VERSION "created by canmatrix"

NS_ :

BS_:

BU_: XCP_Tester FRS MN_K77
VAL_TABLE_ FRS_Fail 1 "FRS_RADAR_IS_WORKING" 0 "FRS_RADAR_ISNOT_WORKING" ;
VAL_TABLE_ FRS_MeasEnabled 1 "MEASUREMENT_ENABLED" 0 "MEASUREMENT_DISABLED" ;
VAL_TABLE_ FRS_ObjMotionPattern 7 "RESERVED" 6 "RESERVED" 5 "RESERVED" 4 "CROSSING" 3 "MOVING" 2 "STOPPED" 1 "STATIONARY" 0 "UNKNOWN" ;
VAL_TABLE_ FRS_Obj_ID 255 "INVALID" ;
VAL_TABLE_ FRS_Obj_MeasFlag 1 "OBJECT_EXTRAPOLATED_THIS_CYCLE" 0 "OBJECT_MEASURED_INTHIS_CYCLE" ;
VAL_TABLE_ FRS_Obj_Type 3 "PEDESTRAIN" 2 "TWO_WHEELER" 1 "FOUR_WHEELER" 0 "UNKNOWN" ;
VAL_TABLE_ FRS_Obj_UpdateFlag 1 "OBJECT_EXISTED_IN_PREVIOUS_CYCLE" 0 "NEW_OBJECT_INTHE_CYCLE" ;
VAL_TABLE_ FRS_Obj_ValidFlag 1 "OBJECT_VALID" 0 "OBJECT_INVALID" ;
VAL_TABLE_ FRS_Status_BlkProg 1 "FRS_IS_BLOCKED" 0 "FRS_IS_NOT_BLOCKED" ;
VAL_TABLE_ FRS_Status_HWErr 1 "HE_IS_FAILED" 0 "HW_IS_NOT_FAILED" ;
VAL_TABLE_ FRS_Status_MisAlign 7 "RESERVED" 6 "RESERVED" 5 "RESERVED" 4 "UNCALIBRATABLE" 3 "CALIBRATION_IN_PROGRESS" 2 "SENSOR_MISALIGNMENT_DETECTED" 1 "CALIBRATED" 0 "UNKNOWN" ;

BO_ 3221225472 VECTOR__INDEPENDENT_SIG_MSG: 0 Vector__XXX
 SG_ bkFramID : 0|32@0+ (1,0) [0|4294967295] "" Vector__XXX
 SG_ akFramID : 0|32@0+ (1,0) [0|4294967295] "" Vector__XXX
 SG_ mntAzmInFlash : 0|12@0- (0.01,0) [-20.48|20.47] "" Vector__XXX
 SG_ mntAzmRealTime : 0|12@0- (0.01,0) [-20.48|20.47] "" Vector__XXX
 SG_ RadarSubVehicle_VehilceType : 0|8@0+ (1,0) [0|15] "" Vector__XXX
 SG_ RadarSubVehicle_Yawrate : 0|16@0- (0.1,0) [-3276.8|3276.7] "deg/sec" Vector__XXX
 SG_ RadarSubVehicle_TurnSwitch : 0|2@0+ (1,0) [0|15] "" Vector__XXX
 SG_ RadarSubVehicle_Gear : 0|4@0+ (1,0) [0|15] "" Vector__XXX
 SG_ RadarSubVehicle_StrWheelAngle : 0|16@0- (0.05,0) [-1638.4|1638.35] "deg" Vector__XXX
 SG_ RadarSubVehicle_Speed : 0|16@0+ (0.01,0) [0|655.35] "m/s" Vector__XXX

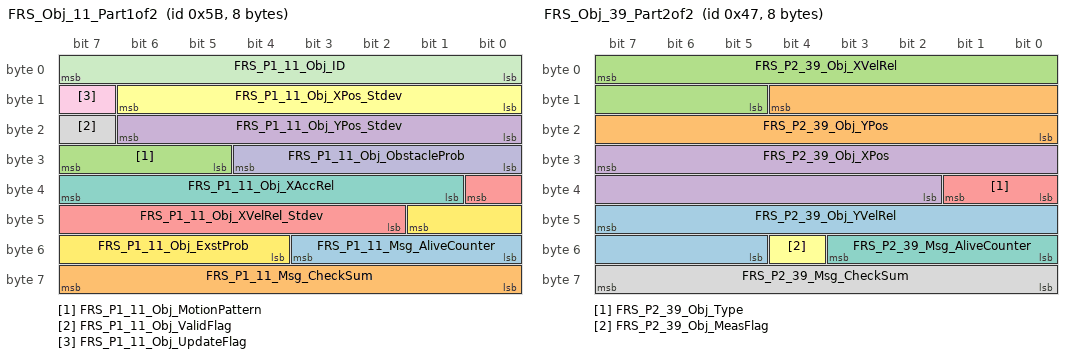
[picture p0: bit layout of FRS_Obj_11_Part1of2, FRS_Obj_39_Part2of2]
BO_ 91 FRS_Obj_11_Part1of2: 8 FRS
 SG_ FRS_P1_11_Msg_AliveCounter : 51|4@0+ (1,0) [0|15] "n/a" Vector__XXX
 SG_ FRS_P1_11_Msg_CheckSum : 63|8@0+ (1,0) [0|255] "n/a" Vector__XXX
 SG_ FRS_P1_11_Obj_MotionPattern : 31|3@0+ (1,0) [0|7] "n/a" Vector__XXX
 SG_ FRS_P1_11_Obj_YPos_Stdev : 22|7@0+ (0.1,0) [0|12.7] "m" Vector__XXX
 SG_ FRS_P1_11_Obj_XVelRel_Stdev : 32|7@0+ (0.05,0) [0|6.35] "m/s" Vector__XXX
 SG_ FRS_P1_11_Obj_XPos_Stdev : 14|7@0+ (0.1,0) [0|12.7] "m" Vector__XXX
 SG_ FRS_P1_11_Obj_XAccRel : 39|7@0+ (0.15,-9.6) [-9.6|9.45] "m/s2" Vector__XXX
 SG_ FRS_P1_11_Obj_ValidFlag : 23|1@0+ (1,0) [0|1] "n/a" Vector__XXX
 SG_ FRS_P1_11_Obj_UpdateFlag : 15|1@0+ (1,0) [0|1] "n/a" Vector__XXX
 SG_ FRS_P1_11_Obj_ObstacleProb : 28|5@0+ (3.2258,0) [0|99.9998] "%" Vector__XXX
 SG_ FRS_P1_11_Obj_ID : 7|8@0+ (1,0) [0|255] "n/a" Vector__XXX
 SG_ FRS_P1_11_Obj_ExstProb : 41|6@0+ (1.5873,0) [0|99.9999] "%" Vector__XXX

BO_ 71 FRS_Obj_39_Part2of2: 8 FRS
 SG_ FRS_P2_39_Obj_YVelRel : 47|11@0+ (0.1,-102.4) [-102.4|102.3] "m/s" Vector__XXX
 SG_ FRS_P2_39_Obj_YPos : 12|13@0+ (0.015625,-64) [-64|63.984375] "m" Vector__XXX
 SG_ FRS_P2_39_Obj_XVelRel : 7|11@0+ (0.1,-102.4) [-102.4|102.3] "m/s" Vector__XXX
 SG_ FRS_P2_39_Obj_XPos : 31|14@0+ (0.015625,0) [0|255.984375] "m" Vector__XXX
 SG_ FRS_P2_39_Obj_Type : 33|2@0+ (1,0) [0|3] "n/a" Vector__XXX
 SG_ FRS_P2_39_Obj_MeasFlag : 52|1@0+ (1,0) [0|1] "n/a" Vector__XXX
 SG_ FRS_P2_39_Msg_AliveCounter : 51|4@0+ (1,0) [0|15] "n/a" Vector__XXX
 SG_ FRS_P2_39_Msg_CheckSum : 63|8@0+ (1,0) [0|255] "n/a" Vector__XXX

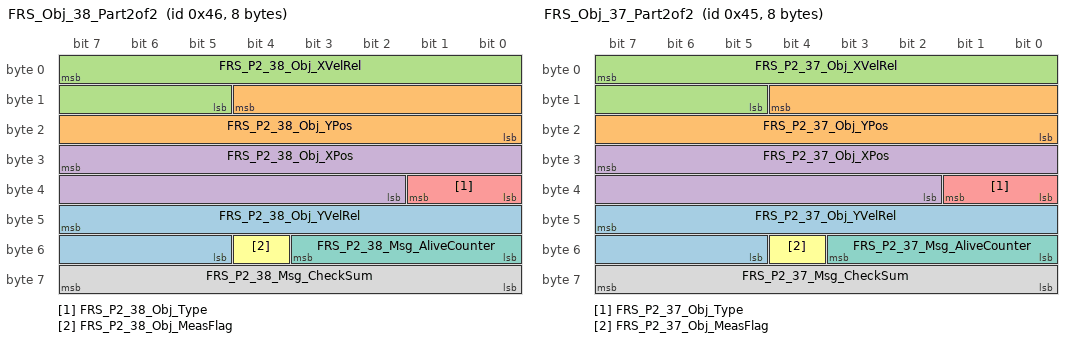
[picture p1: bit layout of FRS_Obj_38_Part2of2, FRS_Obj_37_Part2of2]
BO_ 70 FRS_Obj_38_Part2of2: 8 FRS
 SG_ FRS_P2_38_Obj_YVelRel : 47|11@0+ (0.1,-102.4) [-102.4|102.3] "m/s" Vector__XXX
 SG_ FRS_P2_38_Obj_YPos : 12|13@0+ (0.015625,-64) [-64|63.984375] "m" Vector__XXX
 SG_ FRS_P2_38_Obj_XVelRel : 7|11@0+ (0.1,-102.4) [-102.4|102.3] "m/s" Vector__XXX
 SG_ FRS_P2_38_Obj_XPos : 31|14@0+ (0.015625,0) [0|255.984375] "m" Vector__XXX
 SG_ FRS_P2_38_Obj_Type : 33|2@0+ (1,0) [0|3] "n/a" Vector__XXX
 SG_ FRS_P2_38_Obj_MeasFlag : 52|1@0+ (1,0) [0|1] "n/a" Vector__XXX
 SG_ FRS_P2_38_Msg_AliveCounter : 51|4@0+ (1,0) [0|15] "n/a" Vector__XXX
 SG_ FRS_P2_38_Msg_CheckSum : 63|8@0+ (1,0) [0|255] "n/a" Vector__XXX

BO_ 69 FRS_Obj_37_Part2of2: 8 FRS
 SG_ FRS_P2_37_Obj_YVelRel : 47|11@0+ (0.1,-102.4) [-102.4|102.3] "m/s" Vector__XXX
 SG_ FRS_P2_37_Obj_YPos : 12|13@0+ (0.015625,-64) [-64|63.984375] "m" Vector__XXX
 SG_ FRS_P2_37_Obj_XVelRel : 7|11@0+ (0.1,-102.4) [-102.4|102.3] "m/s" Vector__XXX
 SG_ FRS_P2_37_Obj_XPos : 31|14@0+ (0.015625,0) [0|255.984375] "m" Vector__XXX
 SG_ FRS_P2_37_Obj_Type : 33|2@0+ (1,0) [0|3] "n/a" Vector__XXX
 SG_ FRS_P2_37_Obj_MeasFlag : 52|1@0+ (1,0) [0|1] "n/a" Vector__XXX
 SG_ FRS_P2_37_Msg_AliveCounter : 51|4@0+ (1,0) [0|15] "n/a" Vector__XXX
 SG_ FRS_P2_37_Msg_CheckSum : 63|8@0+ (1,0) [0|255] "n/a" Vector__XXX

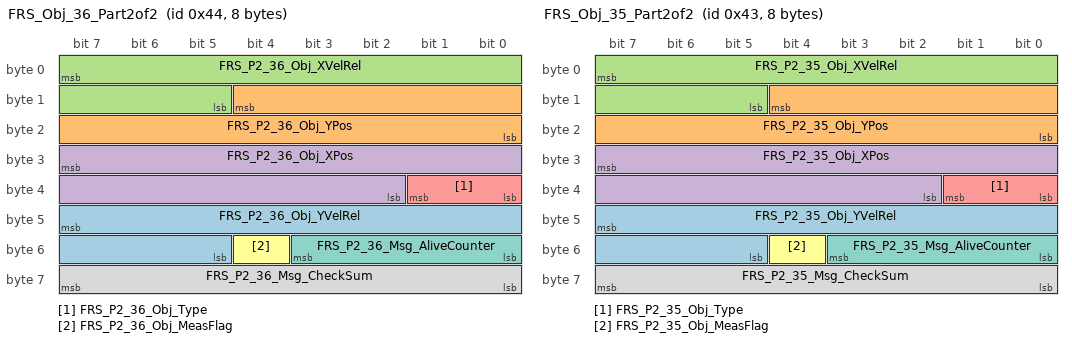
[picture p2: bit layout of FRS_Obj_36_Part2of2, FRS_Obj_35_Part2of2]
BO_ 68 FRS_Obj_36_Part2of2: 8 FRS
 SG_ FRS_P2_36_Obj_YVelRel : 47|11@0+ (0.1,-102.4) [-102.4|102.3] "m/s" Vector__XXX
 SG_ FRS_P2_36_Obj_YPos : 12|13@0+ (0.015625,-64) [-64|63.984375] "m" Vector__XXX
 SG_ FRS_P2_36_Obj_XVelRel : 7|11@0+ (0.1,-102.4) [-102.4|102.3] "m/s" Vector__XXX
 SG_ FRS_P2_36_Obj_XPos : 31|14@0+ (0.015625,0) [0|255.984375] "m" Vector__XXX
 SG_ FRS_P2_36_Obj_Type : 33|2@0+ (1,0) [0|3] "n/a" Vector__XXX
 SG_ FRS_P2_36_Obj_MeasFlag : 52|1@0+ (1,0) [0|1] "n/a" Vector__XXX
 SG_ FRS_P2_36_Msg_AliveCounter : 51|4@0+ (1,0) [0|15] "n/a" Vector__XXX
 SG_ FRS_P2_36_Msg_CheckSum : 63|8@0+ (1,0) [0|255] "n/a" Vector__XXX

BO_ 67 FRS_Obj_35_Part2of2: 8 FRS
 SG_ FRS_P2_35_Obj_YVelRel : 47|11@0+ (0.1,-102.4) [-102.4|102.3] "m/s" Vector__XXX
 SG_ FRS_P2_35_Obj_YPos : 12|13@0+ (0.015625,-64) [-64|63.984375] "m" Vector__XXX
 SG_ FRS_P2_35_Obj_XVelRel : 7|11@0+ (0.1,-102.4) [-102.4|102.3] "m/s" Vector__XXX
 SG_ FRS_P2_35_Obj_XPos : 31|14@0+ (0.015625,0) [0|255.984375] "m" Vector__XXX
 SG_ FRS_P2_35_Obj_Type : 33|2@0+ (1,0) [0|3] "n/a" Vector__XXX
 SG_ FRS_P2_35_Obj_MeasFlag : 52|1@0+ (1,0) [0|1] "n/a" Vector__XXX
 SG_ FRS_P2_35_Msg_AliveCounter : 51|4@0+ (1,0) [0|15] "n/a" Vector__XXX
 SG_ FRS_P2_35_Msg_CheckSum : 63|8@0+ (1,0) [0|255] "n/a" Vector__XXX

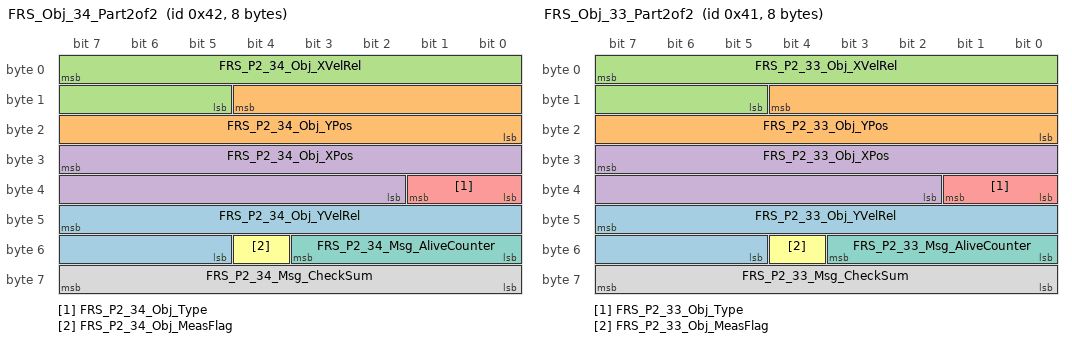
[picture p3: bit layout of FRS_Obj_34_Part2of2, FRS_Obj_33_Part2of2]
BO_ 66 FRS_Obj_34_Part2of2: 8 FRS
 SG_ FRS_P2_34_Obj_YVelRel : 47|11@0+ (0.1,-102.4) [-102.4|102.3] "m/s" Vector__XXX
 SG_ FRS_P2_34_Obj_YPos : 12|13@0+ (0.015625,-64) [-64|63.984375] "m" Vector__XXX
 SG_ FRS_P2_34_Obj_XVelRel : 7|11@0+ (0.1,-102.4) [-102.4|102.3] "m/s" Vector__XXX
 SG_ FRS_P2_34_Obj_XPos : 31|14@0+ (0.015625,0) [0|255.984375] "m" Vector__XXX
 SG_ FRS_P2_34_Obj_Type : 33|2@0+ (1,0) [0|3] "n/a" Vector__XXX
 SG_ FRS_P2_34_Obj_MeasFlag : 52|1@0+ (1,0) [0|1] "n/a" Vector__XXX
 SG_ FRS_P2_34_Msg_AliveCounter : 51|4@0+ (1,0) [0|15] "n/a" Vector__XXX
 SG_ FRS_P2_34_Msg_CheckSum : 63|8@0+ (1,0) [0|255] "n/a" Vector__XXX

BO_ 65 FRS_Obj_33_Part2of2: 8 FRS
 SG_ FRS_P2_33_Obj_YVelRel : 47|11@0+ (0.1,-102.4) [-102.4|102.3] "m/s" Vector__XXX
 SG_ FRS_P2_33_Obj_YPos : 12|13@0+ (0.015625,-64) [-64|63.984375] "m" Vector__XXX
 SG_ FRS_P2_33_Obj_XVelRel : 7|11@0+ (0.1,-102.4) [-102.4|102.3] "m/s" Vector__XXX
 SG_ FRS_P2_33_Obj_XPos : 31|14@0+ (0.015625,0) [0|255.984375] "m" Vector__XXX
 SG_ FRS_P2_33_Obj_Type : 33|2@0+ (1,0) [0|3] "n/a" Vector__XXX
 SG_ FRS_P2_33_Obj_MeasFlag : 52|1@0+ (1,0) [0|1] "n/a" Vector__XXX
 SG_ FRS_P2_33_Msg_AliveCounter : 51|4@0+ (1,0) [0|15] "n/a" Vector__XXX
 SG_ FRS_P2_33_Msg_CheckSum : 63|8@0+ (1,0) [0|255] "n/a" Vector__XXX

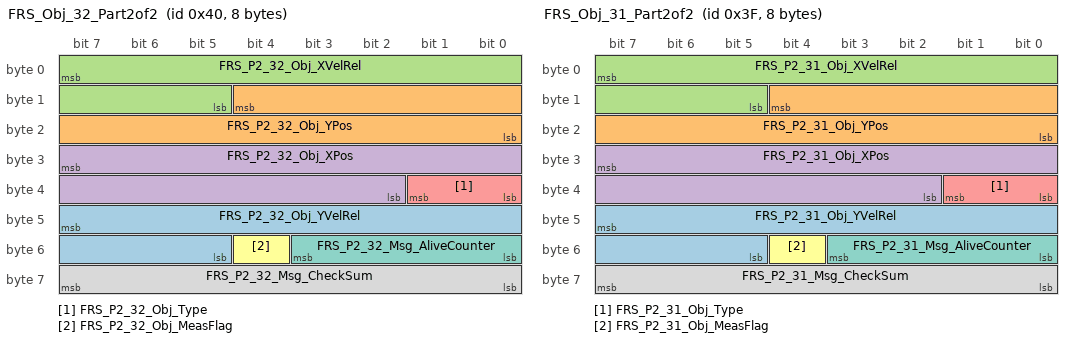
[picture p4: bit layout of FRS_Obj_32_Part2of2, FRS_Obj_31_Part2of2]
BO_ 64 FRS_Obj_32_Part2of2: 8 FRS
 SG_ FRS_P2_32_Obj_YVelRel : 47|11@0+ (0.1,-102.4) [-102.4|102.3] "m/s" Vector__XXX
 SG_ FRS_P2_32_Obj_YPos : 12|13@0+ (0.015625,-64) [-64|63.984375] "m" Vector__XXX
 SG_ FRS_P2_32_Obj_XVelRel : 7|11@0+ (0.1,-102.4) [-102.4|102.3] "m/s" Vector__XXX
 SG_ FRS_P2_32_Obj_XPos : 31|14@0+ (0.015625,0) [0|255.984375] "m" Vector__XXX
 SG_ FRS_P2_32_Obj_Type : 33|2@0+ (1,0) [0|3] "n/a" Vector__XXX
 SG_ FRS_P2_32_Obj_MeasFlag : 52|1@0+ (1,0) [0|1] "n/a" Vector__XXX
 SG_ FRS_P2_32_Msg_AliveCounter : 51|4@0+ (1,0) [0|15] "n/a" Vector__XXX
 SG_ FRS_P2_32_Msg_CheckSum : 63|8@0+ (1,0) [0|255] "n/a" Vector__XXX

BO_ 63 FRS_Obj_31_Part2of2: 8 FRS
 SG_ FRS_P2_31_Obj_YVelRel : 47|11@0+ (0.1,-102.4) [-102.4|102.3] "m/s" Vector__XXX
 SG_ FRS_P2_31_Obj_YPos : 12|13@0+ (0.015625,-64) [-64|63.984375] "m" Vector__XXX
 SG_ FRS_P2_31_Obj_XVelRel : 7|11@0+ (0.1,-102.4) [-102.4|102.3] "m/s" Vector__XXX
 SG_ FRS_P2_31_Obj_XPos : 31|14@0+ (0.015625,0) [0|255.984375] "m" Vector__XXX
 SG_ FRS_P2_31_Obj_Type : 33|2@0+ (1,0) [0|3] "n/a" Vector__XXX
 SG_ FRS_P2_31_Obj_MeasFlag : 52|1@0+ (1,0) [0|1] "n/a" Vector__XXX
 SG_ FRS_P2_31_Msg_AliveCounter : 51|4@0+ (1,0) [0|15] "n/a" Vector__XXX
 SG_ FRS_P2_31_Msg_CheckSum : 63|8@0+ (1,0) [0|255] "n/a" Vector__XXX

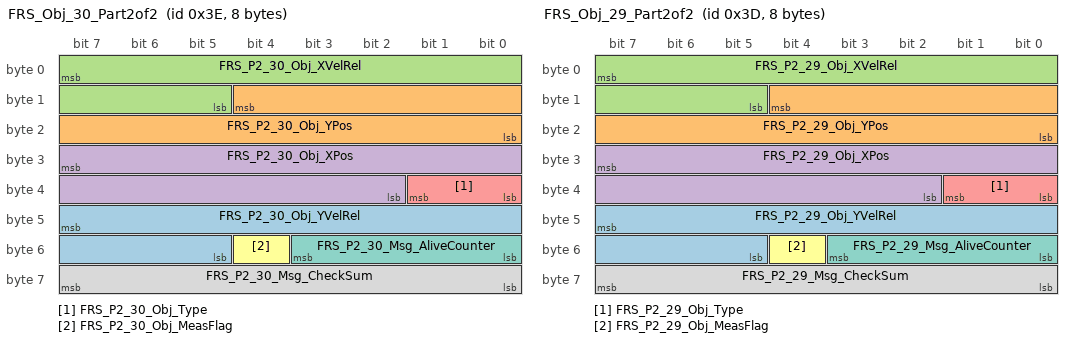
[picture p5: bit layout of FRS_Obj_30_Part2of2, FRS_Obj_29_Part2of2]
BO_ 62 FRS_Obj_30_Part2of2: 8 FRS
 SG_ FRS_P2_30_Obj_YVelRel : 47|11@0+ (0.1,-102.4) [-102.4|102.3] "m/s" Vector__XXX
 SG_ FRS_P2_30_Obj_YPos : 12|13@0+ (0.015625,-64) [-64|63.984375] "m" Vector__XXX
 SG_ FRS_P2_30_Obj_XVelRel : 7|11@0+ (0.1,-102.4) [-102.4|102.3] "m/s" Vector__XXX
 SG_ FRS_P2_30_Obj_XPos : 31|14@0+ (0.015625,0) [0|255.984375] "m" Vector__XXX
 SG_ FRS_P2_30_Obj_Type : 33|2@0+ (1,0) [0|3] "n/a" Vector__XXX
 SG_ FRS_P2_30_Obj_MeasFlag : 52|1@0+ (1,0) [0|1] "n/a" Vector__XXX
 SG_ FRS_P2_30_Msg_AliveCounter : 51|4@0+ (1,0) [0|15] "n/a" Vector__XXX
 SG_ FRS_P2_30_Msg_CheckSum : 63|8@0+ (1,0) [0|255] "n/a" Vector__XXX

BO_ 61 FRS_Obj_29_Part2of2: 8 FRS
 SG_ FRS_P2_29_Obj_YVelRel : 47|11@0+ (0.1,-102.4) [-102.4|102.3] "m/s" Vector__XXX
 SG_ FRS_P2_29_Obj_YPos : 12|13@0+ (0.015625,-64) [-64|63.984375] "m" Vector__XXX
 SG_ FRS_P2_29_Obj_XVelRel : 7|11@0+ (0.1,-102.4) [-102.4|102.3] "m/s" Vector__XXX
 SG_ FRS_P2_29_Obj_XPos : 31|14@0+ (0.015625,0) [0|255.984375] "m" Vector__XXX
 SG_ FRS_P2_29_Obj_Type : 33|2@0+ (1,0) [0|3] "n/a" Vector__XXX
 SG_ FRS_P2_29_Obj_MeasFlag : 52|1@0+ (1,0) [0|1] "n/a" Vector__XXX
 SG_ FRS_P2_29_Msg_AliveCounter : 51|4@0+ (1,0) [0|15] "n/a" Vector__XXX
 SG_ FRS_P2_29_Msg_CheckSum : 63|8@0+ (1,0) [0|255] "n/a" Vector__XXX

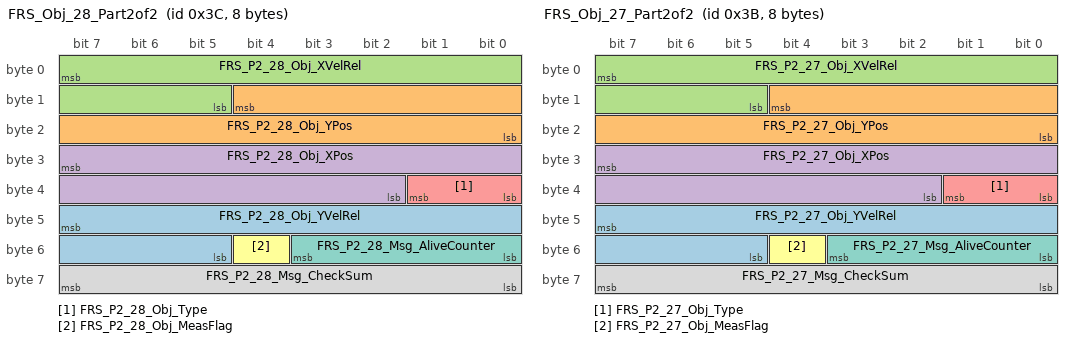
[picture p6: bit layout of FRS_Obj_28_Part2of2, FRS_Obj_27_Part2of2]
BO_ 60 FRS_Obj_28_Part2of2: 8 FRS
 SG_ FRS_P2_28_Obj_YVelRel : 47|11@0+ (0.1,-102.4) [-102.4|102.3] "m/s" Vector__XXX
 SG_ FRS_P2_28_Obj_YPos : 12|13@0+ (0.015625,-64) [-64|63.984375] "m" Vector__XXX
 SG_ FRS_P2_28_Obj_XVelRel : 7|11@0+ (0.1,-102.4) [-102.4|102.3] "m/s" Vector__XXX
 SG_ FRS_P2_28_Obj_XPos : 31|14@0+ (0.015625,0) [0|255.984375] "m" Vector__XXX
 SG_ FRS_P2_28_Obj_Type : 33|2@0+ (1,0) [0|3] "n/a" Vector__XXX
 SG_ FRS_P2_28_Obj_MeasFlag : 52|1@0+ (1,0) [0|1] "n/a" Vector__XXX
 SG_ FRS_P2_28_Msg_AliveCounter : 51|4@0+ (1,0) [0|15] "n/a" Vector__XXX
 SG_ FRS_P2_28_Msg_CheckSum : 63|8@0+ (1,0) [0|255] "n/a" Vector__XXX

BO_ 59 FRS_Obj_27_Part2of2: 8 FRS
 SG_ FRS_P2_27_Obj_YVelRel : 47|11@0+ (0.1,-102.4) [-102.4|102.3] "m/s" Vector__XXX
 SG_ FRS_P2_27_Obj_YPos : 12|13@0+ (0.015625,-64) [-64|63.984375] "m" Vector__XXX
 SG_ FRS_P2_27_Obj_XVelRel : 7|11@0+ (0.1,-102.4) [-102.4|102.3] "m/s" Vector__XXX
 SG_ FRS_P2_27_Obj_XPos : 31|14@0+ (0.015625,0) [0|255.984375] "m" Vector__XXX
 SG_ FRS_P2_27_Obj_Type : 33|2@0+ (1,0) [0|3] "n/a" Vector__XXX
 SG_ FRS_P2_27_Obj_MeasFlag : 52|1@0+ (1,0) [0|1] "n/a" Vector__XXX
 SG_ FRS_P2_27_Msg_AliveCounter : 51|4@0+ (1,0) [0|15] "n/a" Vector__XXX
 SG_ FRS_P2_27_Msg_CheckSum : 63|8@0+ (1,0) [0|255] "n/a" Vector__XXX

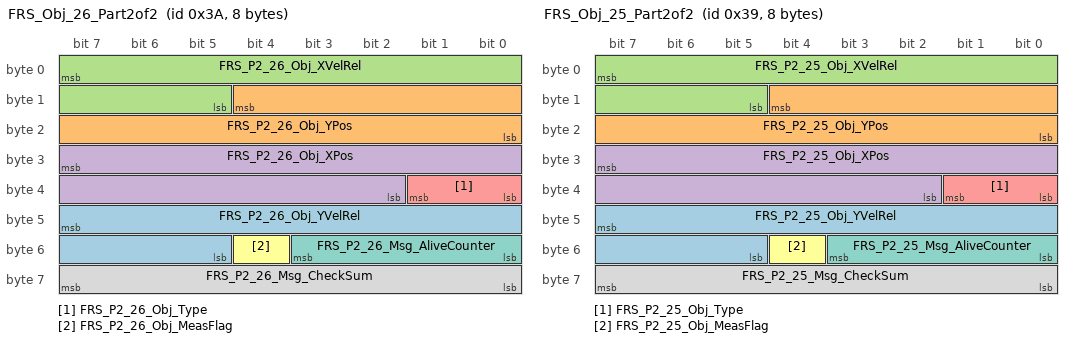
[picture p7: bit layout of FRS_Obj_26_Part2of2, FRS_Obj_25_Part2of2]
BO_ 58 FRS_Obj_26_Part2of2: 8 FRS
 SG_ FRS_P2_26_Obj_YVelRel : 47|11@0+ (0.1,-102.4) [-102.4|102.3] "m/s" Vector__XXX
 SG_ FRS_P2_26_Obj_YPos : 12|13@0+ (0.015625,-64) [-64|63.984375] "m" Vector__XXX
 SG_ FRS_P2_26_Obj_XVelRel : 7|11@0+ (0.1,-102.4) [-102.4|102.3] "m/s" Vector__XXX
 SG_ FRS_P2_26_Obj_XPos : 31|14@0+ (0.015625,0) [0|255.984375] "m" Vector__XXX
 SG_ FRS_P2_26_Obj_Type : 33|2@0+ (1,0) [0|3] "n/a" Vector__XXX
 SG_ FRS_P2_26_Obj_MeasFlag : 52|1@0+ (1,0) [0|1] "n/a" Vector__XXX
 SG_ FRS_P2_26_Msg_AliveCounter : 51|4@0+ (1,0) [0|15] "n/a" Vector__XXX
 SG_ FRS_P2_26_Msg_CheckSum : 63|8@0+ (1,0) [0|255] "n/a" Vector__XXX

BO_ 57 FRS_Obj_25_Part2of2: 8 FRS
 SG_ FRS_P2_25_Obj_YVelRel : 47|11@0+ (0.1,-102.4) [-102.4|102.3] "m/s" Vector__XXX
 SG_ FRS_P2_25_Obj_YPos : 12|13@0+ (0.015625,-64) [-64|63.984375] "m" Vector__XXX
 SG_ FRS_P2_25_Obj_XVelRel : 7|11@0+ (0.1,-102.4) [-102.4|102.3] "m/s" Vector__XXX
 SG_ FRS_P2_25_Obj_XPos : 31|14@0+ (0.015625,0) [0|255.984375] "m" Vector__XXX
 SG_ FRS_P2_25_Obj_Type : 33|2@0+ (1,0) [0|3] "n/a" Vector__XXX
 SG_ FRS_P2_25_Obj_MeasFlag : 52|1@0+ (1,0) [0|1] "n/a" Vector__XXX
 SG_ FRS_P2_25_Msg_AliveCounter : 51|4@0+ (1,0) [0|15] "n/a" Vector__XXX
 SG_ FRS_P2_25_Msg_CheckSum : 63|8@0+ (1,0) [0|255] "n/a" Vector__XXX

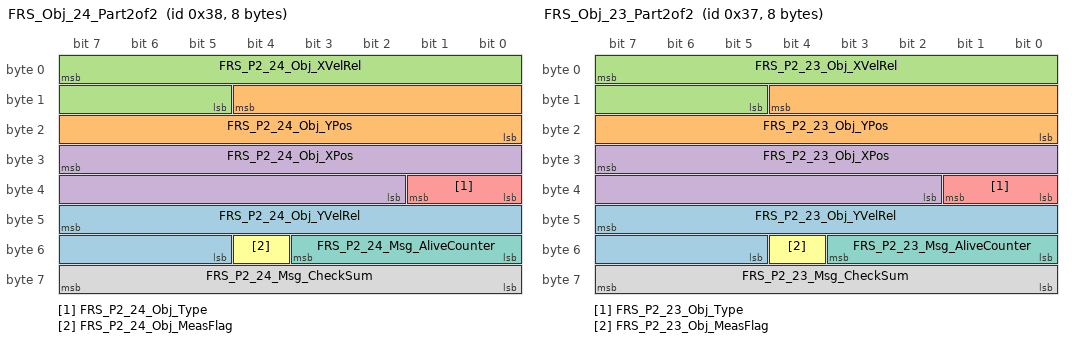
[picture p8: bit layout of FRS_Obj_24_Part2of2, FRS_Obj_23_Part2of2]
BO_ 56 FRS_Obj_24_Part2of2: 8 FRS
 SG_ FRS_P2_24_Obj_YVelRel : 47|11@0+ (0.1,-102.4) [-102.4|102.3] "m/s" Vector__XXX
 SG_ FRS_P2_24_Obj_YPos : 12|13@0+ (0.015625,-64) [-64|63.984375] "m" Vector__XXX
 SG_ FRS_P2_24_Obj_XVelRel : 7|11@0+ (0.1,-102.4) [-102.4|102.3] "m/s" Vector__XXX
 SG_ FRS_P2_24_Obj_XPos : 31|14@0+ (0.015625,0) [0|255.984375] "m" Vector__XXX
 SG_ FRS_P2_24_Obj_Type : 33|2@0+ (1,0) [0|3] "n/a" Vector__XXX
 SG_ FRS_P2_24_Obj_MeasFlag : 52|1@0+ (1,0) [0|1] "n/a" Vector__XXX
 SG_ FRS_P2_24_Msg_AliveCounter : 51|4@0+ (1,0) [0|15] "n/a" Vector__XXX
 SG_ FRS_P2_24_Msg_CheckSum : 63|8@0+ (1,0) [0|255] "n/a" Vector__XXX

BO_ 55 FRS_Obj_23_Part2of2: 8 FRS
 SG_ FRS_P2_23_Obj_YVelRel : 47|11@0+ (0.1,-102.4) [-102.4|102.3] "m/s" Vector__XXX
 SG_ FRS_P2_23_Obj_YPos : 12|13@0+ (0.015625,-64) [-64|63.984375] "m" Vector__XXX
 SG_ FRS_P2_23_Obj_XVelRel : 7|11@0+ (0.1,-102.4) [-102.4|102.3] "m/s" Vector__XXX
 SG_ FRS_P2_23_Obj_XPos : 31|14@0+ (0.015625,0) [0|255.984375] "m" Vector__XXX
 SG_ FRS_P2_23_Obj_Type : 33|2@0+ (1,0) [0|3] "n/a" Vector__XXX
 SG_ FRS_P2_23_Obj_MeasFlag : 52|1@0+ (1,0) [0|1] "n/a" Vector__XXX
 SG_ FRS_P2_23_Msg_AliveCounter : 51|4@0+ (1,0) [0|15] "n/a" Vector__XXX
 SG_ FRS_P2_23_Msg_CheckSum : 63|8@0+ (1,0) [0|255] "n/a" Vector__XXX

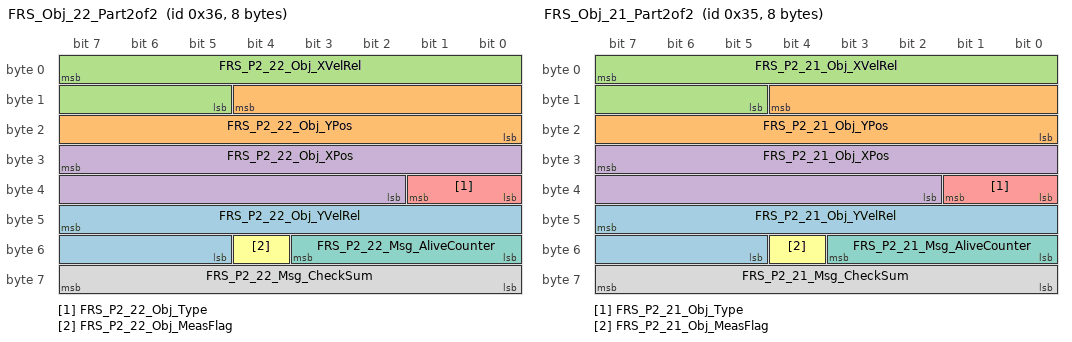
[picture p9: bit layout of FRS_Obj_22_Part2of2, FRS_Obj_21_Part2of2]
BO_ 54 FRS_Obj_22_Part2of2: 8 FRS
 SG_ FRS_P2_22_Obj_YVelRel : 47|11@0+ (0.1,-102.4) [-102.4|102.3] "m/s" Vector__XXX
 SG_ FRS_P2_22_Obj_YPos : 12|13@0+ (0.015625,-64) [-64|63.984375] "m" Vector__XXX
 SG_ FRS_P2_22_Obj_XVelRel : 7|11@0+ (0.1,-102.4) [-102.4|102.3] "m/s" Vector__XXX
 SG_ FRS_P2_22_Obj_XPos : 31|14@0+ (0.015625,0) [0|255.984375] "m" Vector__XXX
 SG_ FRS_P2_22_Obj_Type : 33|2@0+ (1,0) [0|3] "n/a" Vector__XXX
 SG_ FRS_P2_22_Obj_MeasFlag : 52|1@0+ (1,0) [0|1] "n/a" Vector__XXX
 SG_ FRS_P2_22_Msg_AliveCounter : 51|4@0+ (1,0) [0|15] "n/a" Vector__XXX
 SG_ FRS_P2_22_Msg_CheckSum : 63|8@0+ (1,0) [0|255] "n/a" Vector__XXX

BO_ 53 FRS_Obj_21_Part2of2: 8 FRS
 SG_ FRS_P2_21_Obj_YVelRel : 47|11@0+ (0.1,-102.4) [-102.4|102.3] "m/s" Vector__XXX
 SG_ FRS_P2_21_Obj_YPos : 12|13@0+ (0.015625,-64) [-64|63.984375] "m" Vector__XXX
 SG_ FRS_P2_21_Obj_XVelRel : 7|11@0+ (0.1,-102.4) [-102.4|102.3] "m/s" Vector__XXX
 SG_ FRS_P2_21_Obj_XPos : 31|14@0+ (0.015625,0) [0|255.984375] "m" Vector__XXX
 SG_ FRS_P2_21_Obj_Type : 33|2@0+ (1,0) [0|3] "n/a" Vector__XXX
 SG_ FRS_P2_21_Obj_MeasFlag : 52|1@0+ (1,0) [0|1] "n/a" Vector__XXX
 SG_ FRS_P2_21_Msg_AliveCounter : 51|4@0+ (1,0) [0|15] "n/a" Vector__XXX
 SG_ FRS_P2_21_Msg_CheckSum : 63|8@0+ (1,0) [0|255] "n/a" Vector__XXX

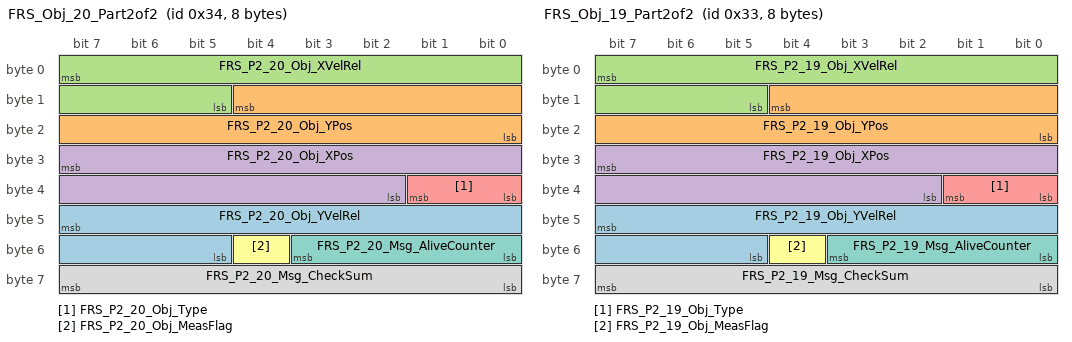
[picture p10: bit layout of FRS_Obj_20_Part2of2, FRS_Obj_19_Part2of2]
BO_ 52 FRS_Obj_20_Part2of2: 8 FRS
 SG_ FRS_P2_20_Obj_YVelRel : 47|11@0+ (0.1,-102.4) [-102.4|102.3] "m/s" Vector__XXX
 SG_ FRS_P2_20_Obj_YPos : 12|13@0+ (0.015625,-64) [-64|63.984375] "m" Vector__XXX
 SG_ FRS_P2_20_Obj_XVelRel : 7|11@0+ (0.1,-102.4) [-102.4|102.3] "m/s" Vector__XXX
 SG_ FRS_P2_20_Obj_XPos : 31|14@0+ (0.015625,0) [0|255.984375] "m" Vector__XXX
 SG_ FRS_P2_20_Obj_Type : 33|2@0+ (1,0) [0|3] "n/a" Vector__XXX
 SG_ FRS_P2_20_Obj_MeasFlag : 52|1@0+ (1,0) [0|1] "n/a" Vector__XXX
 SG_ FRS_P2_20_Msg_AliveCounter : 51|4@0+ (1,0) [0|15] "n/a" Vector__XXX
 SG_ FRS_P2_20_Msg_CheckSum : 63|8@0+ (1,0) [0|255] "n/a" Vector__XXX

BO_ 51 FRS_Obj_19_Part2of2: 8 FRS
 SG_ FRS_P2_19_Obj_YVelRel : 47|11@0+ (0.1,-102.4) [-102.4|102.3] "m/s" Vector__XXX
 SG_ FRS_P2_19_Obj_YPos : 12|13@0+ (0.015625,-64) [-64|63.984375] "m" Vector__XXX
 SG_ FRS_P2_19_Obj_XVelRel : 7|11@0+ (0.1,-102.4) [-102.4|102.3] "m/s" Vector__XXX
 SG_ FRS_P2_19_Obj_XPos : 31|14@0+ (0.015625,0) [0|255.984375] "m" Vector__XXX
 SG_ FRS_P2_19_Obj_Type : 33|2@0+ (1,0) [0|3] "n/a" Vector__XXX
 SG_ FRS_P2_19_Obj_MeasFlag : 52|1@0+ (1,0) [0|1] "n/a" Vector__XXX
 SG_ FRS_P2_19_Msg_AliveCounter : 51|4@0+ (1,0) [0|15] "n/a" Vector__XXX
 SG_ FRS_P2_19_Msg_CheckSum : 63|8@0+ (1,0) [0|255] "n/a" Vector__XXX

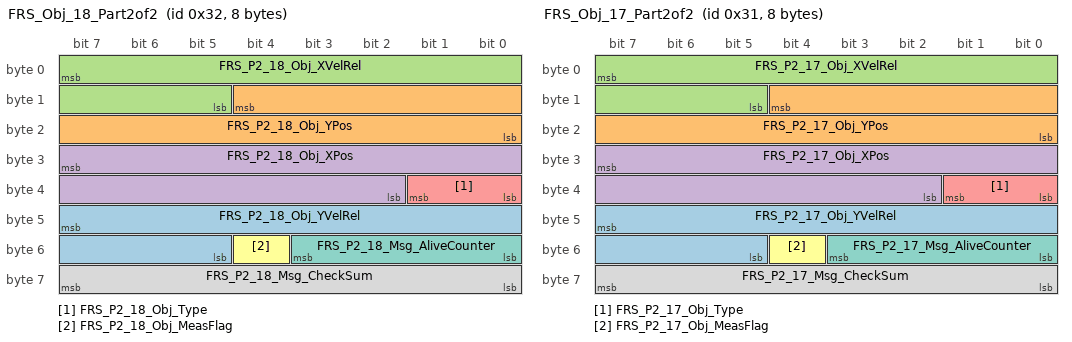
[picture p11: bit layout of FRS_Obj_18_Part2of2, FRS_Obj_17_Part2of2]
BO_ 50 FRS_Obj_18_Part2of2: 8 FRS
 SG_ FRS_P2_18_Obj_YVelRel : 47|11@0+ (0.1,-102.4) [-102.4|102.3] "m/s" Vector__XXX
 SG_ FRS_P2_18_Obj_YPos : 12|13@0+ (0.015625,-64) [-64|63.984375] "m" Vector__XXX
 SG_ FRS_P2_18_Obj_XVelRel : 7|11@0+ (0.1,-102.4) [-102.4|102.3] "m/s" Vector__XXX
 SG_ FRS_P2_18_Obj_XPos : 31|14@0+ (0.015625,0) [0|255.984375] "m" Vector__XXX
 SG_ FRS_P2_18_Obj_Type : 33|2@0+ (1,0) [0|3] "n/a" Vector__XXX
 SG_ FRS_P2_18_Obj_MeasFlag : 52|1@0+ (1,0) [0|1] "n/a" Vector__XXX
 SG_ FRS_P2_18_Msg_AliveCounter : 51|4@0+ (1,0) [0|15] "n/a" Vector__XXX
 SG_ FRS_P2_18_Msg_CheckSum : 63|8@0+ (1,0) [0|255] "n/a" Vector__XXX

BO_ 49 FRS_Obj_17_Part2of2: 8 FRS
 SG_ FRS_P2_17_Obj_YVelRel : 47|11@0+ (0.1,-102.4) [-102.4|102.3] "m/s" Vector__XXX
 SG_ FRS_P2_17_Obj_YPos : 12|13@0+ (0.015625,-64) [-64|63.984375] "m" Vector__XXX
 SG_ FRS_P2_17_Obj_XVelRel : 7|11@0+ (0.1,-102.4) [-102.4|102.3] "m/s" Vector__XXX
 SG_ FRS_P2_17_Obj_XPos : 31|14@0+ (0.015625,0) [0|255.984375] "m" Vector__XXX
 SG_ FRS_P2_17_Obj_Type : 33|2@0+ (1,0) [0|3] "n/a" Vector__XXX
 SG_ FRS_P2_17_Obj_MeasFlag : 52|1@0+ (1,0) [0|1] "n/a" Vector__XXX
 SG_ FRS_P2_17_Msg_AliveCounter : 51|4@0+ (1,0) [0|15] "n/a" Vector__XXX
 SG_ FRS_P2_17_Msg_CheckSum : 63|8@0+ (1,0) [0|255] "n/a" Vector__XXX

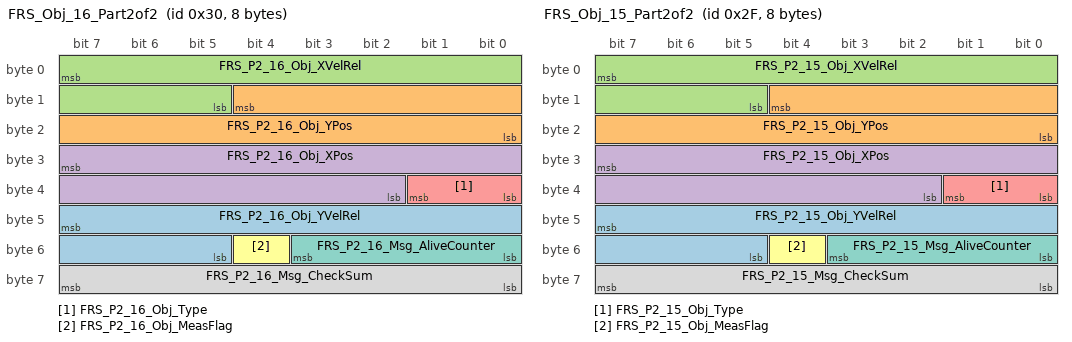
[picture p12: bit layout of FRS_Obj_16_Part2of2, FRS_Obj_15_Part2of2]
BO_ 48 FRS_Obj_16_Part2of2: 8 FRS
 SG_ FRS_P2_16_Obj_YVelRel : 47|11@0+ (0.1,-102.4) [-102.4|102.3] "m/s" Vector__XXX
 SG_ FRS_P2_16_Obj_YPos : 12|13@0+ (0.015625,-64) [-64|63.984375] "m" Vector__XXX
 SG_ FRS_P2_16_Obj_XVelRel : 7|11@0+ (0.1,-102.4) [-102.4|102.3] "m/s" Vector__XXX
 SG_ FRS_P2_16_Obj_XPos : 31|14@0+ (0.015625,0) [0|255.984375] "m" Vector__XXX
 SG_ FRS_P2_16_Obj_Type : 33|2@0+ (1,0) [0|3] "n/a" Vector__XXX
 SG_ FRS_P2_16_Obj_MeasFlag : 52|1@0+ (1,0) [0|1] "n/a" Vector__XXX
 SG_ FRS_P2_16_Msg_AliveCounter : 51|4@0+ (1,0) [0|15] "n/a" Vector__XXX
 SG_ FRS_P2_16_Msg_CheckSum : 63|8@0+ (1,0) [0|255] "n/a" Vector__XXX

BO_ 47 FRS_Obj_15_Part2of2: 8 FRS
 SG_ FRS_P2_15_Obj_YVelRel : 47|11@0+ (0.1,-102.4) [-102.4|102.3] "m/s" Vector__XXX
 SG_ FRS_P2_15_Obj_YPos : 12|13@0+ (0.015625,-64) [-64|63.984375] "m" Vector__XXX
 SG_ FRS_P2_15_Obj_XVelRel : 7|11@0+ (0.1,-102.4) [-102.4|102.3] "m/s" Vector__XXX
 SG_ FRS_P2_15_Obj_XPos : 31|14@0+ (0.015625,0) [0|255.984375] "m" Vector__XXX
 SG_ FRS_P2_15_Obj_Type : 33|2@0+ (1,0) [0|3] "n/a" Vector__XXX
 SG_ FRS_P2_15_Obj_MeasFlag : 52|1@0+ (1,0) [0|1] "n/a" Vector__XXX
 SG_ FRS_P2_15_Msg_AliveCounter : 51|4@0+ (1,0) [0|15] "n/a" Vector__XXX
 SG_ FRS_P2_15_Msg_CheckSum : 63|8@0+ (1,0) [0|255] "n/a" Vector__XXX

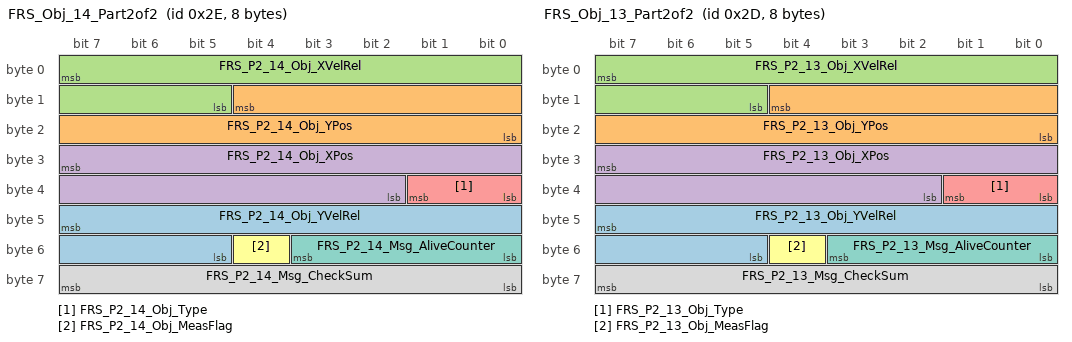
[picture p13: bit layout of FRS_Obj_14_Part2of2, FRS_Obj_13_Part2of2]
BO_ 46 FRS_Obj_14_Part2of2: 8 FRS
 SG_ FRS_P2_14_Obj_YVelRel : 47|11@0+ (0.1,-102.4) [-102.4|102.3] "m/s" Vector__XXX
 SG_ FRS_P2_14_Obj_YPos : 12|13@0+ (0.015625,-64) [-64|63.984375] "m" Vector__XXX
 SG_ FRS_P2_14_Obj_XVelRel : 7|11@0+ (0.1,-102.4) [-102.4|102.3] "m/s" Vector__XXX
 SG_ FRS_P2_14_Obj_XPos : 31|14@0+ (0.015625,0) [0|255.984375] "m" Vector__XXX
 SG_ FRS_P2_14_Obj_Type : 33|2@0+ (1,0) [0|3] "n/a" Vector__XXX
 SG_ FRS_P2_14_Obj_MeasFlag : 52|1@0+ (1,0) [0|1] "n/a" Vector__XXX
 SG_ FRS_P2_14_Msg_AliveCounter : 51|4@0+ (1,0) [0|15] "n/a" Vector__XXX
 SG_ FRS_P2_14_Msg_CheckSum : 63|8@0+ (1,0) [0|255] "n/a" Vector__XXX

BO_ 45 FRS_Obj_13_Part2of2: 8 FRS
 SG_ FRS_P2_13_Obj_YVelRel : 47|11@0+ (0.1,-102.4) [-102.4|102.3] "m/s" Vector__XXX
 SG_ FRS_P2_13_Obj_YPos : 12|13@0+ (0.015625,-64) [-64|63.984375] "m" Vector__XXX
 SG_ FRS_P2_13_Obj_XVelRel : 7|11@0+ (0.1,-102.4) [-102.4|102.3] "m/s" Vector__XXX
 SG_ FRS_P2_13_Obj_XPos : 31|14@0+ (0.015625,0) [0|255.984375] "m" Vector__XXX
 SG_ FRS_P2_13_Obj_Type : 33|2@0+ (1,0) [0|3] "n/a" Vector__XXX
 SG_ FRS_P2_13_Obj_MeasFlag : 52|1@0+ (1,0) [0|1] "n/a" Vector__XXX
 SG_ FRS_P2_13_Msg_AliveCounter : 51|4@0+ (1,0) [0|15] "n/a" Vector__XXX
 SG_ FRS_P2_13_Msg_CheckSum : 63|8@0+ (1,0) [0|255] "n/a" Vector__XXX

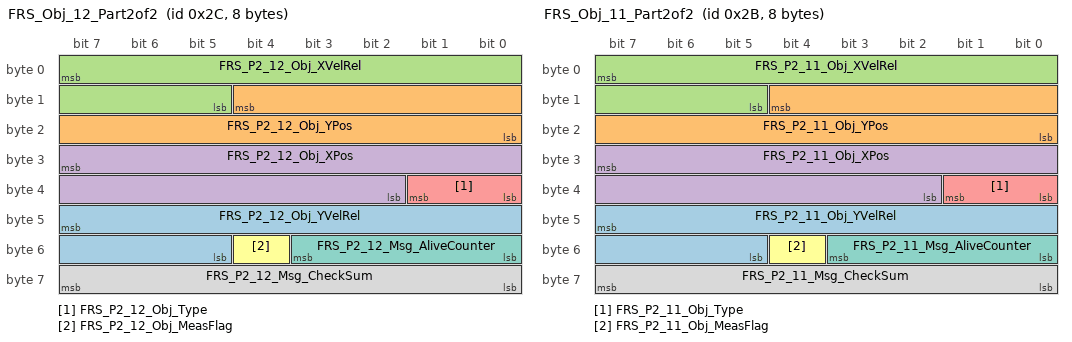
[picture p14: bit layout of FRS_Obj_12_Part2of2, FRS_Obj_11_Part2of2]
BO_ 44 FRS_Obj_12_Part2of2: 8 FRS
 SG_ FRS_P2_12_Obj_YVelRel : 47|11@0+ (0.1,-102.4) [-102.4|102.3] "m/s" Vector__XXX
 SG_ FRS_P2_12_Obj_YPos : 12|13@0+ (0.015625,-64) [-64|63.984375] "m" Vector__XXX
 SG_ FRS_P2_12_Obj_XVelRel : 7|11@0+ (0.1,-102.4) [-102.4|102.3] "m/s" Vector__XXX
 SG_ FRS_P2_12_Obj_XPos : 31|14@0+ (0.015625,0) [0|255.984375] "m" Vector__XXX
 SG_ FRS_P2_12_Obj_Type : 33|2@0+ (1,0) [0|3] "n/a" Vector__XXX
 SG_ FRS_P2_12_Obj_MeasFlag : 52|1@0+ (1,0) [0|1] "n/a" Vector__XXX
 SG_ FRS_P2_12_Msg_AliveCounter : 51|4@0+ (1,0) [0|15] "n/a" Vector__XXX
 SG_ FRS_P2_12_Msg_CheckSum : 63|8@0+ (1,0) [0|255] "n/a" Vector__XXX

BO_ 43 FRS_Obj_11_Part2of2: 8 FRS
 SG_ FRS_P2_11_Obj_YVelRel : 47|11@0+ (0.1,-102.4) [-102.4|102.3] "m/s" Vector__XXX
 SG_ FRS_P2_11_Obj_YPos : 12|13@0+ (0.015625,-64) [-64|63.984375] "m" Vector__XXX
 SG_ FRS_P2_11_Obj_XVelRel : 7|11@0+ (0.1,-102.4) [-102.4|102.3] "m/s" Vector__XXX
 SG_ FRS_P2_11_Obj_XPos : 31|14@0+ (0.015625,0) [0|255.984375] "m" Vector__XXX
 SG_ FRS_P2_11_Obj_Type : 33|2@0+ (1,0) [0|3] "n/a" Vector__XXX
 SG_ FRS_P2_11_Obj_MeasFlag : 52|1@0+ (1,0) [0|1] "n/a" Vector__XXX
 SG_ FRS_P2_11_Msg_AliveCounter : 51|4@0+ (1,0) [0|15] "n/a" Vector__XXX
 SG_ FRS_P2_11_Msg_CheckSum : 63|8@0+ (1,0) [0|255] "n/a" Vector__XXX

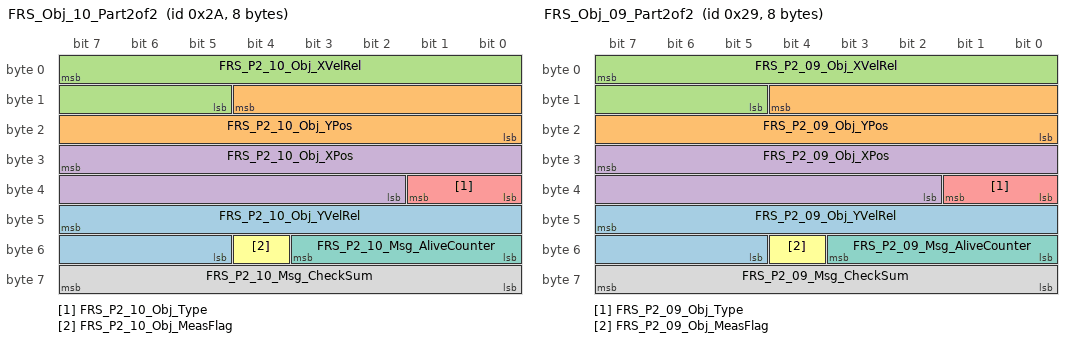
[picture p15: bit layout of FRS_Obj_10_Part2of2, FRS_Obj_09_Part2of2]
BO_ 42 FRS_Obj_10_Part2of2: 8 FRS
 SG_ FRS_P2_10_Obj_YVelRel : 47|11@0+ (0.1,-102.4) [-102.4|102.3] "m/s" Vector__XXX
 SG_ FRS_P2_10_Obj_YPos : 12|13@0+ (0.015625,-64) [-64|63.984375] "m" Vector__XXX
 SG_ FRS_P2_10_Obj_XVelRel : 7|11@0+ (0.1,-102.4) [-102.4|102.3] "m/s" Vector__XXX
 SG_ FRS_P2_10_Obj_XPos : 31|14@0+ (0.015625,0) [0|255.984375] "m" Vector__XXX
 SG_ FRS_P2_10_Obj_Type : 33|2@0+ (1,0) [0|3] "n/a" Vector__XXX
 SG_ FRS_P2_10_Obj_MeasFlag : 52|1@0+ (1,0) [0|1] "n/a" Vector__XXX
 SG_ FRS_P2_10_Msg_AliveCounter : 51|4@0+ (1,0) [0|15] "n/a" Vector__XXX
 SG_ FRS_P2_10_Msg_CheckSum : 63|8@0+ (1,0) [0|255] "n/a" Vector__XXX

BO_ 41 FRS_Obj_09_Part2of2: 8 FRS
 SG_ FRS_P2_09_Obj_YVelRel : 47|11@0+ (0.1,-102.4) [-102.4|102.3] "m/s" Vector__XXX
 SG_ FRS_P2_09_Obj_YPos : 12|13@0+ (0.015625,-64) [-64|63.984375] "m" Vector__XXX
 SG_ FRS_P2_09_Obj_XVelRel : 7|11@0+ (0.1,-102.4) [-102.4|102.3] "m/s" Vector__XXX
 SG_ FRS_P2_09_Obj_XPos : 31|14@0+ (0.015625,0) [0|255.984375] "m" Vector__XXX
 SG_ FRS_P2_09_Obj_Type : 33|2@0+ (1,0) [0|3] "n/a" Vector__XXX
 SG_ FRS_P2_09_Obj_MeasFlag : 52|1@0+ (1,0) [0|1] "n/a" Vector__XXX
 SG_ FRS_P2_09_Msg_AliveCounter : 51|4@0+ (1,0) [0|15] "n/a" Vector__XXX
 SG_ FRS_P2_09_Msg_CheckSum : 63|8@0+ (1,0) [0|255] "n/a" Vector__XXX

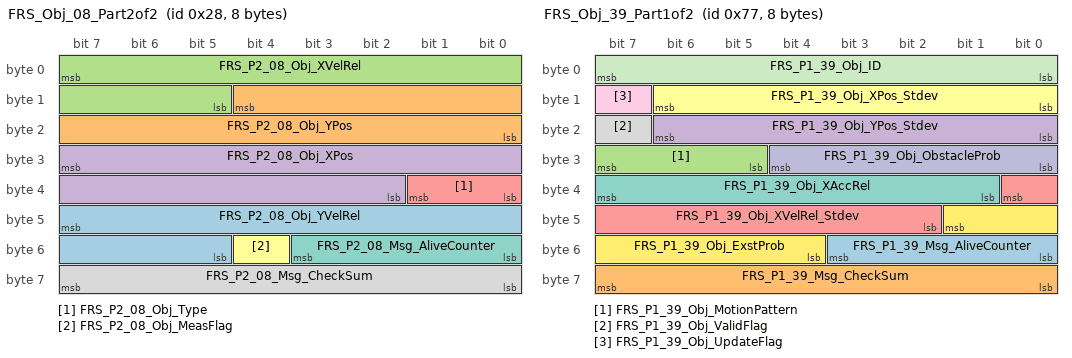
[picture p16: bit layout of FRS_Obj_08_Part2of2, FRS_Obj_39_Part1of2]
BO_ 40 FRS_Obj_08_Part2of2: 8 FRS
 SG_ FRS_P2_08_Obj_YVelRel : 47|11@0+ (0.1,-102.4) [-102.4|102.3] "m/s" Vector__XXX
 SG_ FRS_P2_08_Obj_YPos : 12|13@0+ (0.015625,-64) [-64|63.984375] "m" Vector__XXX
 SG_ FRS_P2_08_Obj_XVelRel : 7|11@0+ (0.1,-102.4) [-102.4|102.3] "m/s" Vector__XXX
 SG_ FRS_P2_08_Obj_XPos : 31|14@0+ (0.015625,0) [0|255.984375] "m" Vector__XXX
 SG_ FRS_P2_08_Obj_Type : 33|2@0+ (1,0) [0|3] "n/a" Vector__XXX
 SG_ FRS_P2_08_Obj_MeasFlag : 52|1@0+ (1,0) [0|1] "n/a" Vector__XXX
 SG_ FRS_P2_08_Msg_AliveCounter : 51|4@0+ (1,0) [0|15] "n/a" Vector__XXX
 SG_ FRS_P2_08_Msg_CheckSum : 63|8@0+ (1,0) [0|255] "n/a" Vector__XXX

BO_ 39 FRS_Obj_07_Part2of2: 8 FRS
 SG_ FRS_P2_07_Obj_YVelRel : 47|11@0+ (0.1,-102.4) [-102.4|102.3] "m/s" Vector__XXX
 SG_ FRS_P2_07_Obj_YPos : 12|13@0+ (0.015625,-64) [-64|63.984375] "m" Vector__XXX
 SG_ FRS_P2_07_Obj_XVelRel : 7|11@0+ (0.1,-102.4) [-102.4|102.3] "m/s" Vector__XXX
 SG_ FRS_P2_07_Obj_XPos : 31|14@0+ (0.015625,0) [0|255.984375] "m" Vector__XXX
 SG_ FRS_P2_07_Obj_Type : 33|2@0+ (1,0) [0|3] "n/a" Vector__XXX
 SG_ FRS_P2_07_Obj_MeasFlag : 52|1@0+ (1,0) [0|1] "n/a" Vector__XXX
 SG_ FRS_P2_07_Msg_AliveCounter : 51|4@0+ (1,0) [0|15] "n/a" Vector__XXX
 SG_ FRS_P2_07_Msg_CheckSum : 63|8@0+ (1,0) [0|255] "n/a" Vector__XXX

BO_ 38 FRS_Obj_06_Part2of2: 8 FRS
 SG_ FRS_P2_06_Obj_YVelRel : 47|11@0+ (0.1,-102.4) [-102.4|102.3] "m/s" Vector__XXX
 SG_ FRS_P2_06_Obj_YPos : 12|13@0+ (0.015625,-64) [-64|63.984375] "m" Vector__XXX
 SG_ FRS_P2_06_Obj_XVelRel : 7|11@0+ (0.1,-102.4) [-102.4|102.3] "m/s" Vector__XXX
 SG_ FRS_P2_06_Obj_XPos : 31|14@0+ (0.015625,0) [0|255.984375] "m" Vector__XXX
 SG_ FRS_P2_06_Obj_Type : 33|2@0+ (1,0) [0|3] "n/a" Vector__XXX
 SG_ FRS_P2_06_Obj_MeasFlag : 52|1@0+ (1,0) [0|1] "n/a" Vector__XXX
 SG_ FRS_P2_06_Msg_AliveCounter : 51|4@0+ (1,0) [0|15] "n/a" Vector__XXX
 SG_ FRS_P2_06_Msg_CheckSum : 63|8@0+ (1,0) [0|255] "n/a" Vector__XXX

BO_ 37 FRS_Obj_05_Part2of2: 8 FRS
 SG_ FRS_P2_05_Obj_YVelRel : 47|11@0+ (0.1,-102.4) [-102.4|102.3] "m/s" Vector__XXX
 SG_ FRS_P2_05_Obj_YPos : 12|13@0+ (0.015625,-64) [-64|63.984375] "m" Vector__XXX
 SG_ FRS_P2_05_Obj_XVelRel : 7|11@0+ (0.1,-102.4) [-102.4|102.3] "m/s" Vector__XXX
 SG_ FRS_P2_05_Obj_XPos : 31|14@0+ (0.015625,0) [0|255.984375] "m" Vector__XXX
 SG_ FRS_P2_05_Obj_Type : 33|2@0+ (1,0) [0|3] "n/a" Vector__XXX
 SG_ FRS_P2_05_Obj_MeasFlag : 52|1@0+ (1,0) [0|1] "n/a" Vector__XXX
 SG_ FRS_P2_05_Msg_AliveCounter : 51|4@0+ (1,0) [0|15] "n/a" Vector__XXX
 SG_ FRS_P2_05_Msg_CheckSum : 63|8@0+ (1,0) [0|255] "n/a" Vector__XXX

BO_ 36 FRS_Obj_04_Part2of2: 8 FRS
 SG_ FRS_P2_04_Obj_YVelRel : 47|11@0+ (0.1,-102.4) [-102.4|102.3] "m/s" Vector__XXX
 SG_ FRS_P2_04_Obj_YPos : 12|13@0+ (0.015625,-64) [-64|63.984375] "m" Vector__XXX
 SG_ FRS_P2_04_Obj_XVelRel : 7|11@0+ (0.1,-102.4) [-102.4|102.3] "m/s" Vector__XXX
 SG_ FRS_P2_04_Obj_XPos : 31|14@0+ (0.015625,0) [0|255.984375] "m" Vector__XXX
 SG_ FRS_P2_04_Obj_Type : 33|2@0+ (1,0) [0|3] "n/a" Vector__XXX
 SG_ FRS_P2_04_Obj_MeasFlag : 52|1@0+ (1,0) [0|1] "n/a" Vector__XXX
 SG_ FRS_P2_04_Msg_AliveCounter : 51|4@0+ (1,0) [0|15] "n/a" Vector__XXX
 SG_ FRS_P2_04_Msg_CheckSum : 63|8@0+ (1,0) [0|255] "n/a" Vector__XXX

BO_ 35 FRS_Obj_03_Part2of2: 8 FRS
 SG_ FRS_P2_03_Obj_YVelRel : 47|11@0+ (0.1,-102.4) [-102.4|102.3] "m/s" Vector__XXX
 SG_ FRS_P2_03_Obj_YPos : 12|13@0+ (0.015625,-64) [-64|63.984375] "m" Vector__XXX
 SG_ FRS_P2_03_Obj_XVelRel : 7|11@0+ (0.1,-102.4) [-102.4|102.3] "m/s" Vector__XXX
 SG_ FRS_P2_03_Obj_XPos : 31|14@0+ (0.015625,0) [0|255.984375] "m" Vector__XXX
 SG_ FRS_P2_03_Obj_Type : 33|2@0+ (1,0) [0|3] "n/a" Vector__XXX
 SG_ FRS_P2_03_Obj_MeasFlag : 52|1@0+ (1,0) [0|1] "n/a" Vector__XXX
 SG_ FRS_P2_03_Msg_AliveCounter : 51|4@0+ (1,0) [0|15] "n/a" Vector__XXX
 SG_ FRS_P2_03_Msg_CheckSum : 63|8@0+ (1,0) [0|255] "n/a" Vector__XXX

BO_ 34 FRS_Obj_02_Part2of2: 8 FRS
 SG_ FRS_P2_02_Obj_YVelRel : 47|11@0+ (0.1,-102.4) [-102.4|102.3] "m/s" Vector__XXX
 SG_ FRS_P2_02_Obj_YPos : 12|13@0+ (0.015625,-64) [-64|63.984375] "m" Vector__XXX
 SG_ FRS_P2_02_Obj_XVelRel : 7|11@0+ (0.1,-102.4) [-102.4|102.3] "m/s" Vector__XXX
 SG_ FRS_P2_02_Obj_XPos : 31|14@0+ (0.015625,0) [0|255.984375] "m" Vector__XXX
 SG_ FRS_P2_02_Obj_Type : 33|2@0+ (1,0) [0|3] "n/a" Vector__XXX
 SG_ FRS_P2_02_Obj_MeasFlag : 52|1@0+ (1,0) [0|1] "n/a" Vector__XXX
 SG_ FRS_P2_02_Msg_AliveCounter : 51|4@0+ (1,0) [0|15] "n/a" Vector__XXX
 SG_ FRS_P2_02_Msg_CheckSum : 63|8@0+ (1,0) [0|255] "n/a" Vector__XXX

BO_ 33 FRS_Obj_01_Part2of2: 8 FRS
 SG_ FRS_P2_01_Obj_YVelRel : 47|11@0+ (0.1,-102.4) [-102.4|102.3] "m/s" Vector__XXX
 SG_ FRS_P2_01_Obj_YPos : 12|13@0+ (0.015625,-64) [-64|63.984375] "m" Vector__XXX
 SG_ FRS_P2_01_Obj_XVelRel : 7|11@0+ (0.1,-102.4) [-102.4|102.3] "m/s" Vector__XXX
 SG_ FRS_P2_01_Obj_XPos : 31|14@0+ (0.015625,0) [0|255.984375] "m" Vector__XXX
 SG_ FRS_P2_01_Obj_Type : 33|2@0+ (1,0) [0|3] "n/a" Vector__XXX
 SG_ FRS_P2_01_Obj_MeasFlag : 52|1@0+ (1,0) [0|1] "n/a" Vector__XXX
 SG_ FRS_P2_01_Msg_AliveCounter : 51|4@0+ (1,0) [0|15] "n/a" Vector__XXX
 SG_ FRS_P2_01_Msg_CheckSum : 63|8@0+ (1,0) [0|255] "n/a" Vector__XXX

BO_ 119 FRS_Obj_39_Part1of2: 8 FRS
 SG_ FRS_P1_39_Msg_AliveCounter : 51|4@0+ (1,0) [0|15] "n/a" Vector__XXX
 SG_ FRS_P1_39_Msg_CheckSum : 63|8@0+ (1,0) [0|255] "n/a" Vector__XXX
 SG_ FRS_P1_39_Obj_MotionPattern : 31|3@0+ (1,0) [0|7] "n/a" Vector__XXX
 SG_ FRS_P1_39_Obj_YPos_Stdev : 22|7@0+ (0.1,0) [0|12.7] "m" Vector__XXX
 SG_ FRS_P1_39_Obj_XVelRel_Stdev : 32|7@0+ (0.05,0) [0|6.35] "m/s" Vector__XXX
 SG_ FRS_P1_39_Obj_XPos_Stdev : 14|7@0+ (0.1,0) [0|12.7] "m" Vector__XXX
 SG_ FRS_P1_39_Obj_XAccRel : 39|7@0+ (0.15,-9.6) [-9.6|9.45] "m/s2" Vector__XXX
 SG_ FRS_P1_39_Obj_ValidFlag : 23|1@0+ (1,0) [0|1] "n/a" Vector__XXX
 SG_ FRS_P1_39_Obj_UpdateFlag : 15|1@0+ (1,0) [0|1] "n/a" Vector__XXX
 SG_ FRS_P1_39_Obj_ObstacleProb : 28|5@0+ (3.2258,0) [0|99.9998] "%" Vector__XXX
 SG_ FRS_P1_39_Obj_ID : 7|8@0+ (1,0) [0|255] "n/a" Vector__XXX
 SG_ FRS_P1_39_Obj_ExstProb : 41|6@0+ (1.5873,0) [0|99.9999] "%" Vector__XXX

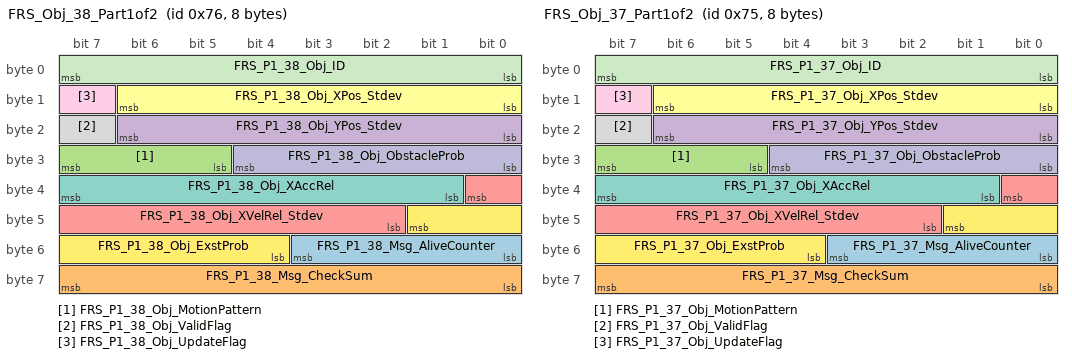
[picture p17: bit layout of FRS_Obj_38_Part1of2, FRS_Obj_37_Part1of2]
BO_ 118 FRS_Obj_38_Part1of2: 8 FRS
 SG_ FRS_P1_38_Msg_AliveCounter : 51|4@0+ (1,0) [0|15] "n/a" Vector__XXX
 SG_ FRS_P1_38_Msg_CheckSum : 63|8@0+ (1,0) [0|255] "n/a" Vector__XXX
 SG_ FRS_P1_38_Obj_MotionPattern : 31|3@0+ (1,0) [0|7] "n/a" Vector__XXX
 SG_ FRS_P1_38_Obj_YPos_Stdev : 22|7@0+ (0.1,0) [0|12.7] "m" Vector__XXX
 SG_ FRS_P1_38_Obj_XVelRel_Stdev : 32|7@0+ (0.05,0) [0|6.35] "m/s" Vector__XXX
 SG_ FRS_P1_38_Obj_XPos_Stdev : 14|7@0+ (0.1,0) [0|12.7] "m" Vector__XXX
 SG_ FRS_P1_38_Obj_XAccRel : 39|7@0+ (0.15,-9.6) [-9.6|9.45] "m/s2" Vector__XXX
 SG_ FRS_P1_38_Obj_ValidFlag : 23|1@0+ (1,0) [0|1] "n/a" Vector__XXX
 SG_ FRS_P1_38_Obj_UpdateFlag : 15|1@0+ (1,0) [0|1] "n/a" Vector__XXX
 SG_ FRS_P1_38_Obj_ObstacleProb : 28|5@0+ (3.2258,0) [0|99.9998] "%" Vector__XXX
 SG_ FRS_P1_38_Obj_ID : 7|8@0+ (1,0) [0|255] "n/a" Vector__XXX
 SG_ FRS_P1_38_Obj_ExstProb : 41|6@0+ (1.5873,0) [0|99.9999] "%" Vector__XXX

BO_ 117 FRS_Obj_37_Part1of2: 8 FRS
 SG_ FRS_P1_37_Msg_AliveCounter : 51|4@0+ (1,0) [0|15] "n/a" Vector__XXX
 SG_ FRS_P1_37_Msg_CheckSum : 63|8@0+ (1,0) [0|255] "n/a" Vector__XXX
 SG_ FRS_P1_37_Obj_MotionPattern : 31|3@0+ (1,0) [0|7] "n/a" Vector__XXX
 SG_ FRS_P1_37_Obj_YPos_Stdev : 22|7@0+ (0.1,0) [0|12.7] "m" Vector__XXX
 SG_ FRS_P1_37_Obj_XVelRel_Stdev : 32|7@0+ (0.05,0) [0|6.35] "m/s" Vector__XXX
 SG_ FRS_P1_37_Obj_XPos_Stdev : 14|7@0+ (0.1,0) [0|12.7] "m" Vector__XXX
 SG_ FRS_P1_37_Obj_XAccRel : 39|7@0+ (0.15,-9.6) [-9.6|9.45] "m/s2" Vector__XXX
 SG_ FRS_P1_37_Obj_ValidFlag : 23|1@0+ (1,0) [0|1] "n/a" Vector__XXX
 SG_ FRS_P1_37_Obj_UpdateFlag : 15|1@0+ (1,0) [0|1] "n/a" Vector__XXX
 SG_ FRS_P1_37_Obj_ObstacleProb : 28|5@0+ (3.2258,0) [0|99.9998] "%" Vector__XXX
 SG_ FRS_P1_37_Obj_ID : 7|8@0+ (1,0) [0|255] "n/a" Vector__XXX
 SG_ FRS_P1_37_Obj_ExstProb : 41|6@0+ (1.5873,0) [0|99.9999] "%" Vector__XXX

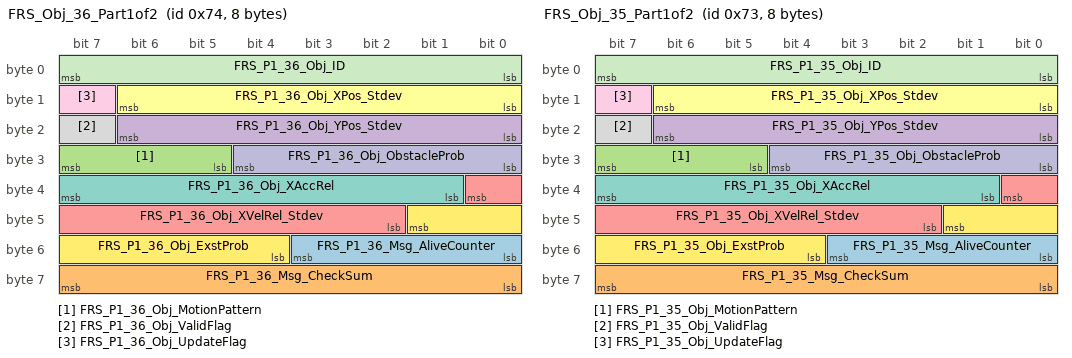
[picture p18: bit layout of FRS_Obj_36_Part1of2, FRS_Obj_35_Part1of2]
BO_ 116 FRS_Obj_36_Part1of2: 8 FRS
 SG_ FRS_P1_36_Msg_AliveCounter : 51|4@0+ (1,0) [0|15] "n/a" Vector__XXX
 SG_ FRS_P1_36_Msg_CheckSum : 63|8@0+ (1,0) [0|255] "n/a" Vector__XXX
 SG_ FRS_P1_36_Obj_MotionPattern : 31|3@0+ (1,0) [0|7] "n/a" Vector__XXX
 SG_ FRS_P1_36_Obj_YPos_Stdev : 22|7@0+ (0.1,0) [0|12.7] "m" Vector__XXX
 SG_ FRS_P1_36_Obj_XVelRel_Stdev : 32|7@0+ (0.05,0) [0|6.35] "m/s" Vector__XXX
 SG_ FRS_P1_36_Obj_XPos_Stdev : 14|7@0+ (0.1,0) [0|12.7] "m" Vector__XXX
 SG_ FRS_P1_36_Obj_XAccRel : 39|7@0+ (0.15,-9.6) [-9.6|9.45] "m/s2" Vector__XXX
 SG_ FRS_P1_36_Obj_ValidFlag : 23|1@0+ (1,0) [0|1] "n/a" Vector__XXX
 SG_ FRS_P1_36_Obj_UpdateFlag : 15|1@0+ (1,0) [0|1] "n/a" Vector__XXX
 SG_ FRS_P1_36_Obj_ObstacleProb : 28|5@0+ (3.2258,0) [0|99.9998] "%" Vector__XXX
 SG_ FRS_P1_36_Obj_ID : 7|8@0+ (1,0) [0|255] "n/a" Vector__XXX
 SG_ FRS_P1_36_Obj_ExstProb : 41|6@0+ (1.5873,0) [0|99.9999] "%" Vector__XXX

BO_ 115 FRS_Obj_35_Part1of2: 8 FRS
 SG_ FRS_P1_35_Msg_AliveCounter : 51|4@0+ (1,0) [0|15] "n/a" Vector__XXX
 SG_ FRS_P1_35_Msg_CheckSum : 63|8@0+ (1,0) [0|255] "n/a" Vector__XXX
 SG_ FRS_P1_35_Obj_MotionPattern : 31|3@0+ (1,0) [0|7] "n/a" Vector__XXX
 SG_ FRS_P1_35_Obj_YPos_Stdev : 22|7@0+ (0.1,0) [0|12.7] "m" Vector__XXX
 SG_ FRS_P1_35_Obj_XVelRel_Stdev : 32|7@0+ (0.05,0) [0|6.35] "m/s" Vector__XXX
 SG_ FRS_P1_35_Obj_XPos_Stdev : 14|7@0+ (0.1,0) [0|12.7] "m" Vector__XXX
 SG_ FRS_P1_35_Obj_XAccRel : 39|7@0+ (0.15,-9.6) [-9.6|9.45] "m/s2" Vector__XXX
 SG_ FRS_P1_35_Obj_ValidFlag : 23|1@0+ (1,0) [0|1] "n/a" Vector__XXX
 SG_ FRS_P1_35_Obj_UpdateFlag : 15|1@0+ (1,0) [0|1] "n/a" Vector__XXX
 SG_ FRS_P1_35_Obj_ObstacleProb : 28|5@0+ (3.2258,0) [0|99.9998] "%" Vector__XXX
 SG_ FRS_P1_35_Obj_ID : 7|8@0+ (1,0) [0|255] "n/a" Vector__XXX
 SG_ FRS_P1_35_Obj_ExstProb : 41|6@0+ (1.5873,0) [0|99.9999] "%" Vector__XXX

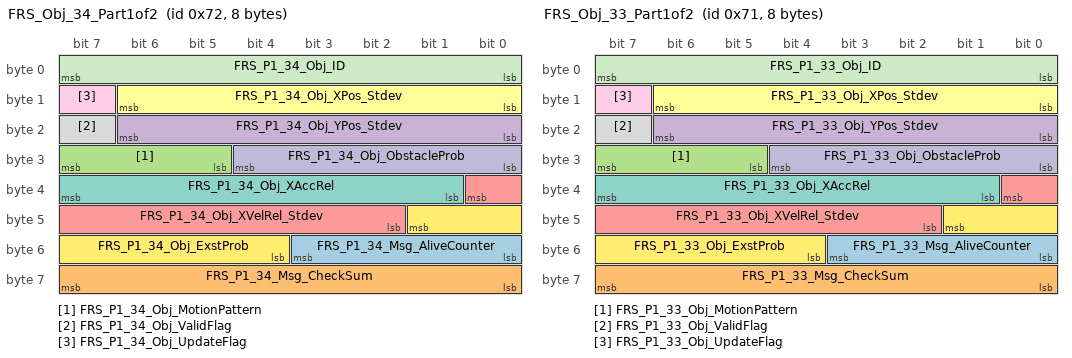
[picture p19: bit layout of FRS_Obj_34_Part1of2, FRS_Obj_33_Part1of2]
BO_ 114 FRS_Obj_34_Part1of2: 8 FRS
 SG_ FRS_P1_34_Msg_AliveCounter : 51|4@0+ (1,0) [0|15] "n/a" Vector__XXX
 SG_ FRS_P1_34_Msg_CheckSum : 63|8@0+ (1,0) [0|255] "n/a" Vector__XXX
 SG_ FRS_P1_34_Obj_MotionPattern : 31|3@0+ (1,0) [0|7] "n/a" Vector__XXX
 SG_ FRS_P1_34_Obj_YPos_Stdev : 22|7@0+ (0.1,0) [0|12.7] "m" Vector__XXX
 SG_ FRS_P1_34_Obj_XVelRel_Stdev : 32|7@0+ (0.05,0) [0|6.35] "m/s" Vector__XXX
 SG_ FRS_P1_34_Obj_XPos_Stdev : 14|7@0+ (0.1,0) [0|12.7] "m" Vector__XXX
 SG_ FRS_P1_34_Obj_XAccRel : 39|7@0+ (0.15,-9.6) [-9.6|9.45] "m/s2" Vector__XXX
 SG_ FRS_P1_34_Obj_ValidFlag : 23|1@0+ (1,0) [0|1] "n/a" Vector__XXX
 SG_ FRS_P1_34_Obj_UpdateFlag : 15|1@0+ (1,0) [0|1] "n/a" Vector__XXX
 SG_ FRS_P1_34_Obj_ObstacleProb : 28|5@0+ (3.2258,0) [0|99.9998] "%" Vector__XXX
 SG_ FRS_P1_34_Obj_ID : 7|8@0+ (1,0) [0|255] "n/a" Vector__XXX
 SG_ FRS_P1_34_Obj_ExstProb : 41|6@0+ (1.5873,0) [0|99.9999] "%" Vector__XXX

BO_ 113 FRS_Obj_33_Part1of2: 8 FRS
 SG_ FRS_P1_33_Msg_AliveCounter : 51|4@0+ (1,0) [0|15] "n/a" Vector__XXX
 SG_ FRS_P1_33_Msg_CheckSum : 63|8@0+ (1,0) [0|255] "n/a" Vector__XXX
 SG_ FRS_P1_33_Obj_MotionPattern : 31|3@0+ (1,0) [0|7] "n/a" Vector__XXX
 SG_ FRS_P1_33_Obj_YPos_Stdev : 22|7@0+ (0.1,0) [0|12.7] "m" Vector__XXX
 SG_ FRS_P1_33_Obj_XVelRel_Stdev : 32|7@0+ (0.05,0) [0|6.35] "m/s" Vector__XXX
 SG_ FRS_P1_33_Obj_XPos_Stdev : 14|7@0+ (0.1,0) [0|12.7] "m" Vector__XXX
 SG_ FRS_P1_33_Obj_XAccRel : 39|7@0+ (0.15,-9.6) [-9.6|9.45] "m/s2" Vector__XXX
 SG_ FRS_P1_33_Obj_ValidFlag : 23|1@0+ (1,0) [0|1] "n/a" Vector__XXX
 SG_ FRS_P1_33_Obj_UpdateFlag : 15|1@0+ (1,0) [0|1] "n/a" Vector__XXX
 SG_ FRS_P1_33_Obj_ObstacleProb : 28|5@0+ (3.2258,0) [0|99.9998] "%" Vector__XXX
 SG_ FRS_P1_33_Obj_ID : 7|8@0+ (1,0) [0|255] "n/a" Vector__XXX
 SG_ FRS_P1_33_Obj_ExstProb : 41|6@0+ (1.5873,0) [0|99.9999] "%" Vector__XXX

CM_ BO_ 3221225472 "This is a message for not used signals, created by Vector CANdb++ DBC OLE DB Provider.";
CM_ SG_ 3221225472 mntAzmInFlash "The Horizontal Installation Angle in Flash";
CM_ SG_ 3221225472 mntAzmRealTime "The Horizontal Installation Angle for Real-time Compensation";
CM_ SG_ 3221225472 RadarSubVehicle_Yawrate "Yawrate";
CM_ SG_ 3221225472 RadarSubVehicle_TurnSwitch "Turn signal status";
CM_ SG_ 3221225472 RadarSubVehicle_Gear "Gear
0:N
1:D
2:R
3:P";
CM_ SG_ 3221225472 RadarSubVehicle_StrWheelAngle "Steering wheel angle
";
CM_ SG_ 3221225472 RadarSubVehicle_Speed "Speed";
CM_ SG_ 91 FRS_P1_11_Msg_AliveCounter "Alive counter shall be incremented every radar sensor measurement cycle.";
CM_ SG_ 91 FRS_P1_11_Msg_CheckSum "Check sum shall be generated out of each message content. check sum generation logic is TBC.";
CM_ SG_ 91 FRS_P1_11_Obj_MotionPattern "Motion type of object.
0x00: Unknown
0x01: Stationary
0x02: Stopped
0x03: Moving
0x04: Crossing
0x05-07: reserved";
CM_ SG_ 91 FRS_P1_11_Obj_YPos_Stdev "Estimated 3-sigma standard deviation value of lateral position of the object.";
CM_ SG_ 91 FRS_P1_11_Obj_XVelRel_Stdev "Estimated 3-sigma standard deviation value of the relative longitudinal velocity of the object.";
CM_ SG_ 91 FRS_P1_11_Obj_XPos_Stdev "Estimated 3-sigma standard deviation value of longitudinal position of the object.";
CM_ SG_ 91 FRS_P1_11_Obj_XAccRel "Relative longitudinal acceleration of the object";
CM_ SG_ 91 FRS_P1_11_Obj_ValidFlag "Validity indication flag. when this value shows invalid, all the signals in the corresponding CAN messages except FRS_Msg_AliveCounter and FRS_Msg_CheckSum shall take default values.
0x0: Object invalid
0x1: Object valid";
CM_ SG_ 91 FRS_P1_11_Obj_UpdateFlag "Flag to indicate newly created object in CAN bus.
Object history flag
0x0: new object in the cycle;
0x1: object existed in previous cycle";
CM_ SG_ 91 FRS_P1_11_Obj_ObstacleProb "Estimated probability of the object being an obstacle.";
CM_ SG_ 91 FRS_P1_11_Obj_ID "ID is defined as a unique identification number over the lifetime of the object.
0xFF: Invalid
0x00 - 0xFE: Valid";
CM_ SG_ 91 FRS_P1_11_Obj_ExstProb "Estimated existence probability of the object.";
CM_ SG_ 71 FRS_P2_39_Obj_YVelRel "Relative lateral velocity of the object";
CM_ SG_ 71 FRS_P2_39_Obj_YPos "Position of target object in lateral direction
center of vehicle rear axle shaft is reference point.";
CM_ SG_ 71 FRS_P2_39_Obj_XVelRel "Relative longitudinal velocity of the object.";
CM_ SG_ 71 FRS_P2_39_Obj_XPos "Position of target object in longitudinal direction
center of vehicle rear axle shaft is reference point.";
CM_ SG_ 71 FRS_P2_39_Obj_Type "To indicate the estimated type of Object
0x00: Unknown
0x01: 4 wheeler
0x02: 2 wheeler
0x03: Pedestrian";
CM_ SG_ 71 FRS_P2_39_Obj_MeasFlag "This signal indicates whether the latest sensor measurement observed the object or extrapolated.
0x0: object measured in this cycle
0x1: object extrapolated in this cycle";
CM_ SG_ 71 FRS_P2_39_Msg_AliveCounter "Alive counter shall be incremented every radar sensor measurement cycle.";
CM_ SG_ 71 FRS_P2_39_Msg_CheckSum "Check sum shall be generated out of each message content. check sum generation logic is TBC.";
CM_ SG_ 70 FRS_P2_38_Obj_YVelRel "Relative lateral velocity of the object";
CM_ SG_ 70 FRS_P2_38_Obj_YPos "Position of target object in lateral direction
center of vehicle rear axle shaft is reference point.";
CM_ SG_ 70 FRS_P2_38_Obj_XVelRel "Relative longitudinal velocity of the object.";
CM_ SG_ 70 FRS_P2_38_Obj_XPos "Position of target object in longitudinal direction
center of vehicle rear axle shaft is reference point.";
CM_ SG_ 70 FRS_P2_38_Obj_Type "To indicate the estimated type of Object
0x00: Unknown
0x01: 4 wheeler
0x02: 2 wheeler
0x03: Pedestrian";
CM_ SG_ 70 FRS_P2_38_Obj_MeasFlag "This signal indicates whether the latest sensor measurement observed the object or extrapolated.
0x0: object measured in this cycle
0x1: object extrapolated in this cycle";
CM_ SG_ 70 FRS_P2_38_Msg_AliveCounter "Alive counter shall be incremented every radar sensor measurement cycle.";
CM_ SG_ 70 FRS_P2_38_Msg_CheckSum "Check sum shall be generated out of each message content. check sum generation logic is TBC.";
CM_ SG_ 69 FRS_P2_37_Obj_YVelRel "Relative lateral velocity of the object";
CM_ SG_ 69 FRS_P2_37_Obj_YPos "Position of target object in lateral direction
center of vehicle rear axle shaft is reference point.";
CM_ SG_ 69 FRS_P2_37_Obj_XVelRel "Relative longitudinal velocity of the object.";
CM_ SG_ 69 FRS_P2_37_Obj_XPos "Position of target object in longitudinal direction
center of vehicle rear axle shaft is reference point.";
CM_ SG_ 69 FRS_P2_37_Obj_Type "To indicate the estimated type of Object
0x00: Unknown
0x01: 4 wheeler
0x02: 2 wheeler
0x03: Pedestrian";
CM_ SG_ 69 FRS_P2_37_Obj_MeasFlag "This signal indicates whether the latest sensor measurement observed the object or extrapolated.
0x0: object measured in this cycle
0x1: object extrapolated in this cycle";
CM_ SG_ 69 FRS_P2_37_Msg_AliveCounter "Alive counter shall be incremented every radar sensor measurement cycle.";
CM_ SG_ 69 FRS_P2_37_Msg_CheckSum "Check sum shall be generated out of each message content. check sum generation logic is TBC.";
CM_ SG_ 68 FRS_P2_36_Obj_YVelRel "Relative lateral velocity of the object";
CM_ SG_ 68 FRS_P2_36_Obj_YPos "Position of target object in lateral direction
center of vehicle rear axle shaft is reference point.";
CM_ SG_ 68 FRS_P2_36_Obj_XVelRel "Relative longitudinal velocity of the object.";
CM_ SG_ 68 FRS_P2_36_Obj_XPos "Position of target object in longitudinal direction
center of vehicle rear axle shaft is reference point.";
CM_ SG_ 68 FRS_P2_36_Obj_Type "To indicate the estimated type of Object
0x00: Unknown
0x01: 4 wheeler
0x02: 2 wheeler
0x03: Pedestrian";
CM_ SG_ 68 FRS_P2_36_Obj_MeasFlag "This signal indicates whether the latest sensor measurement observed the object or extrapolated.
0x0: object measured in this cycle
0x1: object extrapolated in this cycle";
CM_ SG_ 68 FRS_P2_36_Msg_AliveCounter "Alive counter shall be incremented every radar sensor measurement cycle.";
CM_ SG_ 68 FRS_P2_36_Msg_CheckSum "Check sum shall be generated out of each message content. check sum generation logic is TBC.";
CM_ SG_ 67 FRS_P2_35_Obj_YVelRel "Relative lateral velocity of the object";
CM_ SG_ 67 FRS_P2_35_Obj_YPos "Position of target object in lateral direction
center of vehicle rear axle shaft is reference point.";
CM_ SG_ 67 FRS_P2_35_Obj_XVelRel "Relative longitudinal velocity of the object.";
CM_ SG_ 67 FRS_P2_35_Obj_XPos "Position of target object in longitudinal direction
center of vehicle rear axle shaft is reference point.";
CM_ SG_ 67 FRS_P2_35_Obj_Type "To indicate the estimated type of Object
0x00: Unknown
0x01: 4 wheeler
0x02: 2 wheeler
0x03: Pedestrian";
CM_ SG_ 67 FRS_P2_35_Obj_MeasFlag "This signal indicates whether the latest sensor measurement observed the object or extrapolated.
0x0: object measured in this cycle
0x1: object extrapolated in this cycle";
CM_ SG_ 67 FRS_P2_35_Msg_AliveCounter "Alive counter shall be incremented every radar sensor measurement cycle.";
CM_ SG_ 67 FRS_P2_35_Msg_CheckSum "Check sum shall be generated out of each message content. check sum generation logic is TBC.";
CM_ SG_ 66 FRS_P2_34_Obj_YVelRel "Relative lateral velocity of the object";
CM_ SG_ 66 FRS_P2_34_Obj_YPos "Position of target object in lateral direction
center of vehicle rear axle shaft is reference point.";
CM_ SG_ 66 FRS_P2_34_Obj_XVelRel "Relative longitudinal velocity of the object.";
CM_ SG_ 66 FRS_P2_34_Obj_XPos "Position of target object in longitudinal direction
center of vehicle rear axle shaft is reference point.";
CM_ SG_ 66 FRS_P2_34_Obj_Type "To indicate the estimated type of Object
0x00: Unknown
0x01: 4 wheeler
0x02: 2 wheeler
0x03: Pedestrian";
CM_ SG_ 66 FRS_P2_34_Obj_MeasFlag "This signal indicates whether the latest sensor measurement observed the object or extrapolated.
0x0: object measured in this cycle
0x1: object extrapolated in this cycle";
CM_ SG_ 66 FRS_P2_34_Msg_AliveCounter "Alive counter shall be incremented every radar sensor measurement cycle.";
CM_ SG_ 66 FRS_P2_34_Msg_CheckSum "Check sum shall be generated out of each message content. check sum generation logic is TBC.";
CM_ SG_ 65 FRS_P2_33_Obj_YVelRel "Relative lateral velocity of the object";
CM_ SG_ 65 FRS_P2_33_Obj_YPos "Position of target object in lateral direction
center of vehicle rear axle shaft is reference point.";
CM_ SG_ 65 FRS_P2_33_Obj_XVelRel "Relative longitudinal velocity of the object.";
CM_ SG_ 65 FRS_P2_33_Obj_XPos "Position of target object in longitudinal direction
center of vehicle rear axle shaft is reference point.";
CM_ SG_ 65 FRS_P2_33_Obj_Type "To indicate the estimated type of Object
0x00: Unknown
0x01: 4 wheeler
0x02: 2 wheeler
0x03: Pedestrian";
CM_ SG_ 65 FRS_P2_33_Obj_MeasFlag "This signal indicates whether the latest sensor measurement observed the object or extrapolated.
0x0: object measured in this cycle
0x1: object extrapolated in this cycle";
CM_ SG_ 65 FRS_P2_33_Msg_AliveCounter "Alive counter shall be incremented every radar sensor measurement cycle.";
CM_ SG_ 65 FRS_P2_33_Msg_CheckSum "Check sum shall be generated out of each message content. check sum generation logic is TBC.";
CM_ SG_ 64 FRS_P2_32_Obj_YVelRel "Relative lateral velocity of the object";
CM_ SG_ 64 FRS_P2_32_Obj_YPos "Position of target object in lateral direction
center of vehicle rear axle shaft is reference point.";
CM_ SG_ 64 FRS_P2_32_Obj_XVelRel "Relative longitudinal velocity of the object.";
CM_ SG_ 64 FRS_P2_32_Obj_XPos "Position of target object in longitudinal direction
center of vehicle rear axle shaft is reference point.";
CM_ SG_ 64 FRS_P2_32_Obj_Type "To indicate the estimated type of Object
0x00: Unknown
0x01: 4 wheeler
0x02: 2 wheeler
0x03: Pedestrian";
CM_ SG_ 64 FRS_P2_32_Obj_MeasFlag "This signal indicates whether the latest sensor measurement observed the object or extrapolated.
0x0: object measured in this cycle
0x1: object extrapolated in this cycle";
CM_ SG_ 64 FRS_P2_32_Msg_AliveCounter "Alive counter shall be incremented every radar sensor measurement cycle.";
CM_ SG_ 64 FRS_P2_32_Msg_CheckSum "Check sum shall be generated out of each message content. check sum generation logic is TBC.";
CM_ SG_ 63 FRS_P2_31_Obj_YVelRel "Relative lateral velocity of the object";
CM_ SG_ 63 FRS_P2_31_Obj_YPos "Position of target object in lateral direction
center of vehicle rear axle shaft is reference point.";
CM_ SG_ 63 FRS_P2_31_Obj_XVelRel "Relative longitudinal velocity of the object.";
CM_ SG_ 63 FRS_P2_31_Obj_XPos "Position of target object in longitudinal direction
center of vehicle rear axle shaft is reference point.";
CM_ SG_ 63 FRS_P2_31_Obj_Type "To indicate the estimated type of Object
0x00: Unknown
0x01: 4 wheeler
0x02: 2 wheeler
0x03: Pedestrian";
CM_ SG_ 63 FRS_P2_31_Obj_MeasFlag "This signal indicates whether the latest sensor measurement observed the object or extrapolated.
0x0: object measured in this cycle
0x1: object extrapolated in this cycle";
CM_ SG_ 63 FRS_P2_31_Msg_AliveCounter "Alive counter shall be incremented every radar sensor measurement cycle.";
CM_ SG_ 63 FRS_P2_31_Msg_CheckSum "Check sum shall be generated out of each message content. check sum generation logic is TBC.";
CM_ SG_ 62 FRS_P2_30_Obj_YVelRel "Relative lateral velocity of the object";
CM_ SG_ 62 FRS_P2_30_Obj_YPos "Position of target object in lateral direction
center of vehicle rear axle shaft is reference point.";
CM_ SG_ 62 FRS_P2_30_Obj_XVelRel "Relative longitudinal velocity of the object.";
CM_ SG_ 62 FRS_P2_30_Obj_XPos "Position of target object in longitudinal direction
center of vehicle rear axle shaft is reference point.";
CM_ SG_ 62 FRS_P2_30_Obj_Type "To indicate the estimated type of Object
0x00: Unknown
0x01: 4 wheeler
0x02: 2 wheeler
0x03: Pedestrian";
CM_ SG_ 62 FRS_P2_30_Obj_MeasFlag "This signal indicates whether the latest sensor measurement observed the object or extrapolated.
0x0: object measured in this cycle
0x1: object extrapolated in this cycle";
CM_ SG_ 62 FRS_P2_30_Msg_AliveCounter "Alive counter shall be incremented every radar sensor measurement cycle.";
CM_ SG_ 62 FRS_P2_30_Msg_CheckSum "Check sum shall be generated out of each message content. check sum generation logic is TBC.";
CM_ SG_ 61 FRS_P2_29_Obj_YVelRel "Relative lateral velocity of the object";
CM_ SG_ 61 FRS_P2_29_Obj_YPos "Position of target object in lateral direction
center of vehicle rear axle shaft is reference point.";
CM_ SG_ 61 FRS_P2_29_Obj_XVelRel "Relative longitudinal velocity of the object.";
CM_ SG_ 61 FRS_P2_29_Obj_XPos "Position of target object in longitudinal direction
center of vehicle rear axle shaft is reference point.";
CM_ SG_ 61 FRS_P2_29_Obj_Type "To indicate the estimated type of Object
0x00: Unknown
0x01: 4 wheeler
0x02: 2 wheeler
0x03: Pedestrian";
CM_ SG_ 61 FRS_P2_29_Obj_MeasFlag "This signal indicates whether the latest sensor measurement observed the object or extrapolated.
0x0: object measured in this cycle
0x1: object extrapolated in this cycle";
CM_ SG_ 61 FRS_P2_29_Msg_AliveCounter "Alive counter shall be incremented every radar sensor measurement cycle.";
CM_ SG_ 61 FRS_P2_29_Msg_CheckSum "Check sum shall be generated out of each message content. check sum generation logic is TBC.";
CM_ SG_ 60 FRS_P2_28_Obj_YVelRel "Relative lateral velocity of the object";
CM_ SG_ 60 FRS_P2_28_Obj_YPos "Position of target object in lateral direction
center of vehicle rear axle shaft is reference point.";
CM_ SG_ 60 FRS_P2_28_Obj_XVelRel "Relative longitudinal velocity of the object.";
CM_ SG_ 60 FRS_P2_28_Obj_XPos "Position of target object in longitudinal direction
center of vehicle rear axle shaft is reference point.";
CM_ SG_ 60 FRS_P2_28_Obj_Type "To indicate the estimated type of Object
0x00: Unknown
0x01: 4 wheeler
0x02: 2 wheeler
0x03: Pedestrian";
CM_ SG_ 60 FRS_P2_28_Obj_MeasFlag "This signal indicates whether the latest sensor measurement observed the object or extrapolated.
0x0: object measured in this cycle
0x1: object extrapolated in this cycle";
CM_ SG_ 60 FRS_P2_28_Msg_AliveCounter "Alive counter shall be incremented every radar sensor measurement cycle.";
CM_ SG_ 60 FRS_P2_28_Msg_CheckSum "Check sum shall be generated out of each message content. check sum generation logic is TBC.";
CM_ SG_ 59 FRS_P2_27_Obj_YVelRel "Relative lateral velocity of the object";
CM_ SG_ 59 FRS_P2_27_Obj_YPos "Position of target object in lateral direction
center of vehicle rear axle shaft is reference point.";
CM_ SG_ 59 FRS_P2_27_Obj_XVelRel "Relative longitudinal velocity of the object.";
CM_ SG_ 59 FRS_P2_27_Obj_XPos "Position of target object in longitudinal direction
center of vehicle rear axle shaft is reference point.";
CM_ SG_ 59 FRS_P2_27_Obj_Type "To indicate the estimated type of Object
0x00: Unknown
0x01: 4 wheeler
0x02: 2 wheeler
0x03: Pedestrian";
CM_ SG_ 59 FRS_P2_27_Obj_MeasFlag "This signal indicates whether the latest sensor measurement observed the object or extrapolated.
0x0: object measured in this cycle
0x1: object extrapolated in this cycle";
CM_ SG_ 59 FRS_P2_27_Msg_AliveCounter "Alive counter shall be incremented every radar sensor measurement cycle.";
CM_ SG_ 59 FRS_P2_27_Msg_CheckSum "Check sum shall be generated out of each message content. check sum generation logic is TBC.";
CM_ SG_ 58 FRS_P2_26_Obj_YVelRel "Relative lateral velocity of the object";
CM_ SG_ 58 FRS_P2_26_Obj_YPos "Position of target object in lateral direction
center of vehicle rear axle shaft is reference point.";
CM_ SG_ 58 FRS_P2_26_Obj_XVelRel "Relative longitudinal velocity of the object.";
CM_ SG_ 58 FRS_P2_26_Obj_XPos "Position of target object in longitudinal direction
center of vehicle rear axle shaft is reference point.";
CM_ SG_ 58 FRS_P2_26_Obj_Type "To indicate the estimated type of Object
0x00: Unknown
0x01: 4 wheeler
0x02: 2 wheeler
0x03: Pedestrian";
CM_ SG_ 58 FRS_P2_26_Obj_MeasFlag "This signal indicates whether the latest sensor measurement observed the object or extrapolated.
0x0: object measured in this cycle
0x1: object extrapolated in this cycle";
CM_ SG_ 58 FRS_P2_26_Msg_AliveCounter "Alive counter shall be incremented every radar sensor measurement cycle.";
CM_ SG_ 58 FRS_P2_26_Msg_CheckSum "Check sum shall be generated out of each message content. check sum generation logic is TBC.";
CM_ SG_ 57 FRS_P2_25_Obj_YVelRel "Relative lateral velocity of the object";
CM_ SG_ 57 FRS_P2_25_Obj_YPos "Position of target object in lateral direction
center of vehicle rear axle shaft is reference point.";
CM_ SG_ 57 FRS_P2_25_Obj_XVelRel "Relative longitudinal velocity of the object.";
CM_ SG_ 57 FRS_P2_25_Obj_XPos "Position of target object in longitudinal direction
center of vehicle rear axle shaft is reference point.";
CM_ SG_ 57 FRS_P2_25_Obj_Type "To indicate the estimated type of Object
0x00: Unknown
0x01: 4 wheeler
0x02: 2 wheeler
0x03: Pedestrian";
CM_ SG_ 57 FRS_P2_25_Obj_MeasFlag "This signal indicates whether the latest sensor measurement observed the object or extrapolated.
0x0: object measured in this cycle
0x1: object extrapolated in this cycle";
CM_ SG_ 57 FRS_P2_25_Msg_AliveCounter "Alive counter shall be incremented every radar sensor measurement cycle.";
CM_ SG_ 57 FRS_P2_25_Msg_CheckSum "Check sum shall be generated out of each message content. check sum generation logic is TBC.";
CM_ SG_ 56 FRS_P2_24_Obj_YVelRel "Relative lateral velocity of the object";
CM_ SG_ 56 FRS_P2_24_Obj_YPos "Position of target object in lateral direction
center of vehicle rear axle shaft is reference point.";
CM_ SG_ 56 FRS_P2_24_Obj_XVelRel "Relative longitudinal velocity of the object.";
CM_ SG_ 56 FRS_P2_24_Obj_XPos "Position of target object in longitudinal direction
center of vehicle rear axle shaft is reference point.";
CM_ SG_ 56 FRS_P2_24_Obj_Type "To indicate the estimated type of Object
0x00: Unknown
0x01: 4 wheeler
0x02: 2 wheeler
0x03: Pedestrian";
CM_ SG_ 56 FRS_P2_24_Obj_MeasFlag "This signal indicates whether the latest sensor measurement observed the object or extrapolated.
0x0: object measured in this cycle
0x1: object extrapolated in this cycle";
CM_ SG_ 56 FRS_P2_24_Msg_AliveCounter "Alive counter shall be incremented every radar sensor measurement cycle.";
CM_ SG_ 56 FRS_P2_24_Msg_CheckSum "Check sum shall be generated out of each message content. check sum generation logic is TBC.";
CM_ SG_ 55 FRS_P2_23_Obj_YVelRel "Relative lateral velocity of the object";
CM_ SG_ 55 FRS_P2_23_Obj_YPos "Position of target object in lateral direction
center of vehicle rear axle shaft is reference point.";
CM_ SG_ 55 FRS_P2_23_Obj_XVelRel "Relative longitudinal velocity of the object.";
CM_ SG_ 55 FRS_P2_23_Obj_XPos "Position of target object in longitudinal direction
center of vehicle rear axle shaft is reference point.";
CM_ SG_ 55 FRS_P2_23_Obj_Type "To indicate the estimated type of Object
0x00: Unknown
0x01: 4 wheeler
0x02: 2 wheeler
0x03: Pedestrian";
CM_ SG_ 55 FRS_P2_23_Obj_MeasFlag "This signal indicates whether the latest sensor measurement observed the object or extrapolated.
0x0: object measured in this cycle
0x1: object extrapolated in this cycle";
CM_ SG_ 55 FRS_P2_23_Msg_AliveCounter "Alive counter shall be incremented every radar sensor measurement cycle.";
CM_ SG_ 55 FRS_P2_23_Msg_CheckSum "Check sum shall be generated out of each message content. check sum generation logic is TBC.";
CM_ SG_ 54 FRS_P2_22_Obj_YVelRel "Relative lateral velocity of the object";
CM_ SG_ 54 FRS_P2_22_Obj_YPos "Position of target object in lateral direction
center of vehicle rear axle shaft is reference point.";
CM_ SG_ 54 FRS_P2_22_Obj_XVelRel "Relative longitudinal velocity of the object.";
CM_ SG_ 54 FRS_P2_22_Obj_XPos "Position of target object in longitudinal direction
center of vehicle rear axle shaft is reference point.";
CM_ SG_ 54 FRS_P2_22_Obj_Type "To indicate the estimated type of Object
0x00: Unknown
0x01: 4 wheeler
0x02: 2 wheeler
0x03: Pedestrian";
CM_ SG_ 54 FRS_P2_22_Obj_MeasFlag "This signal indicates whether the latest sensor measurement observed the object or extrapolated.
0x0: object measured in this cycle
0x1: object extrapolated in this cycle";
CM_ SG_ 54 FRS_P2_22_Msg_AliveCounter "Alive counter shall be incremented every radar sensor measurement cycle.";
CM_ SG_ 54 FRS_P2_22_Msg_CheckSum "Check sum shall be generated out of each message content. check sum generation logic is TBC.";
CM_ SG_ 53 FRS_P2_21_Obj_YVelRel "Relative lateral velocity of the object";
CM_ SG_ 53 FRS_P2_21_Obj_YPos "Position of target object in lateral direction
center of vehicle rear axle shaft is reference point.";
CM_ SG_ 53 FRS_P2_21_Obj_XVelRel "Relative longitudinal velocity of the object.";
CM_ SG_ 53 FRS_P2_21_Obj_XPos "Position of target object in longitudinal direction
center of vehicle rear axle shaft is reference point.";
CM_ SG_ 53 FRS_P2_21_Obj_Type "To indicate the estimated type of Object
0x00: Unknown
0x01: 4 wheeler
0x02: 2 wheeler
0x03: Pedestrian";
CM_ SG_ 53 FRS_P2_21_Obj_MeasFlag "This signal indicates whether the latest sensor measurement observed the object or extrapolated.
0x0: object measured in this cycle
0x1: object extrapolated in this cycle";
CM_ SG_ 53 FRS_P2_21_Msg_AliveCounter "Alive counter shall be incremented every radar sensor measurement cycle.";
CM_ SG_ 53 FRS_P2_21_Msg_CheckSum "Check sum shall be generated out of each message content. check sum generation logic is TBC.";
CM_ SG_ 52 FRS_P2_20_Obj_YVelRel "Relative lateral velocity of the object";
CM_ SG_ 52 FRS_P2_20_Obj_YPos "Position of target object in lateral direction
center of vehicle rear axle shaft is reference point.";
CM_ SG_ 52 FRS_P2_20_Obj_XVelRel "Relative longitudinal velocity of the object.";
CM_ SG_ 52 FRS_P2_20_Obj_XPos "Position of target object in longitudinal direction
center of vehicle rear axle shaft is reference point.";
CM_ SG_ 52 FRS_P2_20_Obj_Type "To indicate the estimated type of Object
0x00: Unknown
0x01: 4 wheeler
0x02: 2 wheeler
0x03: Pedestrian";
CM_ SG_ 52 FRS_P2_20_Obj_MeasFlag "This signal indicates whether the latest sensor measurement observed the object or extrapolated.
0x0: object measured in this cycle
0x1: object extrapolated in this cycle";
CM_ SG_ 52 FRS_P2_20_Msg_AliveCounter "Alive counter shall be incremented every radar sensor measurement cycle.";
CM_ SG_ 52 FRS_P2_20_Msg_CheckSum "Check sum shall be generated out of each message content. check sum generation logic is TBC.";
CM_ SG_ 51 FRS_P2_19_Obj_YVelRel "Relative lateral velocity of the object";
CM_ SG_ 51 FRS_P2_19_Obj_YPos "Position of target object in lateral direction
center of vehicle rear axle shaft is reference point.";
CM_ SG_ 51 FRS_P2_19_Obj_XVelRel "Relative longitudinal velocity of the object.";
CM_ SG_ 51 FRS_P2_19_Obj_XPos "Position of target object in longitudinal direction
center of vehicle rear axle shaft is reference point.";
CM_ SG_ 51 FRS_P2_19_Obj_Type "To indicate the estimated type of Object
0x00: Unknown
0x01: 4 wheeler
0x02: 2 wheeler
0x03: Pedestrian";
CM_ SG_ 51 FRS_P2_19_Obj_MeasFlag "This signal indicates whether the latest sensor measurement observed the object or extrapolated.
0x0: object measured in this cycle
0x1: object extrapolated in this cycle";
CM_ SG_ 51 FRS_P2_19_Msg_AliveCounter "Alive counter shall be incremented every radar sensor measurement cycle.";
CM_ SG_ 51 FRS_P2_19_Msg_CheckSum "Check sum shall be generated out of each message content. check sum generation logic is TBC.";
CM_ SG_ 50 FRS_P2_18_Obj_YVelRel "Relative lateral velocity of the object";
CM_ SG_ 50 FRS_P2_18_Obj_YPos "Position of target object in lateral direction
center of vehicle rear axle shaft is reference point.";
CM_ SG_ 50 FRS_P2_18_Obj_XVelRel "Relative longitudinal velocity of the object.";
CM_ SG_ 50 FRS_P2_18_Obj_XPos "Position of target object in longitudinal direction
center of vehicle rear axle shaft is reference point.";
CM_ SG_ 50 FRS_P2_18_Obj_Type "To indicate the estimated type of Object
0x00: Unknown
0x01: 4 wheeler
0x02: 2 wheeler
0x03: Pedestrian";
CM_ SG_ 50 FRS_P2_18_Obj_MeasFlag "This signal indicates whether the latest sensor measurement observed the object or extrapolated.
0x0: object measured in this cycle
0x1: object extrapolated in this cycle";
CM_ SG_ 50 FRS_P2_18_Msg_AliveCounter "Alive counter shall be incremented every radar sensor measurement cycle.";
CM_ SG_ 50 FRS_P2_18_Msg_CheckSum "Check sum shall be generated out of each message content. check sum generation logic is TBC.";
CM_ SG_ 49 FRS_P2_17_Obj_YVelRel "Relative lateral velocity of the object";
CM_ SG_ 49 FRS_P2_17_Obj_YPos "Position of target object in lateral direction
center of vehicle rear axle shaft is reference point.";
CM_ SG_ 49 FRS_P2_17_Obj_XVelRel "Relative longitudinal velocity of the object.";
CM_ SG_ 49 FRS_P2_17_Obj_XPos "Position of target object in longitudinal direction
center of vehicle rear axle shaft is reference point.";
CM_ SG_ 49 FRS_P2_17_Obj_Type "To indicate the estimated type of Object
0x00: Unknown
0x01: 4 wheeler
0x02: 2 wheeler
0x03: Pedestrian";
CM_ SG_ 49 FRS_P2_17_Obj_MeasFlag "This signal indicates whether the latest sensor measurement observed the object or extrapolated.
0x0: object measured in this cycle
0x1: object extrapolated in this cycle";
CM_ SG_ 49 FRS_P2_17_Msg_AliveCounter "Alive counter shall be incremented every radar sensor measurement cycle.";
CM_ SG_ 49 FRS_P2_17_Msg_CheckSum "Check sum shall be generated out of each message content. check sum generation logic is TBC.";
CM_ SG_ 48 FRS_P2_16_Obj_YVelRel "Relative lateral velocity of the object";
CM_ SG_ 48 FRS_P2_16_Obj_YPos "Position of target object in lateral direction
center of vehicle rear axle shaft is reference point.";
CM_ SG_ 48 FRS_P2_16_Obj_XVelRel "Relative longitudinal velocity of the object.";
CM_ SG_ 48 FRS_P2_16_Obj_XPos "Position of target object in longitudinal direction
center of vehicle rear axle shaft is reference point.";
CM_ SG_ 48 FRS_P2_16_Obj_Type "To indicate the estimated type of Object
0x00: Unknown
0x01: 4 wheeler
0x02: 2 wheeler
0x03: Pedestrian";
CM_ SG_ 48 FRS_P2_16_Obj_MeasFlag "This signal indicates whether the latest sensor measurement observed the object or extrapolated.
0x0: object measured in this cycle
0x1: object extrapolated in this cycle";
CM_ SG_ 48 FRS_P2_16_Msg_AliveCounter "Alive counter shall be incremented every radar sensor measurement cycle.";
CM_ SG_ 48 FRS_P2_16_Msg_CheckSum "Check sum shall be generated out of each message content. check sum generation logic is TBC.";
CM_ SG_ 47 FRS_P2_15_Obj_YVelRel "Relative lateral velocity of the object";
CM_ SG_ 47 FRS_P2_15_Obj_YPos "Position of target object in lateral direction
center of vehicle rear axle shaft is reference point.";
CM_ SG_ 47 FRS_P2_15_Obj_XVelRel "Relative longitudinal velocity of the object.";
CM_ SG_ 47 FRS_P2_15_Obj_XPos "Position of target object in longitudinal direction
center of vehicle rear axle shaft is reference point.";
CM_ SG_ 47 FRS_P2_15_Obj_Type "To indicate the estimated type of Object
0x00: Unknown
0x01: 4 wheeler
0x02: 2 wheeler
0x03: Pedestrian";
CM_ SG_ 47 FRS_P2_15_Obj_MeasFlag "This signal indicates whether the latest sensor measurement observed the object or extrapolated.
0x0: object measured in this cycle
0x1: object extrapolated in this cycle";
CM_ SG_ 47 FRS_P2_15_Msg_AliveCounter "Alive counter shall be incremented every radar sensor measurement cycle.";
CM_ SG_ 47 FRS_P2_15_Msg_CheckSum "Check sum shall be generated out of each message content. check sum generation logic is TBC.";
CM_ SG_ 46 FRS_P2_14_Obj_YVelRel "Relative lateral velocity of the object";
CM_ SG_ 46 FRS_P2_14_Obj_YPos "Position of target object in lateral direction
center of vehicle rear axle shaft is reference point.";
CM_ SG_ 46 FRS_P2_14_Obj_XVelRel "Relative longitudinal velocity of the object.";
CM_ SG_ 46 FRS_P2_14_Obj_XPos "Position of target object in longitudinal direction
center of vehicle rear axle shaft is reference point.";
CM_ SG_ 46 FRS_P2_14_Obj_Type "To indicate the estimated type of Object
0x00: Unknown
0x01: 4 wheeler
0x02: 2 wheeler
0x03: Pedestrian";
CM_ SG_ 46 FRS_P2_14_Obj_MeasFlag "This signal indicates whether the latest sensor measurement observed the object or extrapolated.
0x0: object measured in this cycle
0x1: object extrapolated in this cycle";
CM_ SG_ 46 FRS_P2_14_Msg_AliveCounter "Alive counter shall be incremented every radar sensor measurement cycle.";
CM_ SG_ 46 FRS_P2_14_Msg_CheckSum "Check sum shall be generated out of each message content. check sum generation logic is TBC.";
CM_ SG_ 45 FRS_P2_13_Obj_YVelRel "Relative lateral velocity of the object";
CM_ SG_ 45 FRS_P2_13_Obj_YPos "Position of target object in lateral direction
center of vehicle rear axle shaft is reference point.";
CM_ SG_ 45 FRS_P2_13_Obj_XVelRel "Relative longitudinal velocity of the object.";
CM_ SG_ 45 FRS_P2_13_Obj_XPos "Position of target object in longitudinal direction
center of vehicle rear axle shaft is reference point.";
CM_ SG_ 45 FRS_P2_13_Obj_Type "To indicate the estimated type of Object
0x00: Unknown
0x01: 4 wheeler
0x02: 2 wheeler
0x03: Pedestrian";
CM_ SG_ 45 FRS_P2_13_Obj_MeasFlag "This signal indicates whether the latest sensor measurement observed the object or extrapolated.
0x0: object measured in this cycle
0x1: object extrapolated in this cycle";
CM_ SG_ 45 FRS_P2_13_Msg_AliveCounter "Alive counter shall be incremented every radar sensor measurement cycle.";
CM_ SG_ 45 FRS_P2_13_Msg_CheckSum "Check sum shall be generated out of each message content. check sum generation logic is TBC.";
CM_ SG_ 44 FRS_P2_12_Obj_YVelRel "Relative lateral velocity of the object";
CM_ SG_ 44 FRS_P2_12_Obj_YPos "Position of target object in lateral direction
center of vehicle rear axle shaft is reference point.";
CM_ SG_ 44 FRS_P2_12_Obj_XVelRel "Relative longitudinal velocity of the object.";
CM_ SG_ 44 FRS_P2_12_Obj_XPos "Position of target object in longitudinal direction
center of vehicle rear axle shaft is reference point.";
CM_ SG_ 44 FRS_P2_12_Obj_Type "To indicate the estimated type of Object
0x00: Unknown
0x01: 4 wheeler
0x02: 2 wheeler
0x03: Pedestrian";
CM_ SG_ 44 FRS_P2_12_Obj_MeasFlag "This signal indicates whether the latest sensor measurement observed the object or extrapolated.
0x0: object measured in this cycle
0x1: object extrapolated in this cycle";
CM_ SG_ 44 FRS_P2_12_Msg_AliveCounter "Alive counter shall be incremented every radar sensor measurement cycle.";
CM_ SG_ 44 FRS_P2_12_Msg_CheckSum "Check sum shall be generated out of each message content. check sum generation logic is TBC.";
CM_ SG_ 43 FRS_P2_11_Obj_YVelRel "Relative lateral velocity of the object";
CM_ SG_ 43 FRS_P2_11_Obj_YPos "Position of target object in lateral direction
center of vehicle rear axle shaft is reference point.";
CM_ SG_ 43 FRS_P2_11_Obj_XVelRel "Relative longitudinal velocity of the object.";
CM_ SG_ 43 FRS_P2_11_Obj_XPos "Position of target object in longitudinal direction
center of vehicle rear axle shaft is reference point.";
CM_ SG_ 43 FRS_P2_11_Obj_Type "To indicate the estimated type of Object
0x00: Unknown
0x01: 4 wheeler
0x02: 2 wheeler
0x03: Pedestrian";
CM_ SG_ 43 FRS_P2_11_Obj_MeasFlag "This signal indicates whether the latest sensor measurement observed the object or extrapolated.
0x0: object measured in this cycle
0x1: object extrapolated in this cycle";
CM_ SG_ 43 FRS_P2_11_Msg_AliveCounter "Alive counter shall be incremented every radar sensor measurement cycle.";
CM_ SG_ 43 FRS_P2_11_Msg_CheckSum "Check sum shall be generated out of each message content. check sum generation logic is TBC.";
CM_ SG_ 42 FRS_P2_10_Obj_YVelRel "Relative lateral velocity of the object";
CM_ SG_ 42 FRS_P2_10_Obj_YPos "Position of target object in lateral direction
center of vehicle rear axle shaft is reference point.";
CM_ SG_ 42 FRS_P2_10_Obj_XVelRel "Relative longitudinal velocity of the object.";
CM_ SG_ 42 FRS_P2_10_Obj_XPos "Position of target object in longitudinal direction
center of vehicle rear axle shaft is reference point.";
CM_ SG_ 42 FRS_P2_10_Obj_Type "To indicate the estimated type of Object
0x00: Unknown
0x01: 4 wheeler
0x02: 2 wheeler
0x03: Pedestrian";
CM_ SG_ 42 FRS_P2_10_Obj_MeasFlag "This signal indicates whether the latest sensor measurement observed the object or extrapolated.
0x0: object measured in this cycle
0x1: object extrapolated in this cycle";
CM_ SG_ 42 FRS_P2_10_Msg_AliveCounter "Alive counter shall be incremented every radar sensor measurement cycle.";
CM_ SG_ 42 FRS_P2_10_Msg_CheckSum "Check sum shall be generated out of each message content. check sum generation logic is TBC.";
CM_ SG_ 41 FRS_P2_09_Obj_YVelRel "Relative lateral velocity of the object";
CM_ SG_ 41 FRS_P2_09_Obj_YPos "Position of target object in lateral direction
center of vehicle rear axle shaft is reference point.";
CM_ SG_ 41 FRS_P2_09_Obj_XVelRel "Relative longitudinal velocity of the object.";
CM_ SG_ 41 FRS_P2_09_Obj_XPos "Position of target object in longitudinal direction
center of vehicle rear axle shaft is reference point.";
CM_ SG_ 41 FRS_P2_09_Obj_Type "To indicate the estimated type of Object
0x00: Unknown
0x01: 4 wheeler
0x02: 2 wheeler
0x03: Pedestrian";
CM_ SG_ 41 FRS_P2_09_Obj_MeasFlag "This signal indicates whether the latest sensor measurement observed the object or extrapolated.
0x0: object measured in this cycle
0x1: object extrapolated in this cycle";
CM_ SG_ 41 FRS_P2_09_Msg_AliveCounter "Alive counter shall be incremented every radar sensor measurement cycle.";
CM_ SG_ 41 FRS_P2_09_Msg_CheckSum "Check sum shall be generated out of each message content. check sum generation logic is TBC.";
CM_ SG_ 40 FRS_P2_08_Obj_YVelRel "Relative lateral velocity of the object";
CM_ SG_ 40 FRS_P2_08_Obj_YPos "Position of target object in lateral direction
center of vehicle rear axle shaft is reference point.";
CM_ SG_ 40 FRS_P2_08_Obj_XVelRel "Relative longitudinal velocity of the object.";
CM_ SG_ 40 FRS_P2_08_Obj_XPos "Position of target object in longitudinal direction
center of vehicle rear axle shaft is reference point.";
CM_ SG_ 40 FRS_P2_08_Obj_Type "To indicate the estimated type of Object
0x00: Unknown
0x01: 4 wheeler
0x02: 2 wheeler
0x03: Pedestrian";
CM_ SG_ 40 FRS_P2_08_Obj_MeasFlag "This signal indicates whether the latest sensor measurement observed the object or extrapolated.
0x0: object measured in this cycle
0x1: object extrapolated in this cycle";
CM_ SG_ 40 FRS_P2_08_Msg_AliveCounter "Alive counter shall be incremented every radar sensor measurement cycle.";
CM_ SG_ 40 FRS_P2_08_Msg_CheckSum "Check sum shall be generated out of each message content. check sum generation logic is TBC.";
CM_ SG_ 39 FRS_P2_07_Obj_YVelRel "Relative lateral velocity of the object";
CM_ SG_ 39 FRS_P2_07_Obj_YPos "Position of target object in lateral direction
center of vehicle rear axle shaft is reference point.";
CM_ SG_ 39 FRS_P2_07_Obj_XVelRel "Relative longitudinal velocity of the object.";
CM_ SG_ 39 FRS_P2_07_Obj_XPos "Position of target object in longitudinal direction
center of vehicle rear axle shaft is reference point.";
CM_ SG_ 39 FRS_P2_07_Obj_Type "To indicate the estimated type of Object
0x00: Unknown
0x01: 4 wheeler
0x02: 2 wheeler
0x03: Pedestrian";
CM_ SG_ 39 FRS_P2_07_Obj_MeasFlag "This signal indicates whether the latest sensor measurement observed the object or extrapolated.
0x0: object measured in this cycle
0x1: object extrapolated in this cycle";
CM_ SG_ 39 FRS_P2_07_Msg_AliveCounter "Alive counter shall be incremented every radar sensor measurement cycle.";
CM_ SG_ 39 FRS_P2_07_Msg_CheckSum "Check sum shall be generated out of each message content. check sum generation logic is TBC.";
CM_ SG_ 38 FRS_P2_06_Obj_YVelRel "Relative lateral velocity of the object";
CM_ SG_ 38 FRS_P2_06_Obj_YPos "Position of target object in lateral direction
center of vehicle rear axle shaft is reference point.";
CM_ SG_ 38 FRS_P2_06_Obj_XVelRel "Relative longitudinal velocity of the object.";
CM_ SG_ 38 FRS_P2_06_Obj_XPos "Position of target object in longitudinal direction
center of vehicle rear axle shaft is reference point.";
CM_ SG_ 38 FRS_P2_06_Obj_Type "To indicate the estimated type of Object
0x00: Unknown
0x01: 4 wheeler
0x02: 2 wheeler
0x03: Pedestrian";
CM_ SG_ 38 FRS_P2_06_Obj_MeasFlag "This signal indicates whether the latest sensor measurement observed the object or extrapolated.
0x0: object measured in this cycle
0x1: object extrapolated in this cycle";
CM_ SG_ 38 FRS_P2_06_Msg_AliveCounter "Alive counter shall be incremented every radar sensor measurement cycle.";
CM_ SG_ 38 FRS_P2_06_Msg_CheckSum "Check sum shall be generated out of each message content. check sum generation logic is TBC.";
CM_ SG_ 37 FRS_P2_05_Obj_YVelRel "Relative lateral velocity of the object";
CM_ SG_ 37 FRS_P2_05_Obj_YPos "Position of target object in lateral direction
center of vehicle rear axle shaft is reference point.";
CM_ SG_ 37 FRS_P2_05_Obj_XVelRel "Relative longitudinal velocity of the object.";
CM_ SG_ 37 FRS_P2_05_Obj_XPos "Position of target object in longitudinal direction
center of vehicle rear axle shaft is reference point.";
CM_ SG_ 37 FRS_P2_05_Obj_Type "To indicate the estimated type of Object
0x00: Unknown
0x01: 4 wheeler
0x02: 2 wheeler
0x03: Pedestrian";
CM_ SG_ 37 FRS_P2_05_Obj_MeasFlag "This signal indicates whether the latest sensor measurement observed the object or extrapolated.
0x0: object measured in this cycle
0x1: object extrapolated in this cycle";
CM_ SG_ 37 FRS_P2_05_Msg_AliveCounter "Alive counter shall be incremented every radar sensor measurement cycle.";
CM_ SG_ 37 FRS_P2_05_Msg_CheckSum "Check sum shall be generated out of each message content. check sum generation logic is TBC.";
CM_ SG_ 36 FRS_P2_04_Obj_YVelRel "Relative lateral velocity of the object";
CM_ SG_ 36 FRS_P2_04_Obj_YPos "Position of target object in lateral direction
center of vehicle rear axle shaft is reference point.";
CM_ SG_ 36 FRS_P2_04_Obj_XVelRel "Relative longitudinal velocity of the object.";
CM_ SG_ 36 FRS_P2_04_Obj_XPos "Position of target object in longitudinal direction
center of vehicle rear axle shaft is reference point.";
CM_ SG_ 36 FRS_P2_04_Obj_Type "To indicate the estimated type of Object
0x00: Unknown
0x01: 4 wheeler
0x02: 2 wheeler
0x03: Pedestrian";
CM_ SG_ 36 FRS_P2_04_Obj_MeasFlag "This signal indicates whether the latest sensor measurement observed the object or extrapolated.
0x0: object measured in this cycle
0x1: object extrapolated in this cycle";
CM_ SG_ 36 FRS_P2_04_Msg_AliveCounter "Alive counter shall be incremented every radar sensor measurement cycle.";
CM_ SG_ 36 FRS_P2_04_Msg_CheckSum "Check sum shall be generated out of each message content. check sum generation logic is TBC.";
CM_ SG_ 35 FRS_P2_03_Obj_YVelRel "Relative lateral velocity of the object";
CM_ SG_ 35 FRS_P2_03_Obj_YPos "Position of target object in lateral direction
center of vehicle rear axle shaft is reference point.";
CM_ SG_ 35 FRS_P2_03_Obj_XVelRel "Relative longitudinal velocity of the object.";
CM_ SG_ 35 FRS_P2_03_Obj_XPos "Position of target object in longitudinal direction
center of vehicle rear axle shaft is reference point.";
CM_ SG_ 35 FRS_P2_03_Obj_Type "To indicate the estimated type of Object
0x00: Unknown
0x01: 4 wheeler
0x02: 2 wheeler
0x03: Pedestrian";
CM_ SG_ 35 FRS_P2_03_Obj_MeasFlag "This signal indicates whether the latest sensor measurement observed the object or extrapolated.
0x0: object measured in this cycle
0x1: object extrapolated in this cycle";
CM_ SG_ 35 FRS_P2_03_Msg_AliveCounter "Alive counter shall be incremented every radar sensor measurement cycle.";
CM_ SG_ 35 FRS_P2_03_Msg_CheckSum "Check sum shall be generated out of each message content. check sum generation logic is TBC.";
CM_ SG_ 34 FRS_P2_02_Obj_YVelRel "Relative lateral velocity of the object";
CM_ SG_ 34 FRS_P2_02_Obj_YPos "Position of target object in lateral direction
center of vehicle rear axle shaft is reference point.";
CM_ SG_ 34 FRS_P2_02_Obj_XVelRel "Relative longitudinal velocity of the object.";
CM_ SG_ 34 FRS_P2_02_Obj_XPos "Position of target object in longitudinal direction
center of vehicle rear axle shaft is reference point.";
CM_ SG_ 34 FRS_P2_02_Obj_Type "To indicate the estimated type of Object
0x00: Unknown
0x01: 4 wheeler
0x02: 2 wheeler
0x03: Pedestrian";
CM_ SG_ 34 FRS_P2_02_Obj_MeasFlag "This signal indicates whether the latest sensor measurement observed the object or extrapolated.
0x0: object measured in this cycle
0x1: object extrapolated in this cycle";
CM_ SG_ 34 FRS_P2_02_Msg_AliveCounter "Alive counter shall be incremented every radar sensor measurement cycle.";
CM_ SG_ 34 FRS_P2_02_Msg_CheckSum "Check sum shall be generated out of each message content. check sum generation logic is TBC.";
CM_ SG_ 33 FRS_P2_01_Obj_YVelRel "Relative lateral velocity of the object";
CM_ SG_ 33 FRS_P2_01_Obj_YPos "Position of target object in lateral direction
center of vehicle rear axle shaft is reference point.";
CM_ SG_ 33 FRS_P2_01_Obj_XVelRel "Relative longitudinal velocity of the object.";
CM_ SG_ 33 FRS_P2_01_Obj_XPos "Position of target object in longitudinal direction
center of vehicle rear axle shaft is reference point.";
CM_ SG_ 33 FRS_P2_01_Obj_Type "To indicate the estimated type of Object
0x00: Unknown
0x01: 4 wheeler
0x02: 2 wheeler
0x03: Pedestrian";
CM_ SG_ 33 FRS_P2_01_Obj_MeasFlag "This signal indicates whether the latest sensor measurement observed the object or extrapolated.
0x0: object measured in this cycle
0x1: object extrapolated in this cycle";
CM_ SG_ 33 FRS_P2_01_Msg_AliveCounter "Alive counter shall be incremented every radar sensor measurement cycle.";
CM_ SG_ 33 FRS_P2_01_Msg_CheckSum "Check sum shall be generated out of each message content. check sum generation logic is TBC.";
CM_ SG_ 119 FRS_P1_39_Msg_AliveCounter "Alive counter shall be incremented every radar sensor measurement cycle.";
CM_ SG_ 119 FRS_P1_39_Msg_CheckSum "Check sum shall be generated out of each message content. check sum generation logic is TBC.";
CM_ SG_ 119 FRS_P1_39_Obj_MotionPattern "Motion type of object.
0x00: Unknown
0x01: Stationary
0x02: Stopped
0x03: Moving
0x04: Crossing
0x05-07: reserved";
CM_ SG_ 119 FRS_P1_39_Obj_YPos_Stdev "Estimated 3-sigma standard deviation value of lateral position of the object.";
CM_ SG_ 119 FRS_P1_39_Obj_XVelRel_Stdev "Estimated 3-sigma standard deviation value of the relative longitudinal velocity of the object.";
CM_ SG_ 119 FRS_P1_39_Obj_XPos_Stdev "Estimated 3-sigma standard deviation value of longitudinal position of the object.";
CM_ SG_ 119 FRS_P1_39_Obj_XAccRel "Relative longitudinal acceleration of the object";
CM_ SG_ 119 FRS_P1_39_Obj_ValidFlag "Validity indication flag. when this value shows invalid, all the signals in the corresponding CAN messages except FRS_Msg_AliveCounter and FRS_Msg_CheckSum shall take default values.
0x0: Object invalid
0x1: Object valid";
CM_ SG_ 119 FRS_P1_39_Obj_UpdateFlag "Flag to indicate newly created object in CAN bus.
Object history flag
0x0: new object in the cycle;
0x1: object existed in previous cycle";
CM_ SG_ 119 FRS_P1_39_Obj_ObstacleProb "Estimated probability of the object being an obstacle.";
CM_ SG_ 119 FRS_P1_39_Obj_ID "ID is defined as a unique identification number over the lifetime of the object.
0xFF: Invalid
0x00 - 0xFE: Valid";
CM_ SG_ 119 FRS_P1_39_Obj_ExstProb "Estimated existence probability of the object.";
CM_ SG_ 118 FRS_P1_38_Msg_AliveCounter "Alive counter shall be incremented every radar sensor measurement cycle.";
CM_ SG_ 118 FRS_P1_38_Msg_CheckSum "Check sum shall be generated out of each message content. check sum generation logic is TBC.";
CM_ SG_ 118 FRS_P1_38_Obj_MotionPattern "Motion type of object.
0x00: Unknown
0x01: Stationary
0x02: Stopped
0x03: Moving
0x04: Crossing
0x05-07: reserved";
CM_ SG_ 118 FRS_P1_38_Obj_YPos_Stdev "Estimated 3-sigma standard deviation value of lateral position of the object.";
CM_ SG_ 118 FRS_P1_38_Obj_XVelRel_Stdev "Estimated 3-sigma standard deviation value of the relative longitudinal velocity of the object.";
CM_ SG_ 118 FRS_P1_38_Obj_XPos_Stdev "Estimated 3-sigma standard deviation value of longitudinal position of the object.";
CM_ SG_ 118 FRS_P1_38_Obj_XAccRel "Relative longitudinal acceleration of the object";
CM_ SG_ 118 FRS_P1_38_Obj_ValidFlag "Validity indication flag. when this value shows invalid, all the signals in the corresponding CAN messages except FRS_Msg_AliveCounter and FRS_Msg_CheckSum shall take default values.
0x0: Object invalid
0x1: Object valid";
CM_ SG_ 118 FRS_P1_38_Obj_UpdateFlag "Flag to indicate newly created object in CAN bus.
Object history flag
0x0: new object in the cycle;
0x1: object existed in previous cycle";
CM_ SG_ 118 FRS_P1_38_Obj_ObstacleProb "Estimated probability of the object being an obstacle.";
CM_ SG_ 118 FRS_P1_38_Obj_ID "ID is defined as a unique identification number over the lifetime of the object.
0xFF: Invalid
0x00 - 0xFE: Valid";
CM_ SG_ 118 FRS_P1_38_Obj_ExstProb "Estimated existence probability of the object.";
CM_ SG_ 117 FRS_P1_37_Msg_AliveCounter "Alive counter shall be incremented every radar sensor measurement cycle.";
CM_ SG_ 117 FRS_P1_37_Msg_CheckSum "Check sum shall be generated out of each message content. check sum generation logic is TBC.";
CM_ SG_ 117 FRS_P1_37_Obj_MotionPattern "Motion type of object.
0x00: Unknown
0x01: Stationary
0x02: Stopped
0x03: Moving
0x04: Crossing
0x05-07: reserved";
CM_ SG_ 117 FRS_P1_37_Obj_YPos_Stdev "Estimated 3-sigma standard deviation value of lateral position of the object.";
CM_ SG_ 117 FRS_P1_37_Obj_XVelRel_Stdev "Estimated 3-sigma standard deviation value of the relative longitudinal velocity of the object.";
CM_ SG_ 117 FRS_P1_37_Obj_XPos_Stdev "Estimated 3-sigma standard deviation value of longitudinal position of the object.";
CM_ SG_ 117 FRS_P1_37_Obj_XAccRel "Relative longitudinal acceleration of the object";
CM_ SG_ 117 FRS_P1_37_Obj_ValidFlag "Validity indication flag. when this value shows invalid, all the signals in the corresponding CAN messages except FRS_Msg_AliveCounter and FRS_Msg_CheckSum shall take default values.
0x0: Object invalid
0x1: Object valid";
CM_ SG_ 117 FRS_P1_37_Obj_UpdateFlag "Flag to indicate newly created object in CAN bus.
Object history flag
0x0: new object in the cycle;
0x1: object existed in previous cycle";
CM_ SG_ 117 FRS_P1_37_Obj_ObstacleProb "Estimated probability of the object being an obstacle.";
CM_ SG_ 117 FRS_P1_37_Obj_ID "ID is defined as a unique identification number over the lifetime of the object.
0xFF: Invalid
0x00 - 0xFE: Valid";
CM_ SG_ 117 FRS_P1_37_Obj_ExstProb "Estimated existence probability of the object.";
CM_ SG_ 116 FRS_P1_36_Msg_AliveCounter "Alive counter shall be incremented every radar sensor measurement cycle.";
CM_ SG_ 116 FRS_P1_36_Msg_CheckSum "Check sum shall be generated out of each message content. check sum generation logic is TBC.";
CM_ SG_ 116 FRS_P1_36_Obj_MotionPattern "Motion type of object.
0x00: Unknown
0x01: Stationary
0x02: Stopped
0x03: Moving
0x04: Crossing
0x05-07: reserved";
CM_ SG_ 116 FRS_P1_36_Obj_YPos_Stdev "Estimated 3-sigma standard deviation value of lateral position of the object.";
CM_ SG_ 116 FRS_P1_36_Obj_XVelRel_Stdev "Estimated 3-sigma standard deviation value of the relative longitudinal velocity of the object.";
CM_ SG_ 116 FRS_P1_36_Obj_XPos_Stdev "Estimated 3-sigma standard deviation value of longitudinal position of the object.";
CM_ SG_ 116 FRS_P1_36_Obj_XAccRel "Relative longitudinal acceleration of the object";
CM_ SG_ 116 FRS_P1_36_Obj_ValidFlag "Validity indication flag. when this value shows invalid, all the signals in the corresponding CAN messages except FRS_Msg_AliveCounter and FRS_Msg_CheckSum shall take default values.
0x0: Object invalid
0x1: Object valid";
CM_ SG_ 116 FRS_P1_36_Obj_UpdateFlag "Flag to indicate newly created object in CAN bus.
Object history flag
0x0: new object in the cycle;
0x1: object existed in previous cycle";
CM_ SG_ 116 FRS_P1_36_Obj_ObstacleProb "Estimated probability of the object being an obstacle.";
CM_ SG_ 116 FRS_P1_36_Obj_ID "ID is defined as a unique identification number over the lifetime of the object.
0xFF: Invalid
0x00 - 0xFE: Valid";
CM_ SG_ 116 FRS_P1_36_Obj_ExstProb "Estimated existence probability of the object.";
CM_ SG_ 115 FRS_P1_35_Msg_AliveCounter "Alive counter shall be incremented every radar sensor measurement cycle.";
CM_ SG_ 115 FRS_P1_35_Msg_CheckSum "Check sum shall be generated out of each message content. check sum generation logic is TBC.";
CM_ SG_ 115 FRS_P1_35_Obj_MotionPattern "Motion type of object.
0x00: Unknown
0x01: Stationary
0x02: Stopped
0x03: Moving
0x04: Crossing
0x05-07: reserved";
CM_ SG_ 115 FRS_P1_35_Obj_YPos_Stdev "Estimated 3-sigma standard deviation value of lateral position of the object.";
CM_ SG_ 115 FRS_P1_35_Obj_XVelRel_Stdev "Estimated 3-sigma standard deviation value of the relative longitudinal velocity of the object.";
CM_ SG_ 115 FRS_P1_35_Obj_XPos_Stdev "Estimated 3-sigma standard deviation value of longitudinal position of the object.";
CM_ SG_ 115 FRS_P1_35_Obj_XAccRel "Relative longitudinal acceleration of the object";
CM_ SG_ 115 FRS_P1_35_Obj_ValidFlag "Validity indication flag. when this value shows invalid, all the signals in the corresponding CAN messages except FRS_Msg_AliveCounter and FRS_Msg_CheckSum shall take default values.
0x0: Object invalid
0x1: Object valid";
CM_ SG_ 115 FRS_P1_35_Obj_UpdateFlag "Flag to indicate newly created object in CAN bus.
Object history flag
0x0: new object in the cycle;
0x1: object existed in previous cycle";
CM_ SG_ 115 FRS_P1_35_Obj_ObstacleProb "Estimated probability of the object being an obstacle.";
CM_ SG_ 115 FRS_P1_35_Obj_ID "ID is defined as a unique identification number over the lifetime of the object.
0xFF: Invalid
0x00 - 0xFE: Valid";
CM_ SG_ 115 FRS_P1_35_Obj_ExstProb "Estimated existence probability of the object.";
CM_ SG_ 114 FRS_P1_34_Msg_AliveCounter "Alive counter shall be incremented every radar sensor measurement cycle.";
CM_ SG_ 114 FRS_P1_34_Msg_CheckSum "Check sum shall be generated out of each message content. check sum generation logic is TBC.";
CM_ SG_ 114 FRS_P1_34_Obj_MotionPattern "Motion type of object.
0x00: Unknown
0x01: Stationary
0x02: Stopped
0x03: Moving
0x04: Crossing
0x05-07: reserved";
CM_ SG_ 114 FRS_P1_34_Obj_YPos_Stdev "Estimated 3-sigma standard deviation value of lateral position of the object.";
CM_ SG_ 114 FRS_P1_34_Obj_XVelRel_Stdev "Estimated 3-sigma standard deviation value of the relative longitudinal velocity of the object.";
CM_ SG_ 114 FRS_P1_34_Obj_XPos_Stdev "Estimated 3-sigma standard deviation value of longitudinal position of the object.";
CM_ SG_ 114 FRS_P1_34_Obj_XAccRel "Relative longitudinal acceleration of the object";
CM_ SG_ 114 FRS_P1_34_Obj_ValidFlag "Validity indication flag. when this value shows invalid, all the signals in the corresponding CAN messages except FRS_Msg_AliveCounter and FRS_Msg_CheckSum shall take default values.
0x0: Object invalid
0x1: Object valid";
CM_ SG_ 114 FRS_P1_34_Obj_UpdateFlag "Flag to indicate newly created object in CAN bus.
Object history flag
0x0: new object in the cycle;
0x1: object existed in previous cycle";
CM_ SG_ 114 FRS_P1_34_Obj_ObstacleProb "Estimated probability of the object being an obstacle.";
CM_ SG_ 114 FRS_P1_34_Obj_ID "ID is defined as a unique identification number over the lifetime of the object.
0xFF: Invalid
0x00 - 0xFE: Valid";
CM_ SG_ 114 FRS_P1_34_Obj_ExstProb "Estimated existence probability of the object.";
CM_ SG_ 113 FRS_P1_33_Msg_AliveCounter "Alive counter shall be incremented every radar sensor measurement cycle.";
CM_ SG_ 113 FRS_P1_33_Msg_CheckSum "Check sum shall be generated out of each message content. check sum generation logic is TBC.";
CM_ SG_ 113 FRS_P1_33_Obj_MotionPattern "Motion type of object.
0x00: Unknown
0x01: Stationary
0x02: Stopped
0x03: Moving
0x04: Crossing
0x05-07: reserved";
CM_ SG_ 113 FRS_P1_33_Obj_YPos_Stdev "Estimated 3-sigma standard deviation value of lateral position of the object.";
CM_ SG_ 113 FRS_P1_33_Obj_XVelRel_Stdev "Estimated 3-sigma standard deviation value of the relative longitudinal velocity of the object.";
CM_ SG_ 113 FRS_P1_33_Obj_XPos_Stdev "Estimated 3-sigma standard deviation value of longitudinal position of the object.";
CM_ SG_ 113 FRS_P1_33_Obj_XAccRel "Relative longitudinal acceleration of the object";
CM_ SG_ 113 FRS_P1_33_Obj_ValidFlag "Validity indication flag. when this value shows invalid, all the signals in the corresponding CAN messages except FRS_Msg_AliveCounter and FRS_Msg_CheckSum shall take default values.
0x0: Object invalid
0x1: Object valid";
CM_ SG_ 113 FRS_P1_33_Obj_UpdateFlag "Flag to indicate newly created object in CAN bus.
Object history flag
0x0: new object in the cycle;
0x1: object existed in previous cycle";
CM_ SG_ 113 FRS_P1_33_Obj_ObstacleProb "Estimated probability of the object being an obstacle.";
CM_ SG_ 113 FRS_P1_33_Obj_ID "ID is defined as a unique identification number over the lifetime of the object.
0xFF: Invalid
0x00 - 0xFE: Valid";
CM_ SG_ 113 FRS_P1_33_Obj_ExstProb "Estimated existence probability of the object.";
BA_DEF_ BO_  "GenMsgCycleTime" INT 0 50000;
BA_DEF_ BO_  "GenMsgILSupport" ENUM  "No","Yes";
BA_DEF_ BO_  "GenMsgSendType" ENUM  "Cyclic","NotUsed","NotUsed","NotUsed","NotUsed","NotUsed","NotUsed","NotUsed","NoMsgSendType";
BA_DEF_ BO_  "VFrameFormat" ENUM  "StandardCAN","ExtendedCAN","reserved","reserved","reserved","reserved","reserved","reserved","reserved","reserved","reserved","reserved","reserved","reserved","StandardCAN_FD","ExtendedCAN_FD";
BA_DEF_ SG_  "GenSigFuncType" ENUM  "NoFunction","NotUsed","NotUsed","NotUsed","NotUsed","NotUsed","NotUsed","CHK";
BA_DEF_ SG_  "GenSigSendType" ENUM  "Cyclic","OnWrite","NotUsed","OnChange","NotUsed","NotUsed","NotUsed","NoSigSendType";
BA_DEF_ SG_  "GenSigStartValue" FLOAT 0 1215752192;
BA_DEF_ SG_  "GenSigTimeoutValue" INT 0 100000;
BA_DEF_ BU_  "NodeLayerModules" STRING ;
BA_DEF_  "BusType" STRING ;
BA_DEF_  "DBName" STRING ;
BA_DEF_  "ILTxTimeout" INT 0 100000;
BA_DEF_  "Manufacturer" STRING ;
BA_DEF_DEF_  "GenMsgCycleTime" 100;
BA_DEF_DEF_  "GenMsgILSupport" "Yes";
BA_DEF_DEF_  "GenMsgSendType" "Cyclic";
BA_DEF_DEF_  "VFrameFormat" "ExtendedCAN_FD";
BA_DEF_DEF_  "GenSigFuncType" "NoFunction";
BA_DEF_DEF_  "GenSigSendType" "NoSigSendType";
BA_DEF_DEF_  "GenSigStartValue" 0;
BA_DEF_DEF_  "GenSigTimeoutValue" 0;
BA_DEF_DEF_  "NodeLayerModules" "CANoeILNLToyota.dll";
BA_DEF_DEF_  "BusType" "";
BA_DEF_DEF_  "DBName" "";
BA_DEF_DEF_  "ILTxTimeout" 400;
BA_DEF_DEF_  "Manufacturer" "Toyota";
BA_ "BusType" "CAN FD";
BA_ "Manufacturer" "";
BA_ "DBName" "ARS410GY28_PrivateCAN";
BA_ "GenMsgCycleTime" BO_ 91 60;
BA_ "VFrameFormat" BO_ 91 14;
BA_ "GenMsgCycleTime" BO_ 71 60;
BA_ "VFrameFormat" BO_ 71 14;
BA_ "GenMsgCycleTime" BO_ 70 60;
BA_ "VFrameFormat" BO_ 70 14;
BA_ "GenMsgCycleTime" BO_ 69 60;
BA_ "VFrameFormat" BO_ 69 14;
BA_ "GenMsgCycleTime" BO_ 68 60;
BA_ "VFrameFormat" BO_ 68 14;
BA_ "GenMsgCycleTime" BO_ 67 60;
BA_ "VFrameFormat" BO_ 67 14;
BA_ "GenMsgCycleTime" BO_ 66 60;
BA_ "VFrameFormat" BO_ 66 14;
BA_ "GenMsgCycleTime" BO_ 65 60;
BA_ "VFrameFormat" BO_ 65 14;
BA_ "GenMsgCycleTime" BO_ 64 60;
BA_ "VFrameFormat" BO_ 64 14;
BA_ "GenMsgCycleTime" BO_ 63 60;
BA_ "VFrameFormat" BO_ 63 14;
BA_ "GenMsgCycleTime" BO_ 62 60;
BA_ "VFrameFormat" BO_ 62 14;
BA_ "GenMsgCycleTime" BO_ 61 60;
BA_ "VFrameFormat" BO_ 61 14;
BA_ "GenMsgCycleTime" BO_ 60 60;
BA_ "VFrameFormat" BO_ 60 14;
BA_ "GenMsgCycleTime" BO_ 59 60;
BA_ "VFrameFormat" BO_ 59 14;
BA_ "GenMsgCycleTime" BO_ 58 60;
BA_ "VFrameFormat" BO_ 58 14;
BA_ "GenMsgCycleTime" BO_ 57 60;
BA_ "VFrameFormat" BO_ 57 14;
BA_ "GenMsgCycleTime" BO_ 56 60;
BA_ "VFrameFormat" BO_ 56 14;
BA_ "GenMsgCycleTime" BO_ 55 60;
BA_ "VFrameFormat" BO_ 55 14;
BA_ "GenMsgCycleTime" BO_ 54 60;
BA_ "VFrameFormat" BO_ 54 14;
BA_ "GenMsgCycleTime" BO_ 53 60;
BA_ "VFrameFormat" BO_ 53 14;
BA_ "GenMsgCycleTime" BO_ 52 60;
BA_ "VFrameFormat" BO_ 52 14;
BA_ "GenMsgCycleTime" BO_ 51 60;
BA_ "VFrameFormat" BO_ 51 14;
BA_ "GenMsgCycleTime" BO_ 50 60;
BA_ "VFrameFormat" BO_ 50 14;
BA_ "GenMsgCycleTime" BO_ 49 60;
BA_ "VFrameFormat" BO_ 49 14;
BA_ "GenMsgCycleTime" BO_ 48 60;
BA_ "VFrameFormat" BO_ 48 14;
BA_ "GenMsgCycleTime" BO_ 47 60;
BA_ "VFrameFormat" BO_ 47 14;
BA_ "GenMsgCycleTime" BO_ 46 60;
BA_ "VFrameFormat" BO_ 46 14;
BA_ "GenMsgCycleTime" BO_ 45 60;
BA_ "VFrameFormat" BO_ 45 14;
BA_ "GenMsgCycleTime" BO_ 44 60;
BA_ "VFrameFormat" BO_ 44 14;
BA_ "GenMsgCycleTime" BO_ 43 60;
BA_ "VFrameFormat" BO_ 43 14;
BA_ "GenMsgCycleTime" BO_ 42 60;
BA_ "VFrameFormat" BO_ 42 14;
BA_ "GenMsgCycleTime" BO_ 41 60;
BA_ "VFrameFormat" BO_ 41 14;
BA_ "GenMsgCycleTime" BO_ 40 60;
BA_ "VFrameFormat" BO_ 40 14;
BA_ "GenMsgCycleTime" BO_ 39 60;
BA_ "VFrameFormat" BO_ 39 14;
BA_ "GenMsgCycleTime" BO_ 38 60;
BA_ "VFrameFormat" BO_ 38 14;
BA_ "GenMsgCycleTime" BO_ 37 60;
BA_ "VFrameFormat" BO_ 37 14;
BA_ "GenMsgCycleTime" BO_ 36 60;
BA_ "VFrameFormat" BO_ 36 14;
BA_ "GenMsgCycleTime" BO_ 35 60;
BA_ "VFrameFormat" BO_ 35 14;
BA_ "GenMsgCycleTime" BO_ 34 50;
BA_ "VFrameFormat" BO_ 34 14;
BA_ "GenMsgCycleTime" BO_ 33 60;
BA_ "VFrameFormat" BO_ 33 14;
BA_ "GenMsgCycleTime" BO_ 119 60;
BA_ "VFrameFormat" BO_ 119 14;
BA_ "GenMsgCycleTime" BO_ 118 60;
BA_ "VFrameFormat" BO_ 118 14;
BA_ "GenMsgCycleTime" BO_ 117 60;
BA_ "VFrameFormat" BO_ 117 14;
BA_ "GenMsgCycleTime" BO_ 116 60;
BA_ "VFrameFormat" BO_ 116 14;
BA_ "GenMsgCycleTime" BO_ 115 60;
BA_ "VFrameFormat" BO_ 115 14;
BA_ "GenMsgCycleTime" BO_ 114 60;
BA_ "VFrameFormat" BO_ 114 14;
BA_ "GenMsgCycleTime" BO_ 113 60;
BA_ "VFrameFormat" BO_ 113 14;
BA_ "GenSigTimeoutValue" SG_ 91 FRS_P1_11_Msg_AliveCounter 250;
BA_ "GenSigTimeoutValue" SG_ 91 FRS_P1_11_Msg_CheckSum 250;
BA_ "GenSigTimeoutValue" SG_ 91 FRS_P1_11_Obj_MotionPattern 250;
BA_ "GenSigTimeoutValue" SG_ 91 FRS_P1_11_Obj_YPos_Stdev 250;
BA_ "GenSigTimeoutValue" SG_ 91 FRS_P1_11_Obj_XVelRel_Stdev 250;
BA_ "GenSigTimeoutValue" SG_ 91 FRS_P1_11_Obj_XPos_Stdev 250;
BA_ "GenSigStartValue" SG_ 91 FRS_P1_11_Obj_XAccRel 64;
BA_ "GenSigTimeoutValue" SG_ 91 FRS_P1_11_Obj_XAccRel 250;
BA_ "GenSigTimeoutValue" SG_ 91 FRS_P1_11_Obj_ValidFlag 250;
BA_ "GenSigTimeoutValue" SG_ 91 FRS_P1_11_Obj_UpdateFlag 250;
BA_ "GenSigTimeoutValue" SG_ 91 FRS_P1_11_Obj_ObstacleProb 250;
BA_ "GenSigTimeoutValue" SG_ 91 FRS_P1_11_Obj_ID 250;
BA_ "GenSigTimeoutValue" SG_ 91 FRS_P1_11_Obj_ExstProb 250;
BA_ "GenSigStartValue" SG_ 71 FRS_P2_39_Obj_YVelRel 1024;
BA_ "GenSigTimeoutValue" SG_ 71 FRS_P2_39_Obj_YVelRel 250;
BA_ "GenSigStartValue" SG_ 71 FRS_P2_39_Obj_YPos 4096;
BA_ "GenSigTimeoutValue" SG_ 71 FRS_P2_39_Obj_YPos 250;
BA_ "GenSigStartValue" SG_ 71 FRS_P2_39_Obj_XVelRel 1024;
BA_ "GenSigTimeoutValue" SG_ 71 FRS_P2_39_Obj_XVelRel 250;
BA_ "GenSigTimeoutValue" SG_ 71 FRS_P2_39_Obj_XPos 250;
BA_ "GenSigTimeoutValue" SG_ 71 FRS_P2_39_Obj_Type 250;
BA_ "GenSigTimeoutValue" SG_ 71 FRS_P2_39_Obj_MeasFlag 250;
BA_ "GenSigTimeoutValue" SG_ 71 FRS_P2_39_Msg_AliveCounter 250;
BA_ "GenSigTimeoutValue" SG_ 71 FRS_P2_39_Msg_CheckSum 250;
BA_ "GenSigStartValue" SG_ 70 FRS_P2_38_Obj_YVelRel 1024;
BA_ "GenSigTimeoutValue" SG_ 70 FRS_P2_38_Obj_YVelRel 250;
BA_ "GenSigStartValue" SG_ 70 FRS_P2_38_Obj_YPos 4096;
BA_ "GenSigTimeoutValue" SG_ 70 FRS_P2_38_Obj_YPos 250;
BA_ "GenSigStartValue" SG_ 70 FRS_P2_38_Obj_XVelRel 1024;
BA_ "GenSigTimeoutValue" SG_ 70 FRS_P2_38_Obj_XVelRel 250;
BA_ "GenSigTimeoutValue" SG_ 70 FRS_P2_38_Obj_XPos 250;
BA_ "GenSigTimeoutValue" SG_ 70 FRS_P2_38_Obj_Type 250;
BA_ "GenSigTimeoutValue" SG_ 70 FRS_P2_38_Obj_MeasFlag 250;
BA_ "GenSigTimeoutValue" SG_ 70 FRS_P2_38_Msg_AliveCounter 250;
BA_ "GenSigTimeoutValue" SG_ 70 FRS_P2_38_Msg_CheckSum 250;
BA_ "GenSigStartValue" SG_ 69 FRS_P2_37_Obj_YVelRel 1024;
BA_ "GenSigTimeoutValue" SG_ 69 FRS_P2_37_Obj_YVelRel 250;
BA_ "GenSigStartValue" SG_ 69 FRS_P2_37_Obj_YPos 4096;
BA_ "GenSigTimeoutValue" SG_ 69 FRS_P2_37_Obj_YPos 250;
BA_ "GenSigStartValue" SG_ 69 FRS_P2_37_Obj_XVelRel 1024;
BA_ "GenSigTimeoutValue" SG_ 69 FRS_P2_37_Obj_XVelRel 250;
BA_ "GenSigTimeoutValue" SG_ 69 FRS_P2_37_Obj_XPos 250;
BA_ "GenSigTimeoutValue" SG_ 69 FRS_P2_37_Obj_Type 250;
BA_ "GenSigTimeoutValue" SG_ 69 FRS_P2_37_Obj_MeasFlag 250;
BA_ "GenSigTimeoutValue" SG_ 69 FRS_P2_37_Msg_AliveCounter 250;
BA_ "GenSigTimeoutValue" SG_ 69 FRS_P2_37_Msg_CheckSum 250;
BA_ "GenSigStartValue" SG_ 68 FRS_P2_36_Obj_YVelRel 1024;
BA_ "GenSigTimeoutValue" SG_ 68 FRS_P2_36_Obj_YVelRel 250;
BA_ "GenSigStartValue" SG_ 68 FRS_P2_36_Obj_YPos 4096;
BA_ "GenSigTimeoutValue" SG_ 68 FRS_P2_36_Obj_YPos 250;
BA_ "GenSigStartValue" SG_ 68 FRS_P2_36_Obj_XVelRel 1024;
BA_ "GenSigTimeoutValue" SG_ 68 FRS_P2_36_Obj_XVelRel 250;
BA_ "GenSigTimeoutValue" SG_ 68 FRS_P2_36_Obj_XPos 250;
BA_ "GenSigTimeoutValue" SG_ 68 FRS_P2_36_Obj_Type 250;
BA_ "GenSigTimeoutValue" SG_ 68 FRS_P2_36_Obj_MeasFlag 250;
BA_ "GenSigTimeoutValue" SG_ 68 FRS_P2_36_Msg_AliveCounter 250;
BA_ "GenSigTimeoutValue" SG_ 68 FRS_P2_36_Msg_CheckSum 250;
BA_ "GenSigStartValue" SG_ 67 FRS_P2_35_Obj_YVelRel 1024;
BA_ "GenSigTimeoutValue" SG_ 67 FRS_P2_35_Obj_YVelRel 250;
BA_ "GenSigStartValue" SG_ 67 FRS_P2_35_Obj_YPos 4096;
BA_ "GenSigTimeoutValue" SG_ 67 FRS_P2_35_Obj_YPos 250;
BA_ "GenSigStartValue" SG_ 67 FRS_P2_35_Obj_XVelRel 1024;
BA_ "GenSigTimeoutValue" SG_ 67 FRS_P2_35_Obj_XVelRel 250;
BA_ "GenSigTimeoutValue" SG_ 67 FRS_P2_35_Obj_XPos 250;
BA_ "GenSigTimeoutValue" SG_ 67 FRS_P2_35_Obj_Type 250;
BA_ "GenSigTimeoutValue" SG_ 67 FRS_P2_35_Obj_MeasFlag 250;
BA_ "GenSigTimeoutValue" SG_ 67 FRS_P2_35_Msg_AliveCounter 250;
BA_ "GenSigTimeoutValue" SG_ 67 FRS_P2_35_Msg_CheckSum 250;
BA_ "GenSigStartValue" SG_ 66 FRS_P2_34_Obj_YVelRel 1024;
BA_ "GenSigTimeoutValue" SG_ 66 FRS_P2_34_Obj_YVelRel 250;
BA_ "GenSigStartValue" SG_ 66 FRS_P2_34_Obj_YPos 4096;
BA_ "GenSigTimeoutValue" SG_ 66 FRS_P2_34_Obj_YPos 250;
BA_ "GenSigStartValue" SG_ 66 FRS_P2_34_Obj_XVelRel 1024;
BA_ "GenSigTimeoutValue" SG_ 66 FRS_P2_34_Obj_XVelRel 250;
BA_ "GenSigTimeoutValue" SG_ 66 FRS_P2_34_Obj_XPos 250;
BA_ "GenSigTimeoutValue" SG_ 66 FRS_P2_34_Obj_Type 250;
BA_ "GenSigTimeoutValue" SG_ 66 FRS_P2_34_Obj_MeasFlag 250;
BA_ "GenSigTimeoutValue" SG_ 66 FRS_P2_34_Msg_AliveCounter 250;
BA_ "GenSigTimeoutValue" SG_ 66 FRS_P2_34_Msg_CheckSum 250;
BA_ "GenSigStartValue" SG_ 65 FRS_P2_33_Obj_YVelRel 1024;
BA_ "GenSigTimeoutValue" SG_ 65 FRS_P2_33_Obj_YVelRel 250;
BA_ "GenSigStartValue" SG_ 65 FRS_P2_33_Obj_YPos 4096;
BA_ "GenSigTimeoutValue" SG_ 65 FRS_P2_33_Obj_YPos 250;
BA_ "GenSigStartValue" SG_ 65 FRS_P2_33_Obj_XVelRel 1024;
BA_ "GenSigTimeoutValue" SG_ 65 FRS_P2_33_Obj_XVelRel 250;
BA_ "GenSigTimeoutValue" SG_ 65 FRS_P2_33_Obj_XPos 250;
BA_ "GenSigTimeoutValue" SG_ 65 FRS_P2_33_Obj_Type 250;
BA_ "GenSigTimeoutValue" SG_ 65 FRS_P2_33_Obj_MeasFlag 250;
BA_ "GenSigTimeoutValue" SG_ 65 FRS_P2_33_Msg_AliveCounter 250;
BA_ "GenSigTimeoutValue" SG_ 65 FRS_P2_33_Msg_CheckSum 250;
BA_ "GenSigStartValue" SG_ 64 FRS_P2_32_Obj_YVelRel 1024;
BA_ "GenSigTimeoutValue" SG_ 64 FRS_P2_32_Obj_YVelRel 250;
BA_ "GenSigStartValue" SG_ 64 FRS_P2_32_Obj_YPos 4096;
BA_ "GenSigTimeoutValue" SG_ 64 FRS_P2_32_Obj_YPos 250;
BA_ "GenSigStartValue" SG_ 64 FRS_P2_32_Obj_XVelRel 1024;
BA_ "GenSigTimeoutValue" SG_ 64 FRS_P2_32_Obj_XVelRel 250;
BA_ "GenSigTimeoutValue" SG_ 64 FRS_P2_32_Obj_XPos 250;
BA_ "GenSigTimeoutValue" SG_ 64 FRS_P2_32_Obj_Type 250;
BA_ "GenSigTimeoutValue" SG_ 64 FRS_P2_32_Obj_MeasFlag 250;
BA_ "GenSigTimeoutValue" SG_ 64 FRS_P2_32_Msg_AliveCounter 250;
BA_ "GenSigTimeoutValue" SG_ 64 FRS_P2_32_Msg_CheckSum 250;
BA_ "GenSigStartValue" SG_ 63 FRS_P2_31_Obj_YVelRel 1024;
BA_ "GenSigTimeoutValue" SG_ 63 FRS_P2_31_Obj_YVelRel 250;
BA_ "GenSigStartValue" SG_ 63 FRS_P2_31_Obj_YPos 4096;
BA_ "GenSigTimeoutValue" SG_ 63 FRS_P2_31_Obj_YPos 250;
BA_ "GenSigStartValue" SG_ 63 FRS_P2_31_Obj_XVelRel 1024;
BA_ "GenSigTimeoutValue" SG_ 63 FRS_P2_31_Obj_XVelRel 250;
BA_ "GenSigTimeoutValue" SG_ 63 FRS_P2_31_Obj_XPos 250;
BA_ "GenSigTimeoutValue" SG_ 63 FRS_P2_31_Obj_Type 250;
BA_ "GenSigTimeoutValue" SG_ 63 FRS_P2_31_Obj_MeasFlag 250;
BA_ "GenSigTimeoutValue" SG_ 63 FRS_P2_31_Msg_AliveCounter 250;
BA_ "GenSigTimeoutValue" SG_ 63 FRS_P2_31_Msg_CheckSum 250;
BA_ "GenSigStartValue" SG_ 62 FRS_P2_30_Obj_YVelRel 1024;
BA_ "GenSigTimeoutValue" SG_ 62 FRS_P2_30_Obj_YVelRel 250;
BA_ "GenSigStartValue" SG_ 62 FRS_P2_30_Obj_YPos 4096;
BA_ "GenSigTimeoutValue" SG_ 62 FRS_P2_30_Obj_YPos 250;
BA_ "GenSigStartValue" SG_ 62 FRS_P2_30_Obj_XVelRel 1024;
BA_ "GenSigTimeoutValue" SG_ 62 FRS_P2_30_Obj_XVelRel 250;
BA_ "GenSigTimeoutValue" SG_ 62 FRS_P2_30_Obj_XPos 250;
BA_ "GenSigTimeoutValue" SG_ 62 FRS_P2_30_Obj_Type 250;
BA_ "GenSigTimeoutValue" SG_ 62 FRS_P2_30_Obj_MeasFlag 250;
BA_ "GenSigTimeoutValue" SG_ 62 FRS_P2_30_Msg_AliveCounter 250;
BA_ "GenSigTimeoutValue" SG_ 62 FRS_P2_30_Msg_CheckSum 250;
BA_ "GenSigStartValue" SG_ 61 FRS_P2_29_Obj_YVelRel 1024;
BA_ "GenSigTimeoutValue" SG_ 61 FRS_P2_29_Obj_YVelRel 250;
BA_ "GenSigStartValue" SG_ 61 FRS_P2_29_Obj_YPos 4096;
BA_ "GenSigTimeoutValue" SG_ 61 FRS_P2_29_Obj_YPos 250;
BA_ "GenSigStartValue" SG_ 61 FRS_P2_29_Obj_XVelRel 1024;
BA_ "GenSigTimeoutValue" SG_ 61 FRS_P2_29_Obj_XVelRel 250;
BA_ "GenSigTimeoutValue" SG_ 61 FRS_P2_29_Obj_XPos 250;
BA_ "GenSigTimeoutValue" SG_ 61 FRS_P2_29_Obj_Type 250;
BA_ "GenSigTimeoutValue" SG_ 61 FRS_P2_29_Obj_MeasFlag 250;
BA_ "GenSigTimeoutValue" SG_ 61 FRS_P2_29_Msg_AliveCounter 250;
BA_ "GenSigTimeoutValue" SG_ 61 FRS_P2_29_Msg_CheckSum 250;
BA_ "GenSigStartValue" SG_ 60 FRS_P2_28_Obj_YVelRel 1024;
BA_ "GenSigTimeoutValue" SG_ 60 FRS_P2_28_Obj_YVelRel 250;
BA_ "GenSigStartValue" SG_ 60 FRS_P2_28_Obj_YPos 4096;
BA_ "GenSigTimeoutValue" SG_ 60 FRS_P2_28_Obj_YPos 250;
BA_ "GenSigStartValue" SG_ 60 FRS_P2_28_Obj_XVelRel 1024;
BA_ "GenSigTimeoutValue" SG_ 60 FRS_P2_28_Obj_XVelRel 250;
BA_ "GenSigTimeoutValue" SG_ 60 FRS_P2_28_Obj_XPos 250;
BA_ "GenSigTimeoutValue" SG_ 60 FRS_P2_28_Obj_Type 250;
BA_ "GenSigTimeoutValue" SG_ 60 FRS_P2_28_Obj_MeasFlag 250;
BA_ "GenSigTimeoutValue" SG_ 60 FRS_P2_28_Msg_AliveCounter 250;
BA_ "GenSigTimeoutValue" SG_ 60 FRS_P2_28_Msg_CheckSum 250;
BA_ "GenSigStartValue" SG_ 59 FRS_P2_27_Obj_YVelRel 1024;
BA_ "GenSigTimeoutValue" SG_ 59 FRS_P2_27_Obj_YVelRel 250;
BA_ "GenSigStartValue" SG_ 59 FRS_P2_27_Obj_YPos 4096;
BA_ "GenSigTimeoutValue" SG_ 59 FRS_P2_27_Obj_YPos 250;
BA_ "GenSigStartValue" SG_ 59 FRS_P2_27_Obj_XVelRel 1024;
BA_ "GenSigTimeoutValue" SG_ 59 FRS_P2_27_Obj_XVelRel 250;
BA_ "GenSigTimeoutValue" SG_ 59 FRS_P2_27_Obj_XPos 250;
BA_ "GenSigTimeoutValue" SG_ 59 FRS_P2_27_Obj_Type 250;
BA_ "GenSigTimeoutValue" SG_ 59 FRS_P2_27_Obj_MeasFlag 250;
BA_ "GenSigTimeoutValue" SG_ 59 FRS_P2_27_Msg_AliveCounter 250;
BA_ "GenSigTimeoutValue" SG_ 59 FRS_P2_27_Msg_CheckSum 250;
BA_ "GenSigStartValue" SG_ 58 FRS_P2_26_Obj_YVelRel 1024;
BA_ "GenSigTimeoutValue" SG_ 58 FRS_P2_26_Obj_YVelRel 250;
BA_ "GenSigStartValue" SG_ 58 FRS_P2_26_Obj_YPos 4096;
BA_ "GenSigTimeoutValue" SG_ 58 FRS_P2_26_Obj_YPos 250;
BA_ "GenSigStartValue" SG_ 58 FRS_P2_26_Obj_XVelRel 1024;
BA_ "GenSigTimeoutValue" SG_ 58 FRS_P2_26_Obj_XVelRel 250;
BA_ "GenSigTimeoutValue" SG_ 58 FRS_P2_26_Obj_XPos 250;
BA_ "GenSigTimeoutValue" SG_ 58 FRS_P2_26_Obj_Type 250;
BA_ "GenSigTimeoutValue" SG_ 58 FRS_P2_26_Obj_MeasFlag 250;
BA_ "GenSigTimeoutValue" SG_ 58 FRS_P2_26_Msg_AliveCounter 250;
BA_ "GenSigTimeoutValue" SG_ 58 FRS_P2_26_Msg_CheckSum 250;
BA_ "GenSigStartValue" SG_ 57 FRS_P2_25_Obj_YVelRel 1024;
BA_ "GenSigTimeoutValue" SG_ 57 FRS_P2_25_Obj_YVelRel 250;
BA_ "GenSigStartValue" SG_ 57 FRS_P2_25_Obj_YPos 4096;
BA_ "GenSigTimeoutValue" SG_ 57 FRS_P2_25_Obj_YPos 250;
BA_ "GenSigStartValue" SG_ 57 FRS_P2_25_Obj_XVelRel 1024;
BA_ "GenSigTimeoutValue" SG_ 57 FRS_P2_25_Obj_XVelRel 250;
BA_ "GenSigTimeoutValue" SG_ 57 FRS_P2_25_Obj_XPos 250;
BA_ "GenSigTimeoutValue" SG_ 57 FRS_P2_25_Obj_Type 250;
BA_ "GenSigTimeoutValue" SG_ 57 FRS_P2_25_Obj_MeasFlag 250;
BA_ "GenSigTimeoutValue" SG_ 57 FRS_P2_25_Msg_AliveCounter 250;
BA_ "GenSigTimeoutValue" SG_ 57 FRS_P2_25_Msg_CheckSum 250;
BA_ "GenSigStartValue" SG_ 56 FRS_P2_24_Obj_YVelRel 1024;
BA_ "GenSigTimeoutValue" SG_ 56 FRS_P2_24_Obj_YVelRel 250;
BA_ "GenSigStartValue" SG_ 56 FRS_P2_24_Obj_YPos 4096;
BA_ "GenSigTimeoutValue" SG_ 56 FRS_P2_24_Obj_YPos 250;
BA_ "GenSigStartValue" SG_ 56 FRS_P2_24_Obj_XVelRel 1024;
BA_ "GenSigTimeoutValue" SG_ 56 FRS_P2_24_Obj_XVelRel 250;
BA_ "GenSigTimeoutValue" SG_ 56 FRS_P2_24_Obj_XPos 250;
BA_ "GenSigTimeoutValue" SG_ 56 FRS_P2_24_Obj_Type 250;
BA_ "GenSigTimeoutValue" SG_ 56 FRS_P2_24_Obj_MeasFlag 250;
BA_ "GenSigTimeoutValue" SG_ 56 FRS_P2_24_Msg_AliveCounter 250;
BA_ "GenSigTimeoutValue" SG_ 56 FRS_P2_24_Msg_CheckSum 250;
BA_ "GenSigStartValue" SG_ 55 FRS_P2_23_Obj_YVelRel 1024;
BA_ "GenSigTimeoutValue" SG_ 55 FRS_P2_23_Obj_YVelRel 250;
BA_ "GenSigStartValue" SG_ 55 FRS_P2_23_Obj_YPos 4096;
BA_ "GenSigTimeoutValue" SG_ 55 FRS_P2_23_Obj_YPos 250;
BA_ "GenSigStartValue" SG_ 55 FRS_P2_23_Obj_XVelRel 1024;
BA_ "GenSigTimeoutValue" SG_ 55 FRS_P2_23_Obj_XVelRel 250;
BA_ "GenSigTimeoutValue" SG_ 55 FRS_P2_23_Obj_XPos 250;
BA_ "GenSigTimeoutValue" SG_ 55 FRS_P2_23_Obj_Type 250;
BA_ "GenSigTimeoutValue" SG_ 55 FRS_P2_23_Obj_MeasFlag 250;
BA_ "GenSigTimeoutValue" SG_ 55 FRS_P2_23_Msg_AliveCounter 250;
BA_ "GenSigTimeoutValue" SG_ 55 FRS_P2_23_Msg_CheckSum 250;
BA_ "GenSigStartValue" SG_ 54 FRS_P2_22_Obj_YVelRel 1024;
BA_ "GenSigTimeoutValue" SG_ 54 FRS_P2_22_Obj_YVelRel 250;
BA_ "GenSigStartValue" SG_ 54 FRS_P2_22_Obj_YPos 4096;
BA_ "GenSigTimeoutValue" SG_ 54 FRS_P2_22_Obj_YPos 250;
BA_ "GenSigStartValue" SG_ 54 FRS_P2_22_Obj_XVelRel 1024;
BA_ "GenSigTimeoutValue" SG_ 54 FRS_P2_22_Obj_XVelRel 250;
BA_ "GenSigTimeoutValue" SG_ 54 FRS_P2_22_Obj_XPos 250;
BA_ "GenSigTimeoutValue" SG_ 54 FRS_P2_22_Obj_Type 250;
BA_ "GenSigTimeoutValue" SG_ 54 FRS_P2_22_Obj_MeasFlag 250;
BA_ "GenSigTimeoutValue" SG_ 54 FRS_P2_22_Msg_AliveCounter 250;
BA_ "GenSigTimeoutValue" SG_ 54 FRS_P2_22_Msg_CheckSum 250;
BA_ "GenSigStartValue" SG_ 53 FRS_P2_21_Obj_YVelRel 1024;
BA_ "GenSigTimeoutValue" SG_ 53 FRS_P2_21_Obj_YVelRel 250;
BA_ "GenSigStartValue" SG_ 53 FRS_P2_21_Obj_YPos 4096;
BA_ "GenSigTimeoutValue" SG_ 53 FRS_P2_21_Obj_YPos 250;
BA_ "GenSigStartValue" SG_ 53 FRS_P2_21_Obj_XVelRel 1024;
BA_ "GenSigTimeoutValue" SG_ 53 FRS_P2_21_Obj_XVelRel 250;
BA_ "GenSigTimeoutValue" SG_ 53 FRS_P2_21_Obj_XPos 250;
BA_ "GenSigTimeoutValue" SG_ 53 FRS_P2_21_Obj_Type 250;
BA_ "GenSigTimeoutValue" SG_ 53 FRS_P2_21_Obj_MeasFlag 250;
BA_ "GenSigTimeoutValue" SG_ 53 FRS_P2_21_Msg_AliveCounter 250;
BA_ "GenSigTimeoutValue" SG_ 53 FRS_P2_21_Msg_CheckSum 250;
BA_ "GenSigStartValue" SG_ 52 FRS_P2_20_Obj_YVelRel 1024;
BA_ "GenSigTimeoutValue" SG_ 52 FRS_P2_20_Obj_YVelRel 250;
BA_ "GenSigStartValue" SG_ 52 FRS_P2_20_Obj_YPos 4096;
BA_ "GenSigTimeoutValue" SG_ 52 FRS_P2_20_Obj_YPos 250;
BA_ "GenSigStartValue" SG_ 52 FRS_P2_20_Obj_XVelRel 1024;
BA_ "GenSigTimeoutValue" SG_ 52 FRS_P2_20_Obj_XVelRel 250;
BA_ "GenSigTimeoutValue" SG_ 52 FRS_P2_20_Obj_XPos 250;
BA_ "GenSigTimeoutValue" SG_ 52 FRS_P2_20_Obj_Type 250;
BA_ "GenSigTimeoutValue" SG_ 52 FRS_P2_20_Obj_MeasFlag 250;
BA_ "GenSigTimeoutValue" SG_ 52 FRS_P2_20_Msg_AliveCounter 250;
BA_ "GenSigTimeoutValue" SG_ 52 FRS_P2_20_Msg_CheckSum 250;
BA_ "GenSigStartValue" SG_ 51 FRS_P2_19_Obj_YVelRel 1024;
BA_ "GenSigTimeoutValue" SG_ 51 FRS_P2_19_Obj_YVelRel 250;
BA_ "GenSigStartValue" SG_ 51 FRS_P2_19_Obj_YPos 4096;
BA_ "GenSigTimeoutValue" SG_ 51 FRS_P2_19_Obj_YPos 250;
BA_ "GenSigStartValue" SG_ 51 FRS_P2_19_Obj_XVelRel 1024;
BA_ "GenSigTimeoutValue" SG_ 51 FRS_P2_19_Obj_XVelRel 250;
BA_ "GenSigTimeoutValue" SG_ 51 FRS_P2_19_Obj_XPos 250;
BA_ "GenSigTimeoutValue" SG_ 51 FRS_P2_19_Obj_Type 250;
BA_ "GenSigTimeoutValue" SG_ 51 FRS_P2_19_Obj_MeasFlag 250;
BA_ "GenSigTimeoutValue" SG_ 51 FRS_P2_19_Msg_AliveCounter 250;
BA_ "GenSigTimeoutValue" SG_ 51 FRS_P2_19_Msg_CheckSum 250;
BA_ "GenSigStartValue" SG_ 50 FRS_P2_18_Obj_YVelRel 1024;
BA_ "GenSigTimeoutValue" SG_ 50 FRS_P2_18_Obj_YVelRel 250;
BA_ "GenSigStartValue" SG_ 50 FRS_P2_18_Obj_YPos 4096;
BA_ "GenSigTimeoutValue" SG_ 50 FRS_P2_18_Obj_YPos 250;
BA_ "GenSigStartValue" SG_ 50 FRS_P2_18_Obj_XVelRel 1024;
BA_ "GenSigTimeoutValue" SG_ 50 FRS_P2_18_Obj_XVelRel 250;
BA_ "GenSigTimeoutValue" SG_ 50 FRS_P2_18_Obj_XPos 250;
BA_ "GenSigTimeoutValue" SG_ 50 FRS_P2_18_Obj_Type 250;
BA_ "GenSigTimeoutValue" SG_ 50 FRS_P2_18_Obj_MeasFlag 250;
BA_ "GenSigTimeoutValue" SG_ 50 FRS_P2_18_Msg_AliveCounter 250;
BA_ "GenSigTimeoutValue" SG_ 50 FRS_P2_18_Msg_CheckSum 250;
BA_ "GenSigStartValue" SG_ 49 FRS_P2_17_Obj_YVelRel 1024;
BA_ "GenSigTimeoutValue" SG_ 49 FRS_P2_17_Obj_YVelRel 250;
BA_ "GenSigStartValue" SG_ 49 FRS_P2_17_Obj_YPos 4096;
BA_ "GenSigTimeoutValue" SG_ 49 FRS_P2_17_Obj_YPos 250;
BA_ "GenSigStartValue" SG_ 49 FRS_P2_17_Obj_XVelRel 1024;
BA_ "GenSigTimeoutValue" SG_ 49 FRS_P2_17_Obj_XVelRel 250;
BA_ "GenSigTimeoutValue" SG_ 49 FRS_P2_17_Obj_XPos 250;
BA_ "GenSigTimeoutValue" SG_ 49 FRS_P2_17_Obj_Type 250;
BA_ "GenSigTimeoutValue" SG_ 49 FRS_P2_17_Obj_MeasFlag 250;
BA_ "GenSigTimeoutValue" SG_ 49 FRS_P2_17_Msg_AliveCounter 250;
BA_ "GenSigTimeoutValue" SG_ 49 FRS_P2_17_Msg_CheckSum 250;
BA_ "GenSigStartValue" SG_ 48 FRS_P2_16_Obj_YVelRel 1024;
BA_ "GenSigTimeoutValue" SG_ 48 FRS_P2_16_Obj_YVelRel 250;
BA_ "GenSigStartValue" SG_ 48 FRS_P2_16_Obj_YPos 4096;
BA_ "GenSigTimeoutValue" SG_ 48 FRS_P2_16_Obj_YPos 250;
BA_ "GenSigStartValue" SG_ 48 FRS_P2_16_Obj_XVelRel 1024;
BA_ "GenSigTimeoutValue" SG_ 48 FRS_P2_16_Obj_XVelRel 250;
BA_ "GenSigTimeoutValue" SG_ 48 FRS_P2_16_Obj_XPos 250;
BA_ "GenSigTimeoutValue" SG_ 48 FRS_P2_16_Obj_Type 250;
BA_ "GenSigTimeoutValue" SG_ 48 FRS_P2_16_Obj_MeasFlag 250;
BA_ "GenSigTimeoutValue" SG_ 48 FRS_P2_16_Msg_AliveCounter 250;
BA_ "GenSigTimeoutValue" SG_ 48 FRS_P2_16_Msg_CheckSum 250;
BA_ "GenSigStartValue" SG_ 47 FRS_P2_15_Obj_YVelRel 1024;
BA_ "GenSigTimeoutValue" SG_ 47 FRS_P2_15_Obj_YVelRel 250;
BA_ "GenSigStartValue" SG_ 47 FRS_P2_15_Obj_YPos 4096;
BA_ "GenSigTimeoutValue" SG_ 47 FRS_P2_15_Obj_YPos 250;
BA_ "GenSigStartValue" SG_ 47 FRS_P2_15_Obj_XVelRel 1024;
BA_ "GenSigTimeoutValue" SG_ 47 FRS_P2_15_Obj_XVelRel 250;
BA_ "GenSigTimeoutValue" SG_ 47 FRS_P2_15_Obj_XPos 250;
BA_ "GenSigTimeoutValue" SG_ 47 FRS_P2_15_Obj_Type 250;
BA_ "GenSigTimeoutValue" SG_ 47 FRS_P2_15_Obj_MeasFlag 250;
BA_ "GenSigTimeoutValue" SG_ 47 FRS_P2_15_Msg_AliveCounter 250;
BA_ "GenSigTimeoutValue" SG_ 47 FRS_P2_15_Msg_CheckSum 250;
BA_ "GenSigStartValue" SG_ 46 FRS_P2_14_Obj_YVelRel 1024;
BA_ "GenSigTimeoutValue" SG_ 46 FRS_P2_14_Obj_YVelRel 250;
BA_ "GenSigStartValue" SG_ 46 FRS_P2_14_Obj_YPos 4096;
BA_ "GenSigTimeoutValue" SG_ 46 FRS_P2_14_Obj_YPos 250;
BA_ "GenSigStartValue" SG_ 46 FRS_P2_14_Obj_XVelRel 1024;
BA_ "GenSigTimeoutValue" SG_ 46 FRS_P2_14_Obj_XVelRel 250;
BA_ "GenSigTimeoutValue" SG_ 46 FRS_P2_14_Obj_XPos 250;
BA_ "GenSigTimeoutValue" SG_ 46 FRS_P2_14_Obj_Type 250;
BA_ "GenSigTimeoutValue" SG_ 46 FRS_P2_14_Obj_MeasFlag 250;
BA_ "GenSigTimeoutValue" SG_ 46 FRS_P2_14_Msg_AliveCounter 250;
BA_ "GenSigTimeoutValue" SG_ 46 FRS_P2_14_Msg_CheckSum 250;
BA_ "GenSigStartValue" SG_ 45 FRS_P2_13_Obj_YVelRel 1024;
BA_ "GenSigTimeoutValue" SG_ 45 FRS_P2_13_Obj_YVelRel 250;
BA_ "GenSigStartValue" SG_ 45 FRS_P2_13_Obj_YPos 4096;
BA_ "GenSigTimeoutValue" SG_ 45 FRS_P2_13_Obj_YPos 250;
BA_ "GenSigStartValue" SG_ 45 FRS_P2_13_Obj_XVelRel 1024;
BA_ "GenSigTimeoutValue" SG_ 45 FRS_P2_13_Obj_XVelRel 250;
BA_ "GenSigTimeoutValue" SG_ 45 FRS_P2_13_Obj_XPos 250;
BA_ "GenSigTimeoutValue" SG_ 45 FRS_P2_13_Obj_Type 250;
BA_ "GenSigTimeoutValue" SG_ 45 FRS_P2_13_Obj_MeasFlag 250;
BA_ "GenSigTimeoutValue" SG_ 45 FRS_P2_13_Msg_AliveCounter 250;
BA_ "GenSigTimeoutValue" SG_ 45 FRS_P2_13_Msg_CheckSum 250;
BA_ "GenSigStartValue" SG_ 44 FRS_P2_12_Obj_YVelRel 1024;
BA_ "GenSigTimeoutValue" SG_ 44 FRS_P2_12_Obj_YVelRel 250;
BA_ "GenSigStartValue" SG_ 44 FRS_P2_12_Obj_YPos 4096;
BA_ "GenSigTimeoutValue" SG_ 44 FRS_P2_12_Obj_YPos 250;
BA_ "GenSigStartValue" SG_ 44 FRS_P2_12_Obj_XVelRel 1024;
BA_ "GenSigTimeoutValue" SG_ 44 FRS_P2_12_Obj_XVelRel 250;
BA_ "GenSigTimeoutValue" SG_ 44 FRS_P2_12_Obj_XPos 250;
BA_ "GenSigTimeoutValue" SG_ 44 FRS_P2_12_Obj_Type 250;
BA_ "GenSigTimeoutValue" SG_ 44 FRS_P2_12_Obj_MeasFlag 250;
BA_ "GenSigTimeoutValue" SG_ 44 FRS_P2_12_Msg_AliveCounter 250;
BA_ "GenSigTimeoutValue" SG_ 44 FRS_P2_12_Msg_CheckSum 250;
BA_ "GenSigStartValue" SG_ 43 FRS_P2_11_Obj_YVelRel 1024;
BA_ "GenSigTimeoutValue" SG_ 43 FRS_P2_11_Obj_YVelRel 250;
BA_ "GenSigStartValue" SG_ 43 FRS_P2_11_Obj_YPos 4096;
BA_ "GenSigTimeoutValue" SG_ 43 FRS_P2_11_Obj_YPos 250;
BA_ "GenSigStartValue" SG_ 43 FRS_P2_11_Obj_XVelRel 1024;
BA_ "GenSigTimeoutValue" SG_ 43 FRS_P2_11_Obj_XVelRel 250;
BA_ "GenSigTimeoutValue" SG_ 43 FRS_P2_11_Obj_XPos 250;
BA_ "GenSigTimeoutValue" SG_ 43 FRS_P2_11_Obj_Type 250;
BA_ "GenSigTimeoutValue" SG_ 43 FRS_P2_11_Obj_MeasFlag 250;
BA_ "GenSigTimeoutValue" SG_ 43 FRS_P2_11_Msg_AliveCounter 250;
BA_ "GenSigTimeoutValue" SG_ 43 FRS_P2_11_Msg_CheckSum 250;
BA_ "GenSigStartValue" SG_ 42 FRS_P2_10_Obj_YVelRel 1024;
BA_ "GenSigTimeoutValue" SG_ 42 FRS_P2_10_Obj_YVelRel 250;
BA_ "GenSigStartValue" SG_ 42 FRS_P2_10_Obj_YPos 4096;
BA_ "GenSigTimeoutValue" SG_ 42 FRS_P2_10_Obj_YPos 250;
BA_ "GenSigStartValue" SG_ 42 FRS_P2_10_Obj_XVelRel 1024;
BA_ "GenSigTimeoutValue" SG_ 42 FRS_P2_10_Obj_XVelRel 250;
BA_ "GenSigTimeoutValue" SG_ 42 FRS_P2_10_Obj_XPos 250;
BA_ "GenSigTimeoutValue" SG_ 42 FRS_P2_10_Obj_Type 250;
BA_ "GenSigTimeoutValue" SG_ 42 FRS_P2_10_Obj_MeasFlag 250;
BA_ "GenSigTimeoutValue" SG_ 42 FRS_P2_10_Msg_AliveCounter 250;
BA_ "GenSigTimeoutValue" SG_ 42 FRS_P2_10_Msg_CheckSum 250;
BA_ "GenSigStartValue" SG_ 41 FRS_P2_09_Obj_YVelRel 1024;
BA_ "GenSigTimeoutValue" SG_ 41 FRS_P2_09_Obj_YVelRel 250;
BA_ "GenSigStartValue" SG_ 41 FRS_P2_09_Obj_YPos 4096;
BA_ "GenSigTimeoutValue" SG_ 41 FRS_P2_09_Obj_YPos 250;
BA_ "GenSigStartValue" SG_ 41 FRS_P2_09_Obj_XVelRel 1024;
BA_ "GenSigTimeoutValue" SG_ 41 FRS_P2_09_Obj_XVelRel 250;
BA_ "GenSigTimeoutValue" SG_ 41 FRS_P2_09_Obj_XPos 250;
BA_ "GenSigTimeoutValue" SG_ 41 FRS_P2_09_Obj_Type 250;
BA_ "GenSigTimeoutValue" SG_ 41 FRS_P2_09_Obj_MeasFlag 250;
BA_ "GenSigTimeoutValue" SG_ 41 FRS_P2_09_Msg_AliveCounter 250;
BA_ "GenSigTimeoutValue" SG_ 41 FRS_P2_09_Msg_CheckSum 250;
BA_ "GenSigStartValue" SG_ 40 FRS_P2_08_Obj_YVelRel 1024;
BA_ "GenSigTimeoutValue" SG_ 40 FRS_P2_08_Obj_YVelRel 250;
BA_ "GenSigStartValue" SG_ 40 FRS_P2_08_Obj_YPos 4096;
BA_ "GenSigTimeoutValue" SG_ 40 FRS_P2_08_Obj_YPos 250;
BA_ "GenSigStartValue" SG_ 40 FRS_P2_08_Obj_XVelRel 1024;
BA_ "GenSigTimeoutValue" SG_ 40 FRS_P2_08_Obj_XVelRel 250;
BA_ "GenSigTimeoutValue" SG_ 40 FRS_P2_08_Obj_XPos 250;
BA_ "GenSigTimeoutValue" SG_ 40 FRS_P2_08_Obj_Type 250;
BA_ "GenSigTimeoutValue" SG_ 40 FRS_P2_08_Obj_MeasFlag 250;
BA_ "GenSigTimeoutValue" SG_ 40 FRS_P2_08_Msg_AliveCounter 250;
BA_ "GenSigTimeoutValue" SG_ 40 FRS_P2_08_Msg_CheckSum 250;
BA_ "GenSigStartValue" SG_ 39 FRS_P2_07_Obj_YVelRel 1024;
BA_ "GenSigTimeoutValue" SG_ 39 FRS_P2_07_Obj_YVelRel 250;
BA_ "GenSigStartValue" SG_ 39 FRS_P2_07_Obj_YPos 4096;
BA_ "GenSigTimeoutValue" SG_ 39 FRS_P2_07_Obj_YPos 250;
BA_ "GenSigStartValue" SG_ 39 FRS_P2_07_Obj_XVelRel 1024;
BA_ "GenSigTimeoutValue" SG_ 39 FRS_P2_07_Obj_XVelRel 250;
BA_ "GenSigTimeoutValue" SG_ 39 FRS_P2_07_Obj_XPos 250;
BA_ "GenSigTimeoutValue" SG_ 39 FRS_P2_07_Obj_Type 250;
BA_ "GenSigTimeoutValue" SG_ 39 FRS_P2_07_Obj_MeasFlag 250;
BA_ "GenSigTimeoutValue" SG_ 39 FRS_P2_07_Msg_AliveCounter 250;
BA_ "GenSigTimeoutValue" SG_ 39 FRS_P2_07_Msg_CheckSum 250;
BA_ "GenSigStartValue" SG_ 38 FRS_P2_06_Obj_YVelRel 1024;
BA_ "GenSigTimeoutValue" SG_ 38 FRS_P2_06_Obj_YVelRel 250;
BA_ "GenSigStartValue" SG_ 38 FRS_P2_06_Obj_YPos 4096;
BA_ "GenSigTimeoutValue" SG_ 38 FRS_P2_06_Obj_YPos 250;
BA_ "GenSigStartValue" SG_ 38 FRS_P2_06_Obj_XVelRel 1024;
BA_ "GenSigTimeoutValue" SG_ 38 FRS_P2_06_Obj_XVelRel 250;
BA_ "GenSigTimeoutValue" SG_ 38 FRS_P2_06_Obj_XPos 250;
BA_ "GenSigTimeoutValue" SG_ 38 FRS_P2_06_Obj_Type 250;
BA_ "GenSigTimeoutValue" SG_ 38 FRS_P2_06_Obj_MeasFlag 250;
BA_ "GenSigTimeoutValue" SG_ 38 FRS_P2_06_Msg_AliveCounter 250;
BA_ "GenSigTimeoutValue" SG_ 38 FRS_P2_06_Msg_CheckSum 250;
BA_ "GenSigStartValue" SG_ 37 FRS_P2_05_Obj_YVelRel 1024;
BA_ "GenSigTimeoutValue" SG_ 37 FRS_P2_05_Obj_YVelRel 250;
BA_ "GenSigStartValue" SG_ 37 FRS_P2_05_Obj_YPos 4096;
BA_ "GenSigTimeoutValue" SG_ 37 FRS_P2_05_Obj_YPos 250;
BA_ "GenSigStartValue" SG_ 37 FRS_P2_05_Obj_XVelRel 1024;
BA_ "GenSigTimeoutValue" SG_ 37 FRS_P2_05_Obj_XVelRel 250;
BA_ "GenSigTimeoutValue" SG_ 37 FRS_P2_05_Obj_XPos 250;
BA_ "GenSigTimeoutValue" SG_ 37 FRS_P2_05_Obj_Type 250;
BA_ "GenSigTimeoutValue" SG_ 37 FRS_P2_05_Obj_MeasFlag 250;
BA_ "GenSigTimeoutValue" SG_ 37 FRS_P2_05_Msg_AliveCounter 250;
BA_ "GenSigTimeoutValue" SG_ 37 FRS_P2_05_Msg_CheckSum 250;
BA_ "GenSigStartValue" SG_ 36 FRS_P2_04_Obj_YVelRel 1024;
BA_ "GenSigTimeoutValue" SG_ 36 FRS_P2_04_Obj_YVelRel 250;
BA_ "GenSigStartValue" SG_ 36 FRS_P2_04_Obj_YPos 4096;
BA_ "GenSigTimeoutValue" SG_ 36 FRS_P2_04_Obj_YPos 250;
BA_ "GenSigStartValue" SG_ 36 FRS_P2_04_Obj_XVelRel 1024;
BA_ "GenSigTimeoutValue" SG_ 36 FRS_P2_04_Obj_XVelRel 250;
BA_ "GenSigTimeoutValue" SG_ 36 FRS_P2_04_Obj_XPos 250;
BA_ "GenSigTimeoutValue" SG_ 36 FRS_P2_04_Obj_Type 250;
BA_ "GenSigTimeoutValue" SG_ 36 FRS_P2_04_Obj_MeasFlag 250;
BA_ "GenSigTimeoutValue" SG_ 36 FRS_P2_04_Msg_AliveCounter 250;
BA_ "GenSigTimeoutValue" SG_ 36 FRS_P2_04_Msg_CheckSum 250;
BA_ "GenSigStartValue" SG_ 35 FRS_P2_03_Obj_YVelRel 1024;
BA_ "GenSigTimeoutValue" SG_ 35 FRS_P2_03_Obj_YVelRel 250;
BA_ "GenSigStartValue" SG_ 35 FRS_P2_03_Obj_YPos 4096;
BA_ "GenSigTimeoutValue" SG_ 35 FRS_P2_03_Obj_YPos 250;
BA_ "GenSigStartValue" SG_ 35 FRS_P2_03_Obj_XVelRel 1024;
BA_ "GenSigTimeoutValue" SG_ 35 FRS_P2_03_Obj_XVelRel 250;
BA_ "GenSigTimeoutValue" SG_ 35 FRS_P2_03_Obj_XPos 250;
BA_ "GenSigTimeoutValue" SG_ 35 FRS_P2_03_Obj_Type 250;
BA_ "GenSigTimeoutValue" SG_ 35 FRS_P2_03_Obj_MeasFlag 250;
BA_ "GenSigTimeoutValue" SG_ 35 FRS_P2_03_Msg_AliveCounter 250;
BA_ "GenSigTimeoutValue" SG_ 35 FRS_P2_03_Msg_CheckSum 250;
BA_ "GenSigStartValue" SG_ 34 FRS_P2_02_Obj_YVelRel 1024;
BA_ "GenSigTimeoutValue" SG_ 34 FRS_P2_02_Obj_YVelRel 250;
BA_ "GenSigStartValue" SG_ 34 FRS_P2_02_Obj_YPos 4096;
BA_ "GenSigTimeoutValue" SG_ 34 FRS_P2_02_Obj_YPos 250;
BA_ "GenSigStartValue" SG_ 34 FRS_P2_02_Obj_XVelRel 1024;
BA_ "GenSigTimeoutValue" SG_ 34 FRS_P2_02_Obj_XVelRel 250;
BA_ "GenSigTimeoutValue" SG_ 34 FRS_P2_02_Obj_XPos 250;
BA_ "GenSigTimeoutValue" SG_ 34 FRS_P2_02_Obj_Type 250;
BA_ "GenSigTimeoutValue" SG_ 34 FRS_P2_02_Obj_MeasFlag 250;
BA_ "GenSigTimeoutValue" SG_ 34 FRS_P2_02_Msg_AliveCounter 250;
BA_ "GenSigTimeoutValue" SG_ 34 FRS_P2_02_Msg_CheckSum 250;
BA_ "GenSigStartValue" SG_ 33 FRS_P2_01_Obj_YVelRel 1024;
BA_ "GenSigTimeoutValue" SG_ 33 FRS_P2_01_Obj_YVelRel 250;
BA_ "GenSigStartValue" SG_ 33 FRS_P2_01_Obj_YPos 4096;
BA_ "GenSigTimeoutValue" SG_ 33 FRS_P2_01_Obj_YPos 250;
BA_ "GenSigStartValue" SG_ 33 FRS_P2_01_Obj_XVelRel 1024;
BA_ "GenSigTimeoutValue" SG_ 33 FRS_P2_01_Obj_XVelRel 250;
BA_ "GenSigTimeoutValue" SG_ 33 FRS_P2_01_Obj_XPos 250;
BA_ "GenSigTimeoutValue" SG_ 33 FRS_P2_01_Obj_Type 250;
BA_ "GenSigTimeoutValue" SG_ 33 FRS_P2_01_Obj_MeasFlag 250;
BA_ "GenSigTimeoutValue" SG_ 33 FRS_P2_01_Msg_AliveCounter 250;
BA_ "GenSigTimeoutValue" SG_ 33 FRS_P2_01_Msg_CheckSum 250;
BA_ "GenSigTimeoutValue" SG_ 119 FRS_P1_39_Msg_AliveCounter 250;
BA_ "GenSigTimeoutValue" SG_ 119 FRS_P1_39_Msg_CheckSum 250;
BA_ "GenSigTimeoutValue" SG_ 119 FRS_P1_39_Obj_MotionPattern 250;
BA_ "GenSigTimeoutValue" SG_ 119 FRS_P1_39_Obj_YPos_Stdev 250;
BA_ "GenSigTimeoutValue" SG_ 119 FRS_P1_39_Obj_XVelRel_Stdev 250;
BA_ "GenSigTimeoutValue" SG_ 119 FRS_P1_39_Obj_XPos_Stdev 250;
BA_ "GenSigStartValue" SG_ 119 FRS_P1_39_Obj_XAccRel 64;
BA_ "GenSigTimeoutValue" SG_ 119 FRS_P1_39_Obj_XAccRel 250;
BA_ "GenSigTimeoutValue" SG_ 119 FRS_P1_39_Obj_ValidFlag 250;
BA_ "GenSigTimeoutValue" SG_ 119 FRS_P1_39_Obj_UpdateFlag 250;
BA_ "GenSigTimeoutValue" SG_ 119 FRS_P1_39_Obj_ObstacleProb 250;
BA_ "GenSigTimeoutValue" SG_ 119 FRS_P1_39_Obj_ID 250;
BA_ "GenSigTimeoutValue" SG_ 119 FRS_P1_39_Obj_ExstProb 250;
BA_ "GenSigTimeoutValue" SG_ 118 FRS_P1_38_Msg_AliveCounter 250;
BA_ "GenSigTimeoutValue" SG_ 118 FRS_P1_38_Msg_CheckSum 250;
BA_ "GenSigTimeoutValue" SG_ 118 FRS_P1_38_Obj_MotionPattern 250;
BA_ "GenSigTimeoutValue" SG_ 118 FRS_P1_38_Obj_YPos_Stdev 250;
BA_ "GenSigTimeoutValue" SG_ 118 FRS_P1_38_Obj_XVelRel_Stdev 250;
BA_ "GenSigTimeoutValue" SG_ 118 FRS_P1_38_Obj_XPos_Stdev 250;
BA_ "GenSigStartValue" SG_ 118 FRS_P1_38_Obj_XAccRel 64;
BA_ "GenSigTimeoutValue" SG_ 118 FRS_P1_38_Obj_XAccRel 250;
BA_ "GenSigTimeoutValue" SG_ 118 FRS_P1_38_Obj_ValidFlag 250;
BA_ "GenSigTimeoutValue" SG_ 118 FRS_P1_38_Obj_UpdateFlag 250;
BA_ "GenSigTimeoutValue" SG_ 118 FRS_P1_38_Obj_ObstacleProb 250;
BA_ "GenSigTimeoutValue" SG_ 118 FRS_P1_38_Obj_ID 250;
BA_ "GenSigTimeoutValue" SG_ 118 FRS_P1_38_Obj_ExstProb 250;
BA_ "GenSigTimeoutValue" SG_ 117 FRS_P1_37_Msg_AliveCounter 250;
BA_ "GenSigTimeoutValue" SG_ 117 FRS_P1_37_Msg_CheckSum 250;
BA_ "GenSigTimeoutValue" SG_ 117 FRS_P1_37_Obj_MotionPattern 250;
BA_ "GenSigTimeoutValue" SG_ 117 FRS_P1_37_Obj_YPos_Stdev 250;
BA_ "GenSigTimeoutValue" SG_ 117 FRS_P1_37_Obj_XVelRel_Stdev 250;
BA_ "GenSigTimeoutValue" SG_ 117 FRS_P1_37_Obj_XPos_Stdev 250;
BA_ "GenSigStartValue" SG_ 117 FRS_P1_37_Obj_XAccRel 64;
BA_ "GenSigTimeoutValue" SG_ 117 FRS_P1_37_Obj_XAccRel 250;
BA_ "GenSigTimeoutValue" SG_ 117 FRS_P1_37_Obj_ValidFlag 250;
BA_ "GenSigTimeoutValue" SG_ 117 FRS_P1_37_Obj_UpdateFlag 250;
BA_ "GenSigTimeoutValue" SG_ 117 FRS_P1_37_Obj_ObstacleProb 250;
BA_ "GenSigTimeoutValue" SG_ 117 FRS_P1_37_Obj_ID 250;
BA_ "GenSigTimeoutValue" SG_ 117 FRS_P1_37_Obj_ExstProb 250;
BA_ "GenSigTimeoutValue" SG_ 116 FRS_P1_36_Msg_AliveCounter 250;
BA_ "GenSigTimeoutValue" SG_ 116 FRS_P1_36_Msg_CheckSum 250;
BA_ "GenSigTimeoutValue" SG_ 116 FRS_P1_36_Obj_MotionPattern 250;
BA_ "GenSigTimeoutValue" SG_ 116 FRS_P1_36_Obj_YPos_Stdev 250;
BA_ "GenSigTimeoutValue" SG_ 116 FRS_P1_36_Obj_XVelRel_Stdev 250;
BA_ "GenSigTimeoutValue" SG_ 116 FRS_P1_36_Obj_XPos_Stdev 250;
BA_ "GenSigStartValue" SG_ 116 FRS_P1_36_Obj_XAccRel 64;
BA_ "GenSigTimeoutValue" SG_ 116 FRS_P1_36_Obj_XAccRel 250;
BA_ "GenSigTimeoutValue" SG_ 116 FRS_P1_36_Obj_ValidFlag 250;
BA_ "GenSigTimeoutValue" SG_ 116 FRS_P1_36_Obj_UpdateFlag 250;
BA_ "GenSigTimeoutValue" SG_ 116 FRS_P1_36_Obj_ObstacleProb 250;
BA_ "GenSigTimeoutValue" SG_ 116 FRS_P1_36_Obj_ID 250;
BA_ "GenSigTimeoutValue" SG_ 116 FRS_P1_36_Obj_ExstProb 250;
BA_ "GenSigTimeoutValue" SG_ 115 FRS_P1_35_Msg_AliveCounter 250;
BA_ "GenSigTimeoutValue" SG_ 115 FRS_P1_35_Msg_CheckSum 250;
BA_ "GenSigTimeoutValue" SG_ 115 FRS_P1_35_Obj_MotionPattern 250;
BA_ "GenSigTimeoutValue" SG_ 115 FRS_P1_35_Obj_YPos_Stdev 250;
BA_ "GenSigTimeoutValue" SG_ 115 FRS_P1_35_Obj_XVelRel_Stdev 250;
BA_ "GenSigTimeoutValue" SG_ 115 FRS_P1_35_Obj_XPos_Stdev 250;
BA_ "GenSigStartValue" SG_ 115 FRS_P1_35_Obj_XAccRel 64;
BA_ "GenSigTimeoutValue" SG_ 115 FRS_P1_35_Obj_XAccRel 250;
BA_ "GenSigTimeoutValue" SG_ 115 FRS_P1_35_Obj_ValidFlag 250;
BA_ "GenSigTimeoutValue" SG_ 115 FRS_P1_35_Obj_UpdateFlag 250;
BA_ "GenSigTimeoutValue" SG_ 115 FRS_P1_35_Obj_ObstacleProb 250;
BA_ "GenSigTimeoutValue" SG_ 115 FRS_P1_35_Obj_ID 250;
BA_ "GenSigTimeoutValue" SG_ 115 FRS_P1_35_Obj_ExstProb 250;
BA_ "GenSigTimeoutValue" SG_ 114 FRS_P1_34_Msg_AliveCounter 250;
BA_ "GenSigTimeoutValue" SG_ 114 FRS_P1_34_Msg_CheckSum 250;
BA_ "GenSigTimeoutValue" SG_ 114 FRS_P1_34_Obj_MotionPattern 250;
BA_ "GenSigTimeoutValue" SG_ 114 FRS_P1_34_Obj_YPos_Stdev 250;
BA_ "GenSigTimeoutValue" SG_ 114 FRS_P1_34_Obj_XVelRel_Stdev 250;
BA_ "GenSigTimeoutValue" SG_ 114 FRS_P1_34_Obj_XPos_Stdev 250;
BA_ "GenSigStartValue" SG_ 114 FRS_P1_34_Obj_XAccRel 64;
BA_ "GenSigTimeoutValue" SG_ 114 FRS_P1_34_Obj_XAccRel 250;
BA_ "GenSigTimeoutValue" SG_ 114 FRS_P1_34_Obj_ValidFlag 250;
BA_ "GenSigTimeoutValue" SG_ 114 FRS_P1_34_Obj_UpdateFlag 250;
BA_ "GenSigTimeoutValue" SG_ 114 FRS_P1_34_Obj_ObstacleProb 250;
BA_ "GenSigTimeoutValue" SG_ 114 FRS_P1_34_Obj_ID 250;
BA_ "GenSigTimeoutValue" SG_ 114 FRS_P1_34_Obj_ExstProb 250;
BA_ "GenSigTimeoutValue" SG_ 113 FRS_P1_33_Msg_AliveCounter 250;
BA_ "GenSigTimeoutValue" SG_ 113 FRS_P1_33_Msg_CheckSum 250;
BA_ "GenSigTimeoutValue" SG_ 113 FRS_P1_33_Obj_MotionPattern 250;
BA_ "GenSigTimeoutValue" SG_ 113 FRS_P1_33_Obj_YPos_Stdev 250;
BA_ "GenSigTimeoutValue" SG_ 113 FRS_P1_33_Obj_XVelRel_Stdev 250;
BA_ "GenSigTimeoutValue" SG_ 113 FRS_P1_33_Obj_XPos_Stdev 250;
BA_ "GenSigStartValue" SG_ 113 FRS_P1_33_Obj_XAccRel 64;
BA_ "GenSigTimeoutValue" SG_ 113 FRS_P1_33_Obj_XAccRel 250;
BA_ "GenSigTimeoutValue" SG_ 113 FRS_P1_33_Obj_ValidFlag 250;
BA_ "GenSigTimeoutValue" SG_ 113 FRS_P1_33_Obj_UpdateFlag 250;
BA_ "GenSigTimeoutValue" SG_ 113 FRS_P1_33_Obj_ObstacleProb 250;
BA_ "GenSigTimeoutValue" SG_ 113 FRS_P1_33_Obj_ID 250;
BA_ "GenSigTimeoutValue" SG_ 113 FRS_P1_33_Obj_ExstProb 250;
VAL_ 91 FRS_P1_11_Obj_MotionPattern 0 "UNKNOWN" 1 "STATIONARY" 2 "STOPPED" 3 "MOVING" 4 "CROSSL" 5 "ONCOMING" 6 "CROSSR" 7 "HIGHTAR" ;
VAL_ 91 FRS_P1_11_Obj_ValidFlag 0 "OBJECT_INVALID" 1 "OBJECT_VALID" ;
VAL_ 91 FRS_P1_11_Obj_UpdateFlag 0 "NEW_OBJECT_INTHE_CYCLE" 1 "OBJECT_EXISTED_IN_PREVIOUS_CYCLE" ;
VAL_ 91 FRS_P1_11_Obj_ID 255 "INVALID" ;
VAL_ 71 FRS_P2_39_Obj_Type 0 "UNKNOWN" 1 "FOUR_WHEELER" 2 "TWO_WHEELER" 3 "PEDESTRAIN" ;
VAL_ 71 FRS_P2_39_Obj_MeasFlag 0 "OBJECT_MEASURED_INTHIS_CYCLE" 1 "OBJECT_EXTRAPOLATED_THIS_CYCLE" ;
VAL_ 70 FRS_P2_38_Obj_Type 0 "UNKNOWN" 1 "FOUR_WHEELER" 2 "TWO_WHEELER" 3 "PEDESTRAIN" ;
VAL_ 70 FRS_P2_38_Obj_MeasFlag 0 "OBJECT_MEASURED_INTHIS_CYCLE" 1 "OBJECT_EXTRAPOLATED_THIS_CYCLE" ;
VAL_ 69 FRS_P2_37_Obj_Type 0 "UNKNOWN" 1 "FOUR_WHEELER" 2 "TWO_WHEELER" 3 "PEDESTRAIN" ;
VAL_ 69 FRS_P2_37_Obj_MeasFlag 0 "OBJECT_MEASURED_INTHIS_CYCLE" 1 "OBJECT_EXTRAPOLATED_THIS_CYCLE" ;
VAL_ 68 FRS_P2_36_Obj_Type 0 "UNKNOWN" 1 "FOUR_WHEELER" 2 "TWO_WHEELER" 3 "PEDESTRAIN" ;
VAL_ 68 FRS_P2_36_Obj_MeasFlag 0 "OBJECT_MEASURED_INTHIS_CYCLE" 1 "OBJECT_EXTRAPOLATED_THIS_CYCLE" ;
VAL_ 67 FRS_P2_35_Obj_Type 0 "UNKNOWN" 1 "FOUR_WHEELER" 2 "TWO_WHEELER" 3 "PEDESTRAIN" ;
VAL_ 67 FRS_P2_35_Obj_MeasFlag 0 "OBJECT_MEASURED_INTHIS_CYCLE" 1 "OBJECT_EXTRAPOLATED_THIS_CYCLE" ;
VAL_ 66 FRS_P2_34_Obj_Type 0 "UNKNOWN" 1 "FOUR_WHEELER" 2 "TWO_WHEELER" 3 "PEDESTRAIN" ;
VAL_ 66 FRS_P2_34_Obj_MeasFlag 0 "OBJECT_MEASURED_INTHIS_CYCLE" 1 "OBJECT_EXTRAPOLATED_THIS_CYCLE" ;
VAL_ 65 FRS_P2_33_Obj_Type 0 "UNKNOWN" 1 "FOUR_WHEELER" 2 "TWO_WHEELER" 3 "PEDESTRAIN" ;
VAL_ 65 FRS_P2_33_Obj_MeasFlag 0 "OBJECT_MEASURED_INTHIS_CYCLE" 1 "OBJECT_EXTRAPOLATED_THIS_CYCLE" ;
VAL_ 64 FRS_P2_32_Obj_Type 0 "UNKNOWN" 1 "FOUR_WHEELER" 2 "TWO_WHEELER" 3 "PEDESTRAIN" ;
VAL_ 64 FRS_P2_32_Obj_MeasFlag 0 "OBJECT_MEASURED_INTHIS_CYCLE" 1 "OBJECT_EXTRAPOLATED_THIS_CYCLE" ;
VAL_ 63 FRS_P2_31_Obj_Type 0 "UNKNOWN" 1 "FOUR_WHEELER" 2 "TWO_WHEELER" 3 "PEDESTRAIN" ;
VAL_ 63 FRS_P2_31_Obj_MeasFlag 0 "OBJECT_MEASURED_INTHIS_CYCLE" 1 "OBJECT_EXTRAPOLATED_THIS_CYCLE" ;
VAL_ 62 FRS_P2_30_Obj_Type 0 "UNKNOWN" 1 "FOUR_WHEELER" 2 "TWO_WHEELER" 3 "PEDESTRAIN" ;
VAL_ 62 FRS_P2_30_Obj_MeasFlag 0 "OBJECT_MEASURED_INTHIS_CYCLE" 1 "OBJECT_EXTRAPOLATED_THIS_CYCLE" ;
VAL_ 61 FRS_P2_29_Obj_Type 0 "UNKNOWN" 1 "FOUR_WHEELER" 2 "TWO_WHEELER" 3 "PEDESTRAIN" ;
VAL_ 61 FRS_P2_29_Obj_MeasFlag 0 "OBJECT_MEASURED_INTHIS_CYCLE" 1 "OBJECT_EXTRAPOLATED_THIS_CYCLE" ;
VAL_ 60 FRS_P2_28_Obj_Type 0 "UNKNOWN" 1 "FOUR_WHEELER" 2 "TWO_WHEELER" 3 "PEDESTRAIN" ;
VAL_ 60 FRS_P2_28_Obj_MeasFlag 0 "OBJECT_MEASURED_INTHIS_CYCLE" 1 "OBJECT_EXTRAPOLATED_THIS_CYCLE" ;
VAL_ 59 FRS_P2_27_Obj_Type 0 "UNKNOWN" 1 "FOUR_WHEELER" 2 "TWO_WHEELER" 3 "PEDESTRAIN" ;
VAL_ 59 FRS_P2_27_Obj_MeasFlag 0 "OBJECT_MEASURED_INTHIS_CYCLE" 1 "OBJECT_EXTRAPOLATED_THIS_CYCLE" ;
VAL_ 58 FRS_P2_26_Obj_Type 0 "UNKNOWN" 1 "FOUR_WHEELER" 2 "TWO_WHEELER" 3 "PEDESTRAIN" ;
VAL_ 58 FRS_P2_26_Obj_MeasFlag 0 "OBJECT_MEASURED_INTHIS_CYCLE" 1 "OBJECT_EXTRAPOLATED_THIS_CYCLE" ;
VAL_ 57 FRS_P2_25_Obj_Type 0 "UNKNOWN" 1 "FOUR_WHEELER" 2 "TWO_WHEELER" 3 "PEDESTRAIN" ;
VAL_ 57 FRS_P2_25_Obj_MeasFlag 0 "OBJECT_MEASURED_INTHIS_CYCLE" 1 "OBJECT_EXTRAPOLATED_THIS_CYCLE" ;
VAL_ 56 FRS_P2_24_Obj_Type 0 "UNKNOWN" 1 "FOUR_WHEELER" 2 "TWO_WHEELER" 3 "PEDESTRAIN" ;
VAL_ 56 FRS_P2_24_Obj_MeasFlag 0 "OBJECT_MEASURED_INTHIS_CYCLE" 1 "OBJECT_EXTRAPOLATED_THIS_CYCLE" ;
VAL_ 55 FRS_P2_23_Obj_Type 0 "UNKNOWN" 1 "FOUR_WHEELER" 2 "TWO_WHEELER" 3 "PEDESTRAIN" ;
VAL_ 55 FRS_P2_23_Obj_MeasFlag 0 "OBJECT_MEASURED_INTHIS_CYCLE" 1 "OBJECT_EXTRAPOLATED_THIS_CYCLE" ;
VAL_ 54 FRS_P2_22_Obj_Type 0 "UNKNOWN" 1 "FOUR_WHEELER" 2 "TWO_WHEELER" 3 "PEDESTRAIN" ;
VAL_ 54 FRS_P2_22_Obj_MeasFlag 0 "OBJECT_MEASURED_INTHIS_CYCLE" 1 "OBJECT_EXTRAPOLATED_THIS_CYCLE" ;
VAL_ 53 FRS_P2_21_Obj_Type 0 "UNKNOWN" 1 "FOUR_WHEELER" 2 "TWO_WHEELER" 3 "PEDESTRAIN" ;
VAL_ 53 FRS_P2_21_Obj_MeasFlag 0 "OBJECT_MEASURED_INTHIS_CYCLE" 1 "OBJECT_EXTRAPOLATED_THIS_CYCLE" ;
VAL_ 52 FRS_P2_20_Obj_Type 0 "UNKNOWN" 1 "FOUR_WHEELER" 2 "TWO_WHEELER" 3 "PEDESTRAIN" ;
VAL_ 52 FRS_P2_20_Obj_MeasFlag 0 "OBJECT_MEASURED_INTHIS_CYCLE" 1 "OBJECT_EXTRAPOLATED_THIS_CYCLE" ;
VAL_ 51 FRS_P2_19_Obj_Type 0 "UNKNOWN" 1 "FOUR_WHEELER" 2 "TWO_WHEELER" 3 "PEDESTRAIN" ;
VAL_ 51 FRS_P2_19_Obj_MeasFlag 0 "OBJECT_MEASURED_INTHIS_CYCLE" 1 "OBJECT_EXTRAPOLATED_THIS_CYCLE" ;
VAL_ 50 FRS_P2_18_Obj_Type 0 "UNKNOWN" 1 "FOUR_WHEELER" 2 "TWO_WHEELER" 3 "PEDESTRAIN" ;
VAL_ 50 FRS_P2_18_Obj_MeasFlag 0 "OBJECT_MEASURED_INTHIS_CYCLE" 1 "OBJECT_EXTRAPOLATED_THIS_CYCLE" ;
VAL_ 49 FRS_P2_17_Obj_Type 0 "UNKNOWN" 1 "FOUR_WHEELER" 2 "TWO_WHEELER" 3 "PEDESTRAIN" ;
VAL_ 49 FRS_P2_17_Obj_MeasFlag 0 "OBJECT_MEASURED_INTHIS_CYCLE" 1 "OBJECT_EXTRAPOLATED_THIS_CYCLE" ;
VAL_ 48 FRS_P2_16_Obj_Type 0 "UNKNOWN" 1 "FOUR_WHEELER" 2 "TWO_WHEELER" 3 "PEDESTRAIN" ;
VAL_ 48 FRS_P2_16_Obj_MeasFlag 0 "OBJECT_MEASURED_INTHIS_CYCLE" 1 "OBJECT_EXTRAPOLATED_THIS_CYCLE" ;
VAL_ 47 FRS_P2_15_Obj_Type 0 "UNKNOWN" 1 "FOUR_WHEELER" 2 "TWO_WHEELER" 3 "PEDESTRAIN" ;
VAL_ 47 FRS_P2_15_Obj_MeasFlag 0 "OBJECT_MEASURED_INTHIS_CYCLE" 1 "OBJECT_EXTRAPOLATED_THIS_CYCLE" ;
VAL_ 46 FRS_P2_14_Obj_Type 0 "UNKNOWN" 1 "FOUR_WHEELER" 2 "TWO_WHEELER" 3 "PEDESTRAIN" ;
VAL_ 46 FRS_P2_14_Obj_MeasFlag 0 "OBJECT_MEASURED_INTHIS_CYCLE" 1 "OBJECT_EXTRAPOLATED_THIS_CYCLE" ;
VAL_ 45 FRS_P2_13_Obj_Type 0 "UNKNOWN" 1 "FOUR_WHEELER" 2 "TWO_WHEELER" 3 "PEDESTRAIN" ;
VAL_ 45 FRS_P2_13_Obj_MeasFlag 0 "OBJECT_MEASURED_INTHIS_CYCLE" 1 "OBJECT_EXTRAPOLATED_THIS_CYCLE" ;
VAL_ 44 FRS_P2_12_Obj_Type 0 "UNKNOWN" 1 "FOUR_WHEELER" 2 "TWO_WHEELER" 3 "PEDESTRAIN" ;
VAL_ 44 FRS_P2_12_Obj_MeasFlag 0 "OBJECT_MEASURED_INTHIS_CYCLE" 1 "OBJECT_EXTRAPOLATED_THIS_CYCLE" ;
VAL_ 43 FRS_P2_11_Obj_Type 0 "UNKNOWN" 1 "FOUR_WHEELER" 2 "TWO_WHEELER" 3 "PEDESTRAIN" ;
VAL_ 43 FRS_P2_11_Obj_MeasFlag 0 "OBJECT_MEASURED_INTHIS_CYCLE" 1 "OBJECT_EXTRAPOLATED_THIS_CYCLE" ;
VAL_ 42 FRS_P2_10_Obj_Type 0 "UNKNOWN" 1 "FOUR_WHEELER" 2 "TWO_WHEELER" 3 "PEDESTRAIN" ;
VAL_ 42 FRS_P2_10_Obj_MeasFlag 0 "OBJECT_MEASURED_INTHIS_CYCLE" 1 "OBJECT_EXTRAPOLATED_THIS_CYCLE" ;
VAL_ 41 FRS_P2_09_Obj_Type 0 "UNKNOWN" 1 "FOUR_WHEELER" 2 "TWO_WHEELER" 3 "PEDESTRAIN" ;
VAL_ 41 FRS_P2_09_Obj_MeasFlag 0 "OBJECT_MEASURED_INTHIS_CYCLE" 1 "OBJECT_EXTRAPOLATED_THIS_CYCLE" ;
VAL_ 40 FRS_P2_08_Obj_Type 0 "UNKNOWN" 1 "FOUR_WHEELER" 2 "TWO_WHEELER" 3 "PEDESTRAIN" ;
VAL_ 40 FRS_P2_08_Obj_MeasFlag 0 "OBJECT_MEASURED_INTHIS_CYCLE" 1 "OBJECT_EXTRAPOLATED_THIS_CYCLE" ;
VAL_ 39 FRS_P2_07_Obj_Type 0 "UNKNOWN" 1 "FOUR_WHEELER" 2 "TWO_WHEELER" 3 "PEDESTRAIN" ;
VAL_ 39 FRS_P2_07_Obj_MeasFlag 0 "OBJECT_MEASURED_INTHIS_CYCLE" 1 "OBJECT_EXTRAPOLATED_THIS_CYCLE" ;
VAL_ 38 FRS_P2_06_Obj_Type 0 "UNKNOWN" 1 "FOUR_WHEELER" 2 "TWO_WHEELER" 3 "PEDESTRAIN" ;
VAL_ 38 FRS_P2_06_Obj_MeasFlag 0 "OBJECT_MEASURED_INTHIS_CYCLE" 1 "OBJECT_EXTRAPOLATED_THIS_CYCLE" ;
VAL_ 37 FRS_P2_05_Obj_Type 0 "UNKNOWN" 1 "FOUR_WHEELER" 2 "TWO_WHEELER" 3 "PEDESTRAIN" ;
VAL_ 37 FRS_P2_05_Obj_MeasFlag 0 "OBJECT_MEASURED_INTHIS_CYCLE" 1 "OBJECT_EXTRAPOLATED_THIS_CYCLE" ;
VAL_ 36 FRS_P2_04_Obj_Type 0 "UNKNOWN" 1 "FOUR_WHEELER" 2 "TWO_WHEELER" 3 "PEDESTRAIN" ;
VAL_ 36 FRS_P2_04_Obj_MeasFlag 0 "OBJECT_MEASURED_INTHIS_CYCLE" 1 "OBJECT_EXTRAPOLATED_THIS_CYCLE" ;
VAL_ 35 FRS_P2_03_Obj_Type 0 "UNKNOWN" 1 "FOUR_WHEELER" 2 "TWO_WHEELER" 3 "PEDESTRAIN" ;
VAL_ 35 FRS_P2_03_Obj_MeasFlag 0 "OBJECT_MEASURED_INTHIS_CYCLE" 1 "OBJECT_EXTRAPOLATED_THIS_CYCLE" ;
VAL_ 34 FRS_P2_02_Obj_Type 0 "UNKNOWN" 1 "FOUR_WHEELER" 2 "TWO_WHEELER" 3 "PEDESTRAIN" ;
VAL_ 34 FRS_P2_02_Obj_MeasFlag 0 "OBJECT_MEASURED_INTHIS_CYCLE" 1 "OBJECT_EXTRAPOLATED_THIS_CYCLE" ;
VAL_ 33 FRS_P2_01_Obj_Type 0 "UNKNOWN" 1 "FOUR_WHEELER" 2 "TWO_WHEELER" 3 "PEDESTRAIN" ;
VAL_ 33 FRS_P2_01_Obj_MeasFlag 0 "OBJECT_MEASURED_INTHIS_CYCLE" 1 "OBJECT_EXTRAPOLATED_THIS_CYCLE" ;
VAL_ 119 FRS_P1_39_Obj_MotionPattern 0 "UNKNOWN" 1 "STATIONARY" 2 "STOPPED" 3 "MOVING" 4 "CROSSL" 5 "ONCOMING" 6 "CROSSR" 7 "HIGHTAR" ;
VAL_ 119 FRS_P1_39_Obj_ValidFlag 0 "OBJECT_INVALID" 1 "OBJECT_VALID" ;
VAL_ 119 FRS_P1_39_Obj_UpdateFlag 0 "NEW_OBJECT_INTHE_CYCLE" 1 "OBJECT_EXISTED_IN_PREVIOUS_CYCLE" ;
VAL_ 119 FRS_P1_39_Obj_ID 255 "INVALID" ;
VAL_ 118 FRS_P1_38_Obj_MotionPattern 0 "UNKNOWN" 1 "STATIONARY" 2 "STOPPED" 3 "MOVING" 4 "CROSSL" 5 "ONCOMING" 6 "CROSSR" 7 "HIGHTAR" ;
VAL_ 118 FRS_P1_38_Obj_ValidFlag 0 "OBJECT_INVALID" 1 "OBJECT_VALID" ;
VAL_ 118 FRS_P1_38_Obj_UpdateFlag 0 "NEW_OBJECT_INTHE_CYCLE" 1 "OBJECT_EXISTED_IN_PREVIOUS_CYCLE" ;
VAL_ 118 FRS_P1_38_Obj_ID 255 "INVALID" ;
VAL_ 117 FRS_P1_37_Obj_MotionPattern 0 "UNKNOWN" 1 "STATIONARY" 2 "STOPPED" 3 "MOVING" 4 "CROSSL" 5 "ONCOMING" 6 "CROSSR" 7 "HIGHTAR" ;
VAL_ 117 FRS_P1_37_Obj_ValidFlag 0 "OBJECT_INVALID" 1 "OBJECT_VALID" ;
VAL_ 117 FRS_P1_37_Obj_UpdateFlag 0 "NEW_OBJECT_INTHE_CYCLE" 1 "OBJECT_EXISTED_IN_PREVIOUS_CYCLE" ;
VAL_ 117 FRS_P1_37_Obj_ID 255 "INVALID" ;
VAL_ 116 FRS_P1_36_Obj_MotionPattern 0 "UNKNOWN" 1 "STATIONARY" 2 "STOPPED" 3 "MOVING" 4 "CROSSL" 5 "ONCOMING" 6 "CROSSR" 7 "HIGHTAR" ;
VAL_ 116 FRS_P1_36_Obj_ValidFlag 0 "OBJECT_INVALID" 1 "OBJECT_VALID" ;
VAL_ 116 FRS_P1_36_Obj_UpdateFlag 0 "NEW_OBJECT_INTHE_CYCLE" 1 "OBJECT_EXISTED_IN_PREVIOUS_CYCLE" ;
VAL_ 116 FRS_P1_36_Obj_ID 255 "INVALID" ;
VAL_ 115 FRS_P1_35_Obj_MotionPattern 0 "UNKNOWN" 1 "STATIONARY" 2 "STOPPED" 3 "MOVING" 4 "CROSSL" 5 "ONCOMING" 6 "CROSSR" 7 "HIGHTAR" ;
VAL_ 115 FRS_P1_35_Obj_ValidFlag 0 "OBJECT_INVALID" 1 "OBJECT_VALID" ;
VAL_ 115 FRS_P1_35_Obj_UpdateFlag 0 "NEW_OBJECT_INTHE_CYCLE" 1 "OBJECT_EXISTED_IN_PREVIOUS_CYCLE" ;
VAL_ 115 FRS_P1_35_Obj_ID 255 "INVALID" ;
VAL_ 114 FRS_P1_34_Obj_MotionPattern 0 "UNKNOWN" 1 "STATIONARY" 2 "STOPPED" 3 "MOVING" 4 "CROSSL" 5 "ONCOMING" 6 "CROSSR" 7 "HIGHTAR" ;
VAL_ 114 FRS_P1_34_Obj_ValidFlag 0 "OBJECT_INVALID" 1 "OBJECT_VALID" ;
VAL_ 114 FRS_P1_34_Obj_UpdateFlag 0 "NEW_OBJECT_INTHE_CYCLE" 1 "OBJECT_EXISTED_IN_PREVIOUS_CYCLE" ;
VAL_ 114 FRS_P1_34_Obj_ID 255 "INVALID" ;
VAL_ 113 FRS_P1_33_Obj_MotionPattern 0 "UNKNOWN" 1 "STATIONARY" 2 "STOPPED" 3 "MOVING" 4 "CROSSL" 5 "ONCOMING" 6 "CROSSR" 7 "HIGHTAR" ;
VAL_ 113 FRS_P1_33_Obj_ValidFlag 0 "OBJECT_INVALID" 1 "OBJECT_VALID" ;
VAL_ 113 FRS_P1_33_Obj_UpdateFlag 0 "NEW_OBJECT_INTHE_CYCLE" 1 "OBJECT_EXISTED_IN_PREVIOUS_CYCLE" ;
VAL_ 113 FRS_P1_33_Obj_ID 255 "INVALID" ;
